VERSION ""

NS_ :

BS_:

BU_: WPC2 RLPSU DPSU APSU PSB SHVU_RR vHS_B2 FCS EMCU SLB ARS RCM CGW_CCU vDummy_HS_B ATS RLHV SGU PFSU ALBCU DSAU SWRC SHVU_FR RCS RRPSU BLTN_CAM SCM DLBCU OHCL RWPC RRHV WPC HOD ASAU

BO_ 1279 HU_USM_E_10: 8 CGW_CCU
 SG_ USM_SmartRegen_Map_Set : 11|2@1+ (1,0) [0|0] "" Vector__XXX
 SG_ USM_SmartRegen_Sens_Set : 13|3@1+ (1,0) [0|0] "" Vector__XXX
 SG_ AVN_SeatPosMemory_Btn : 16|3@1+ (1,0) [0|0] "" Vector__XXX
 SG_ AVN_SeatPosPlyBck_Btn : 19|3@1+ (1,0) [0|0] ""  DPSU
 SG_ USM_RhstaLvlEnaSetReq : 22|2@1+ (1,0) [0|0] "" Vector__XXX
 SG_ USM_CMSDayBrgtnsLvlLHSetReq : 24|4@1+ (1,0) [0|0] "" Vector__XXX
 SG_ USM_CMSNgtBrgtnsLvlLHSetReq : 28|4@1+ (1,0) [0|0] "" Vector__XXX
 SG_ USM_CMSDayBrgtnsLvlRHSetReq : 32|4@1+ (1,0) [0|0] "" Vector__XXX
 SG_ USM_CMSNgtBrgtnsLvlRHSetReq : 36|4@1+ (1,0) [0|0] "" Vector__XXX
 SG_ USM_CMSBrgtnsReset : 40|2@1+ (1,0) [0|0] "" Vector__XXX
 SG_ USM_TurnDistLnDispSetReq : 42|2@1+ (1,0) [0|0] "" Vector__XXX
 SG_ PCA_FrSd_NValueSet : 44|2@1+ (1,0) [0|0] "" Vector__XXX
 SG_ CF_AVN_1stRrStRmndNValueSet : 46|2@1+ (1,0) [0|0] "" Vector__XXX
 SG_ C_AllDrOpnNValueSet : 52|3@1+ (1,0) [0|0] "" Vector__XXX
 SG_ USM_RpmECOSet : 55|2@1+ (1,0) [0|0] "" Vector__XXX
 SG_ VESS_ChgGuideMdLvl : 57|3@1+ (1,0) [0|0] "" Vector__XXX
 SG_ Usm_RpmSPORTSet : 60|2@1+ (1,0) [0|0] "" Vector__XXX

BO_ 2328016129 VCU_05_100ms_1: 8 CGW_CCU
 SG_ VCU_Crc5Val : 0|16@1+ (1,0) [0|0] "" Vector__XXX
 SG_ VCU_AlvCnt5Val : 16|8@1+ (1,0) [0|0] "" Vector__XXX
 SG_ VCU_EvDrvRdyCluDispSta : 24|2@1+ (1,0) [0|3] ""  SWRC
 SG_ VCU_PwrDnModeSta : 26|2@1+ (1,0) [0|3] "" Vector__XXX
 SG_ VCU_CluWarnMsgSta : 28|4@1+ (1,0) [0|15] "" Vector__XXX
 SG_ VCU_DteOffDispSta : 32|2@1+ (1,0) [0|0] "flag" Vector__XXX
 SG_ VCU_LowSocAlertSta : 34|3@1+ (1,0) [0|7] "" Vector__XXX
 SG_ VCU_VcrmReq : 38|2@1+ (1,0) [0|3] "" Vector__XXX
 SG_ VCU_PdlWarnMsgSta : 40|2@1+ (1,0) [0|3] "" Vector__XXX
 SG_ VCU_AwdDiagDispSta : 42|2@1+ (1,0) [0|0] "" Vector__XXX
 SG_ VCU_AwdLockDispSta : 44|2@1+ (1,0) [0|0] "" Vector__XXX
 SG_ VCU_VirtualApsActSta : 46|2@1+ (1,0) [0|3] "" Vector__XXX
 SG_ VCU_VirtualApsVal : 48|8@1+ (0.3906,0) [0|99.61] "%" Vector__XXX
 SG_ VCU_ServiceLampReq : 56|2@1+ (1,0) [0|3] "" Vector__XXX
 SG_ VCU_ServiceModeSta : 58|2@1+ (1,0) [0|3] "" Vector__XXX
 SG_ VCU_NPosWshModSta : 60|2@1+ (1,0) [0|0] "flag" Vector__XXX
 SG_ VCU_PowerTrainType : 62|2@1+ (1,0) [0|3] "" Vector__XXX

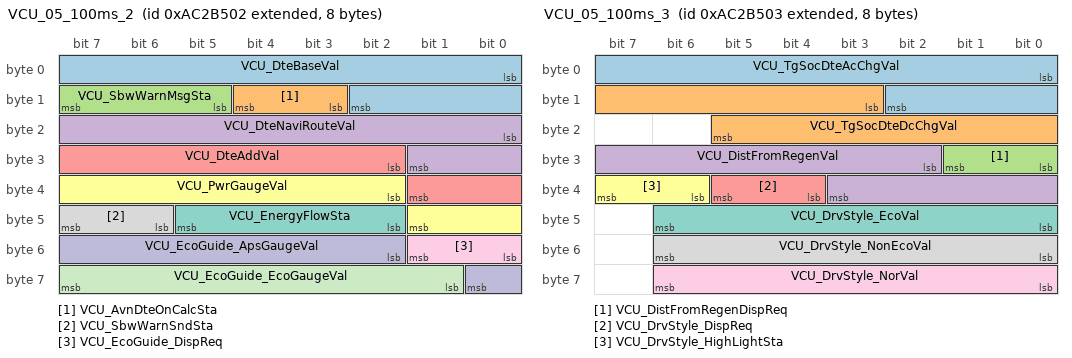
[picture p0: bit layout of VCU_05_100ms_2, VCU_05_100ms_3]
BO_ 2328016130 VCU_05_100ms_2: 8 CGW_CCU
 SG_ VCU_DteBaseVal : 0|11@1+ (1,0) [0|2047] "km" Vector__XXX
 SG_ VCU_AvnDteOnCalcSta : 11|2@1+ (1,0) [0|3] "" Vector__XXX
 SG_ VCU_SbwWarnMsgSta : 13|3@1+ (1,0) [0|0] "flag" Vector__XXX
 SG_ VCU_DteNaviRouteVal : 16|10@1+ (2,0) [0|1026] "km" Vector__XXX
 SG_ VCU_DteAddVal : 26|8@1+ (1,0) [0|255] "km" Vector__XXX
 SG_ VCU_PwrGaugeVal : 34|8@1- (1,0) [-100|100] "%" Vector__XXX
 SG_ VCU_EnergyFlowSta : 42|4@1+ (1,0) [0|15] "" Vector__XXX
 SG_ VCU_SbwWarnSndSta : 46|2@1+ (1,0) [0|0] "flag" Vector__XXX
 SG_ VCU_EcoGuide_DispReq : 48|2@1+ (1,0) [0|3] "" Vector__XXX
 SG_ VCU_EcoGuide_ApsGaugeVal : 50|7@1+ (1,0) [0|100] "%" Vector__XXX
 SG_ VCU_EcoGuide_EcoGaugeVal : 57|7@1+ (1,0) [0|100] "%" Vector__XXX

BO_ 2328016131 VCU_05_100ms_3: 8 CGW_CCU
 SG_ VCU_TgSocDteAcChgVal : 0|11@1+ (1,0) [0|2047] "km" Vector__XXX
 SG_ VCU_TgSocDteDcChgVal : 11|11@1+ (1,0) [0|2047] "km" Vector__XXX
 SG_ VCU_DistFromRegenDispReq : 24|2@1+ (1,0) [0|3] "" Vector__XXX
 SG_ VCU_DistFromRegenVal : 26|10@1+ (10,0) [0|10230] "m" Vector__XXX
 SG_ VCU_DrvStyle_DispReq : 36|2@1+ (1,0) [0|3] "" Vector__XXX
 SG_ VCU_DrvStyle_HighLightSta : 38|2@1+ (1,0) [0|3] "" Vector__XXX
 SG_ VCU_DrvStyle_EcoVal : 40|7@1+ (1,0) [0|100] "%" Vector__XXX
 SG_ VCU_DrvStyle_NonEcoVal : 48|7@1+ (1,0) [0|100] "%" Vector__XXX
 SG_ VCU_DrvStyle_NorVal : 56|7@1+ (1,0) [0|100] "%" Vector__XXX

BO_ 200 HU_USM_E_12: 8 CGW_CCU
 SG_ CF_AVN_ADrLNValueSet_2 : 0|3@1+ (1,0) [0|0] "" Vector__XXX
 SG_ CF_AVN_FCA_JC_OnOffEquipNvalueSe : 12|2@1+ (1,0) [0|0] "" Vector__XXX
 SG_ CF_AVN_FCA_FrSdOnOffEquipNvalueS : 14|2@1+ (1,0) [0|0] "" Vector__XXX
 SG_ CF_AVN_LKA_OnOffEquip2NvalueSet : 16|2@1+ (1,0) [0|0] "" Vector__XXX
 SG_ CF_AVN_BCA_OnOffEquip2NvalueSet : 18|2@1+ (1,0) [0|0] "" Vector__XXX
 SG_ CF_AVN_BVM_OnOffEquipNvalueSet : 20|2@1+ (1,0) [0|0] "" Vector__XXX
 SG_ CF_AVN_SEA_OnOffEquip3NvalueSet : 22|2@1+ (1,0) [0|0] "" Vector__XXX
 SG_ CF_AVN_BodySpprtSet_AST : 24|2@1+ (1,0) [0|0] ""  ALBCU
 SG_ CF_AVN_SEW_OnOffEquip3NvalueSet : 26|2@1+ (1,0) [0|0] "" Vector__XXX
 SG_ CF_AVN_HudImsAutoSave : 28|2@1+ (1,0) [0|0] "" Vector__XXX
 SG_ USM_PwrDrBuzzerNValueSet : 3|2@1+ (1,0) [0|0] "" Vector__XXX
 SG_ CF_AVN_DWLNValueSet : 30|3@1+ (1,0) [0|0] "" Vector__XXX
 SG_ CF_AVN_AirSptTimeNValueSet_AST : 33|3@1+ (1,0) [0|0] ""  ALBCU
 SG_ CF_AVN_AirSptStrNValue_AST : 36|2@1+ (1,0) [0|0] ""  ALBCU
 SG_ CF_AVN_SeatDrvModNvalueSet_AST : 38|2@1+ (1,0) [0|0] ""  ALBCU
 SG_ CF_AVN_TPMS_TireReplaceNValueSet : 40|3@1+ (1,0) [0|0] "" Vector__XXX
 SG_ CF_AVN_TowModeSet : 43|3@1+ (1,0) [0|0] "" Vector__XXX
 SG_ USM_PwrDrCloseByBraekNValueSet : 46|2@1+ (1,0) [0|0] "" Vector__XXX
 SG_ CF_AVN_ISLANAOffstNvalueSet : 50|3@1+ (1,0) [0|0] "" Vector__XXX
 SG_ CF_Gway_WPC2_NValueSet : 53|2@1+ (1,0) [0|0] ""  WPC2
 SG_ USM_DrvGhostDoorReq : 56|2@1+ (1,0) [0|0] "" Vector__XXX
 SG_ USM_AstGhostDoorReq : 58|2@1+ (1,0) [0|0] "" Vector__XXX
 SG_ USM_RLGhostDoorReq : 60|2@1+ (1,0) [0|0] "" Vector__XXX
 SG_ USM_RRGhostDoorReq : 62|2@1+ (1,0) [0|0] "" Vector__XXX
 SG_ CF_AVN_FCA_FrOnOffEquipNvalueSet : 7|2@1+ (1,0) [0|0] "" Vector__XXX
 SG_ CF_AVN_FCA_WarnTimeNvalueSet : 9|3@1+ (1,0) [0|0] "" Vector__XXX

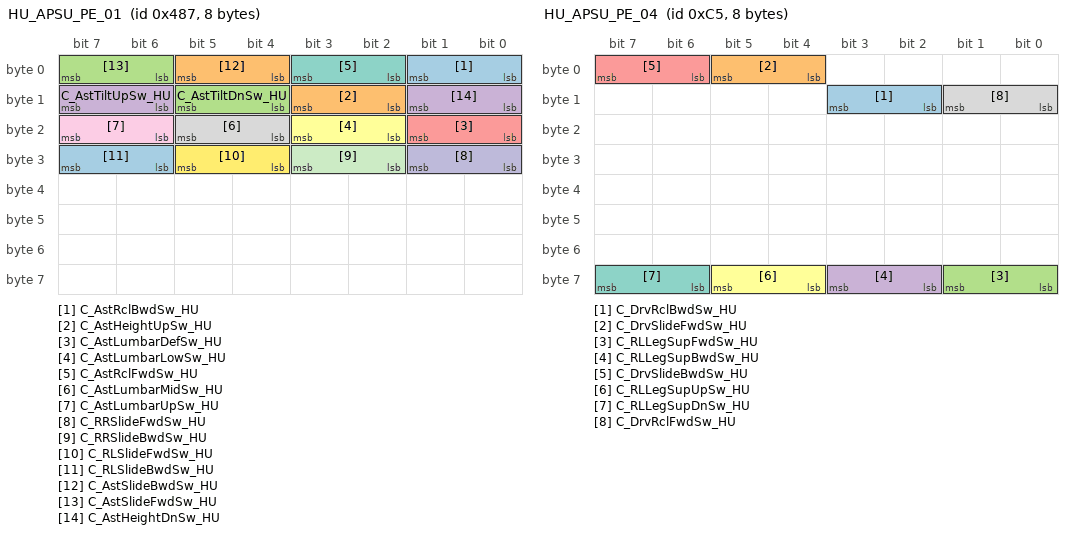
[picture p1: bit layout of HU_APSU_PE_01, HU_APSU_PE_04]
BO_ 1159 HU_APSU_PE_01: 8 CGW_CCU
 SG_ C_AstRclBwdSw_HU : 0|2@1+ (1,0) [0|0] ""  APSU
 SG_ C_AstHeightUpSw_HU : 10|2@1+ (1,0) [0|0] ""  APSU
 SG_ C_AstTiltDnSw_HU : 12|2@1+ (1,0) [0|0] ""  APSU
 SG_ C_AstTiltUpSw_HU : 14|2@1+ (1,0) [0|0] ""  APSU
 SG_ C_AstLumbarDefSw_HU : 16|2@1+ (1,0) [0|0] ""  ASAU,ALBCU
 SG_ C_AstLumbarLowSw_HU : 18|2@1+ (1,0) [0|0] ""  ASAU,ALBCU
 SG_ C_AstRclFwdSw_HU : 2|2@1+ (1,0) [0|0] ""  APSU
 SG_ C_AstLumbarMidSw_HU : 20|2@1+ (1,0) [0|0] ""  ASAU,ALBCU
 SG_ C_AstLumbarUpSw_HU : 22|2@1+ (1,0) [0|0] ""  ASAU,ALBCU
 SG_ C_RRSlideFwdSw_HU : 24|2@1+ (1,0) [0|0] ""  APSU,RRPSU
 SG_ C_RRSlideBwdSw_HU : 26|2@1+ (1,0) [0|0] ""  APSU,RRPSU
 SG_ C_RLSlideFwdSw_HU : 28|2@1+ (1,0) [0|0] ""  APSU,RRPSU,RLPSU
 SG_ C_RLSlideBwdSw_HU : 30|2@1+ (1,0) [0|0] ""  APSU,RRPSU,RLPSU
 SG_ C_AstSlideBwdSw_HU : 4|2@1+ (1,0) [0|0] ""  APSU
 SG_ C_AstSlideFwdSw_HU : 6|2@1+ (1,0) [0|0] ""  APSU
 SG_ C_AstHeightDnSw_HU : 8|2@1+ (1,0) [0|0] ""  APSU

BO_ 197 HU_APSU_PE_04: 8 CGW_CCU
 SG_ C_DrvRclBwdSw_HU : 10|2@1+ (1,0) [0|0] ""  DPSU
 SG_ C_DrvSlideFwdSw_HU : 4|2@1+ (1,0) [0|0] ""  DPSU
 SG_ C_RLLegSupFwdSw_HU : 56|2@1+ (1,0) [0|0] ""  APSU,RLPSU
 SG_ C_RLLegSupBwdSw_HU : 58|2@1+ (1,0) [0|0] ""  APSU,RLPSU
 SG_ C_DrvSlideBwdSw_HU : 6|2@1+ (1,0) [0|0] ""  DPSU
 SG_ C_RLLegSupUpSw_HU : 60|2@1+ (1,0) [0|0] ""  APSU,RLPSU
 SG_ C_RLLegSupDnSw_HU : 62|2@1+ (1,0) [0|0] ""  APSU,RLPSU
 SG_ C_DrvRclFwdSw_HU : 8|2@1+ (1,0) [0|0] ""  DPSU

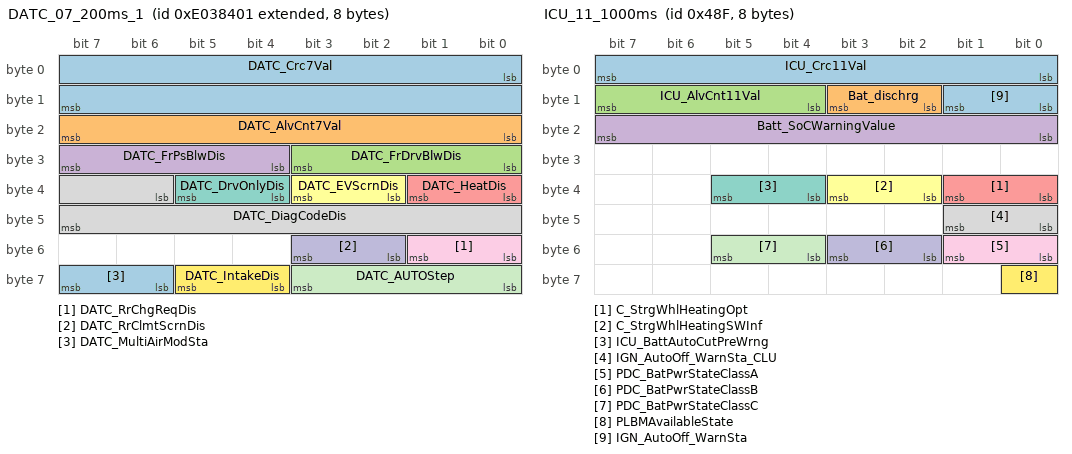
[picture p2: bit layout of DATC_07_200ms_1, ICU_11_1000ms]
BO_ 2382595073 DATC_07_200ms_1: 8 CGW_CCU
 SG_ DATC_Crc7Val : 0|16@1+ (1,0) [0|0] "" Vector__XXX
 SG_ DATC_AlvCnt7Val : 16|8@1+ (1,0) [0|0] "" Vector__XXX
 SG_ DATC_FrDrvBlwDis : 24|4@1+ (1,0) [0|0] ""  ATS
 SG_ DATC_FrPsBlwDis : 28|4@1+ (1,0) [0|0] ""  ATS
 SG_ DATC_HeatDis : 32|2@1+ (1,0) [0|0] "flag"  ATS
 SG_ DATC_EVScrnDis : 34|2@1+ (1,0) [0|0] "" Vector__XXX
 SG_ DATC_DrvOnlyDis : 36|2@1+ (1,0) [0|0] ""  ATS
 SG_ DATC_DiagCodeDis : 38|10@1+ (1,-1) [0|0] "" Vector__XXX
 SG_ DATC_RrChgReqDis : 48|2@1+ (1,0) [0|0] "" Vector__XXX
 SG_ DATC_RrClmtScrnDis : 50|2@1+ (1,0) [0|0] ""  ATS
 SG_ DATC_AUTOStep : 56|4@1+ (1,0) [0|0] ""  ATS
 SG_ DATC_IntakeDis : 60|2@1+ (1,0) [0|0] ""  ATS
 SG_ DATC_MultiAirModSta : 62|2@1+ (1,0) [0|0] "" Vector__XXX

BO_ 1167 ICU_11_1000ms: 8 CGW_CCU
 SG_ ICU_Crc11Val : 0|8@1+ (1,0) [0|0] "" Vector__XXX
 SG_ Bat_dischrg : 10|2@1+ (1,0) [0|0] "" Vector__XXX
 SG_ ICU_AlvCnt11Val : 12|4@1+ (1,0) [0|0] "" Vector__XXX
 SG_ Batt_SoCWarningValue : 16|8@1+ (1,0) [0|0] "%" Vector__XXX
 SG_ C_StrgWhlHeatingOpt : 32|2@1+ (1,0) [0|0] "" Vector__XXX
 SG_ C_StrgWhlHeatingSWInf : 34|2@1+ (1,0) [0|0] "" Vector__XXX
 SG_ ICU_BattAutoCutPreWrng : 36|2@1+ (1,0) [0|0] ""  BLTN_CAM
 SG_ IGN_AutoOff_WarnSta_CLU : 40|2@1+ (1,0) [0|0] "" Vector__XXX
 SG_ PDC_BatPwrStateClassA : 48|2@1+ (1,0) [0|0] "" Vector__XXX
 SG_ PDC_BatPwrStateClassB : 50|2@1+ (1,0) [0|0] "" Vector__XXX
 SG_ PDC_BatPwrStateClassC : 52|2@1+ (1,0) [0|0] "" Vector__XXX
 SG_ PLBMAvailableState : 56|1@1+ (1,0) [0|0] "" Vector__XXX
 SG_ IGN_AutoOff_WarnSta : 8|2@1+ (1,0) [0|0] "" Vector__XXX

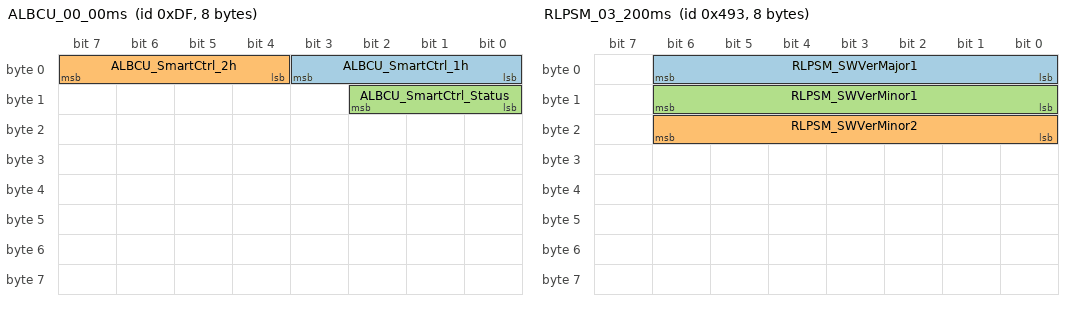
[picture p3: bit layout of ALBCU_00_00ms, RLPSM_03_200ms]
BO_ 223 ALBCU_00_00ms: 8 ALBCU
 SG_ ALBCU_SmartCtrl_1h : 0|4@1+ (1,0) [0|0] ""  CGW_CCU
 SG_ ALBCU_SmartCtrl_2h : 4|4@1+ (1,0) [0|0] ""  CGW_CCU
 SG_ ALBCU_SmartCtrl_Status : 8|3@1+ (1,0) [0|0] ""  CGW_CCU

BO_ 1171 RLPSM_03_200ms: 8 RLPSU
 SG_ RLPSM_SWVerMajor1 : 0|7@1+ (1,0) [0|0] "" Vector__XXX
 SG_ RLPSM_SWVerMinor2 : 16|7@1+ (1,0) [0|0] "" Vector__XXX
 SG_ RLPSM_SWVerMinor1 : 8|7@1+ (1,0) [0|0] "" Vector__XXX

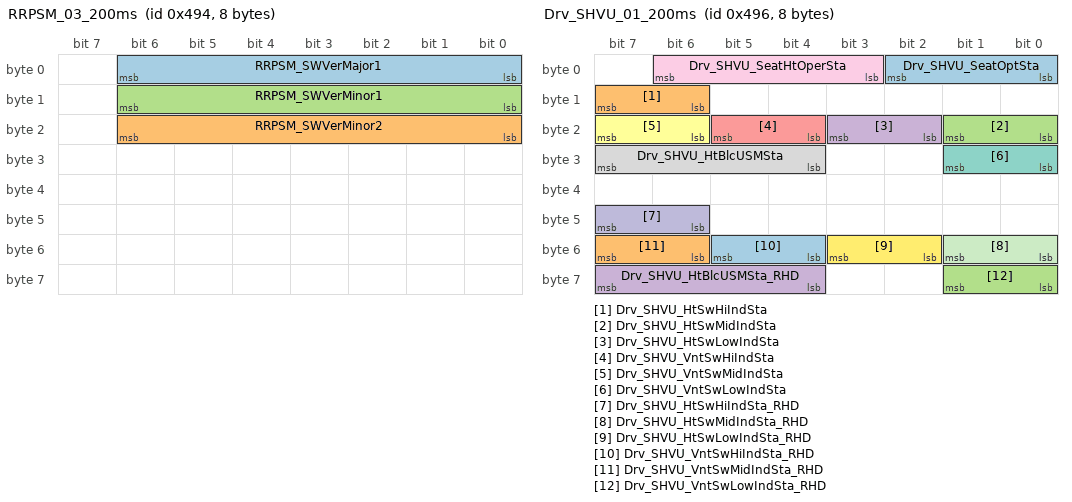
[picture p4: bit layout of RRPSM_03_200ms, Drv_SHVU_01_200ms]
BO_ 1172 RRPSM_03_200ms: 8 RRPSU
 SG_ RRPSM_SWVerMajor1 : 0|7@1+ (1,0) [0|0] "" Vector__XXX
 SG_ RRPSM_SWVerMinor2 : 16|7@1+ (1,0) [0|0] "" Vector__XXX
 SG_ RRPSM_SWVerMinor1 : 8|7@1+ (1,0) [0|0] "" Vector__XXX

BO_ 1174 Drv_SHVU_01_200ms: 8 DPSU
 SG_ Drv_SHVU_SeatOptSta : 0|3@1+ (1,0) [0|0] ""  FCS,CGW_CCU
 SG_ Drv_SHVU_HtSwHiIndSta : 14|2@1+ (1,0) [0|0] ""  FCS,CGW_CCU
 SG_ Drv_SHVU_HtSwMidIndSta : 16|2@1+ (1,0) [0|0] ""  FCS,CGW_CCU
 SG_ Drv_SHVU_HtSwLowIndSta : 18|2@1+ (1,0) [0|0] ""  FCS,CGW_CCU
 SG_ Drv_SHVU_VntSwHiIndSta : 20|2@1+ (1,0) [0|0] ""  FCS,CGW_CCU
 SG_ Drv_SHVU_VntSwMidIndSta : 22|2@1+ (1,0) [0|0] ""  FCS,CGW_CCU
 SG_ Drv_SHVU_VntSwLowIndSta : 24|2@1+ (1,0) [0|0] ""  FCS,CGW_CCU
 SG_ Drv_SHVU_HtBlcUSMSta : 28|4@1+ (1,0) [0|0] ""  CGW_CCU
 SG_ Drv_SHVU_SeatHtOperSta : 3|4@1+ (1,0) [0|0] ""  FCS,CGW_CCU
 SG_ Drv_SHVU_HtSwHiIndSta_RHD : 46|2@1+ (1,0) [0|0] ""  FCS,CGW_CCU
 SG_ Drv_SHVU_HtSwMidIndSta_RHD : 48|2@1+ (1,0) [0|0] ""  FCS,CGW_CCU
 SG_ Drv_SHVU_HtSwLowIndSta_RHD : 50|2@1+ (1,0) [0|0] ""  FCS,CGW_CCU
 SG_ Drv_SHVU_VntSwHiIndSta_RHD : 52|2@1+ (1,0) [0|0] ""  FCS,CGW_CCU
 SG_ Drv_SHVU_VntSwMidIndSta_RHD : 54|2@1+ (1,0) [0|0] ""  FCS,CGW_CCU
 SG_ Drv_SHVU_VntSwLowIndSta_RHD : 56|2@1+ (1,0) [0|0] ""  FCS,CGW_CCU
 SG_ Drv_SHVU_HtBlcUSMSta_RHD : 60|4@1+ (1,0) [0|0] "" Vector__XXX

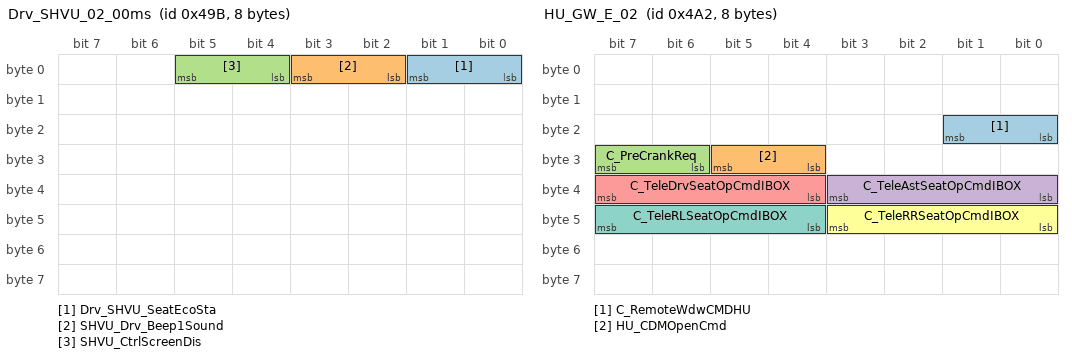
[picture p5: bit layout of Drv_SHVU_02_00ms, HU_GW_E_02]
BO_ 1179 Drv_SHVU_02_00ms: 8 SHVU_FR
 SG_ Drv_SHVU_SeatEcoSta : 0|2@1+ (1,0) [0|0] ""  CGW_CCU
 SG_ SHVU_Drv_Beep1Sound : 2|2@1+ (1,0) [0|0] ""  CGW_CCU
 SG_ SHVU_CtrlScreenDis : 4|2@1+ (1,0) [0|0] ""  CGW_CCU

BO_ 1180 Ast_SHVU_02_00ms: 8 SHVU_FR
 SG_ SHVU_Ast_Beep1Sound : 2|2@1+ (1,0) [0|0] ""  CGW_CCU
 SG_ Ast_SHVU_SeatEcoSta : 26|2@1+ (1,0) [0|0] ""  CGW_CCU

BO_ 208 RR_SHVU_03_200ms: 8 SHVU_RR
 SG_ RR_SHVU_DTCdisplay : 0|8@1+ (1,0) [0|0] ""  ATS
 SG_ RR_SHVU_DiagMode : 8|2@1+ (1,0) [0|0] ""  ATS

BO_ 1181 RL_SHVU_02_00ms: 8 RLHV
 SG_ RL_SHVU_SeatEcoSta : 0|2@1+ (1,0) [0|0] ""  ATS,CGW_CCU

BO_ 1182 RR_SHVU_02_00ms: 8 SHVU_RR
 SG_ RR_SHVU_SeatEcoSta : 0|2@1+ (1,0) [0|0] ""  ATS,CGW_CCU

BO_ 1186 HU_GW_E_02: 8 CGW_CCU
 SG_ C_RemoteWdwCMDHU : 16|2@1+ (1,0) [0|0] "" Vector__XXX
 SG_ HU_CDMOpenCmd : 28|2@1+ (1,0) [0|0] "" Vector__XXX
 SG_ C_PreCrankReq : 30|2@1+ (1,0) [0|0] ""  BLTN_CAM
 SG_ C_TeleAstSeatOpCmdIBOX : 32|4@1+ (1,0) [0|0] ""  APSU,SHVU_FR
 SG_ C_TeleDrvSeatOpCmdIBOX : 36|4@1+ (1,0) [0|0] ""  SHVU_FR,DPSU
 SG_ C_TeleRRSeatOpCmdIBOX : 40|4@1+ (1,0) [0|0] ""  RRHV,SHVU_FR,SHVU_RR,RRPSU,ATS
 SG_ C_TeleRLSeatOpCmdIBOX : 44|4@1+ (1,0) [0|0] ""  RLHV,SHVU_FR,SHVU_RR,RLPSU,ATS

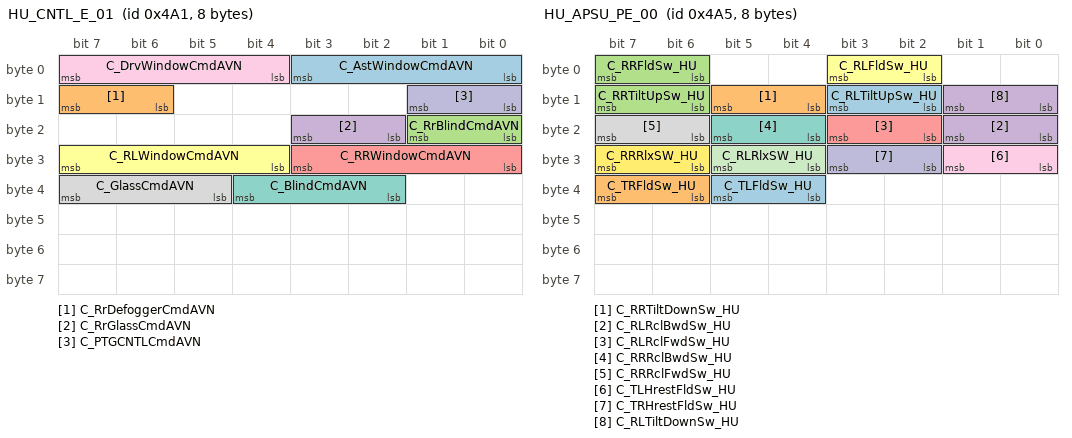
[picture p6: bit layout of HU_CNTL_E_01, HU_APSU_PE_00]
BO_ 1185 HU_CNTL_E_01: 8 CGW_CCU
 SG_ C_AstWindowCmdAVN : 0|4@1+ (1,0) [0|0] "" Vector__XXX
 SG_ C_RrDefoggerCmdAVN : 14|2@1+ (1,0) [0|0] "" Vector__XXX
 SG_ C_RrBlindCmdAVN : 16|2@1+ (1,0) [0|0] ""  RCM
 SG_ C_RrGlassCmdAVN : 18|2@1+ (1,0) [0|0] ""  RCM
 SG_ C_RRWindowCmdAVN : 24|4@1+ (1,0) [0|0] "" Vector__XXX
 SG_ C_RLWindowCmdAVN : 28|4@1+ (1,0) [0|0] "" Vector__XXX
 SG_ C_BlindCmdAVN : 34|3@1+ (1,0) [0|0] ""  RCM
 SG_ C_GlassCmdAVN : 37|3@1+ (1,0) [0|0] ""  RCM
 SG_ C_DrvWindowCmdAVN : 4|4@1+ (1,0) [0|0] "" Vector__XXX
 SG_ C_PTGCNTLCmdAVN : 8|2@1+ (1,0) [0|0] "" Vector__XXX

BO_ 1189 HU_APSU_PE_00: 8 CGW_CCU
 SG_ C_RLTiltUpSw_HU : 10|2@1+ (1,0) [0|0] ""  APSU,RRPSU,RLPSU
 SG_ C_RRTiltDownSw_HU : 12|2@1+ (1,0) [0|0] ""  APSU,RRPSU
 SG_ C_RRTiltUpSw_HU : 14|2@1+ (1,0) [0|0] ""  APSU,RRPSU
 SG_ C_RLRclBwdSw_HU : 16|2@1+ (1,0) [0|0] ""  APSU,RRPSU,RLPSU
 SG_ C_RLRclFwdSw_HU : 18|2@1+ (1,0) [0|0] ""  APSU,RRPSU,RLPSU
 SG_ C_RLFldSw_HU : 2|2@1+ (1,0) [0|0] ""  RLPSU
 SG_ C_RRRclBwdSw_HU : 20|2@1+ (1,0) [0|0] ""  APSU,RRPSU
 SG_ C_RRRclFwdSw_HU : 22|2@1+ (1,0) [0|0] ""  APSU,RRPSU
 SG_ C_TLHrestFldSw_HU : 24|2@1+ (1,0) [0|0] ""  PFSU
 SG_ C_TRHrestFldSw_HU : 26|2@1+ (1,0) [0|0] ""  PFSU
 SG_ C_RLRlxSW_HU : 28|2@1+ (1,0) [0|0] ""  RRPSU,RLPSU
 SG_ C_RRRlxSW_HU : 30|2@1+ (1,0) [0|0] ""  RRPSU
 SG_ C_TLFldSw_HU : 36|2@1+ (1,0) [0|0] ""  PFSU
 SG_ C_TRFldSw_HU : 38|2@1+ (1,0) [0|0] ""  PFSU
 SG_ C_RRFldSw_HU : 6|2@1+ (1,0) [0|0] ""  RRPSU
 SG_ C_RLTiltDownSw_HU : 8|2@1+ (1,0) [0|0] ""  APSU,RRPSU,RLPSU

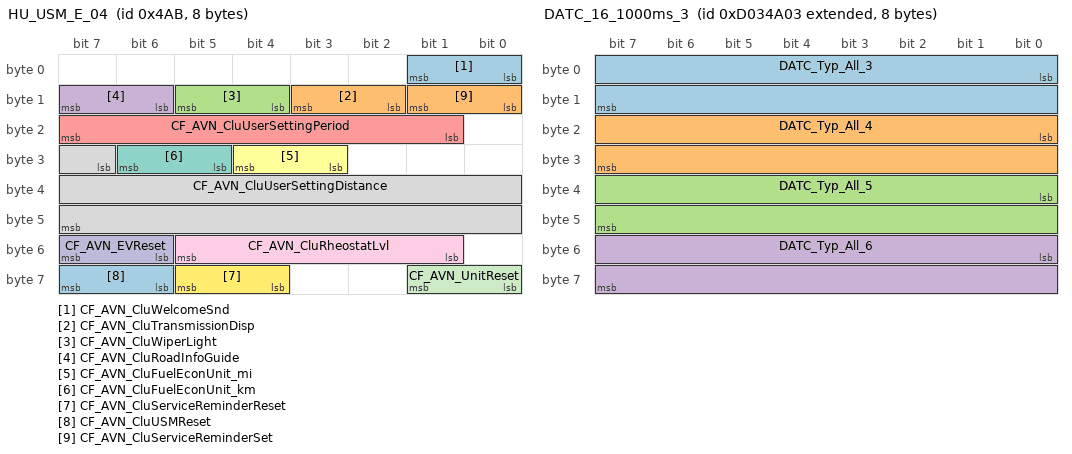
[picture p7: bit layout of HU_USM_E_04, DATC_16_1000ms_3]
BO_ 1195 HU_USM_E_04: 8 CGW_CCU
 SG_ CF_AVN_CluWelcomeSnd : 0|2@1+ (1,0) [0|0] "" Vector__XXX
 SG_ CF_AVN_CluTransmissionDisp : 10|2@1+ (1,0) [0|0] "" Vector__XXX
 SG_ CF_AVN_CluWiperLight : 12|2@1+ (1,0) [0|0] "" Vector__XXX
 SG_ CF_AVN_CluRoadInfoGuide : 14|2@1+ (1,0) [0|0] "" Vector__XXX
 SG_ CF_AVN_CluUserSettingPeriod : 17|7@1+ (1,0) [0|0] "" Vector__XXX
 SG_ CF_AVN_CluFuelEconUnit_mi : 27|2@1+ (1,0) [0|0] "" Vector__XXX
 SG_ CF_AVN_CluFuelEconUnit_km : 29|2@1+ (1,0) [0|0] "" Vector__XXX
 SG_ CF_AVN_CluUserSettingDistance : 31|17@1+ (1,0) [0|0] "" Vector__XXX
 SG_ CF_AVN_CluRheostatLvl : 49|5@1+ (1,0) [0|0] "" Vector__XXX
 SG_ CF_AVN_EVReset : 54|2@1+ (1,0) [0|0] "" Vector__XXX
 SG_ CF_AVN_UnitReset : 56|2@1+ (1,0) [0|0] "" Vector__XXX
 SG_ CF_AVN_CluServiceReminderReset : 60|2@1+ (1,0) [0|0] "" Vector__XXX
 SG_ CF_AVN_CluUSMReset : 62|2@1+ (1,0) [0|0] ""  WPC,RWPC,SLB,ARS,APSU,RLHV,RRHV,SHVU_FR,SHVU_RR,DPSU,DLBCU,PFSU,RRPSU,RLPSU,ATS,DSAU,ASAU,RCM,BLTN_CAM,SGU,ALBCU,WPC2
 SG_ CF_AVN_CluServiceReminderSet : 8|2@1+ (1,0) [0|0] "" Vector__XXX

BO_ 1193 HU_USM_E_02: 8 CGW_CCU
 SG_ C_PTGMNValueSet : 0|2@1+ (1,0) [0|0] "" Vector__XXX
 SG_ CF_AVN_PSMNValueSet : 10|3@1+ (1,0) [0|0] ""  DPSU
 SG_ C_HfreeTrunkTgNValueSet : 13|3@1+ (1,0) [0|0] "" Vector__XXX
 SG_ CF_AVN_TrfChgSet : 17|2@1+ (1,0) [0|0] "" Vector__XXX
 SG_ CF_AVN_SCMNValueSet : 19|2@1+ (1,0) [0|0] "" Vector__XXX
 SG_ CF_AVN_ADrUNValueSet : 2|3@1+ (1,0) [0|0] "" Vector__XXX
 SG_ CF_AVN_OTTurnNValueSet : 21|3@1+ (1,0) [0|0] "" Vector__XXX
 SG_ CF_Gway_WPCNValueSet : 24|2@1+ (1,0) [0|0] ""  WPC,WPC2
 SG_ C_AVN_RearWiperNValueSet : 26|2@1+ (1,0) [0|0] "" Vector__XXX
 SG_ C_UnlockWelocomeNValueSet : 28|2@1+ (1,0) [0|0] "" Vector__XXX
 SG_ C_SmartWelocomeNValueSet : 30|2@1+ (1,0) [0|0] "" Vector__XXX
 SG_ CF_AVN_PTGSpeedNValueSet : 32|2@1+ (1,0) [0|0] "" Vector__XXX
 SG_ CR_Datc_DRSeatWheel_USM_Set : 34|2@1+ (1,0) [0|0] "" Vector__XXX
 SG_ CF_AVN_TTUnlockNValueSet : 38|2@1+ (1,0) [0|0] "" Vector__XXX
 SG_ CF_Gway_RWPCNValueSet : 40|2@1+ (1,0) [0|0] ""  RWPC
 SG_ CF_Avn_HAPTICWARNINGNValueSet : 49|3@1+ (1,0) [0|0] "" Vector__XXX
 SG_ CR_Datc_DRSeatHeat_USM_Set : 52|2@1+ (1,0) [0|0] "" Vector__XXX
 SG_ C_WALNValueSet : 54|2@1+ (1,0) [0|0] "" Vector__XXX
 SG_ C_ApprUnlockNValue : 56|2@1+ (1,0) [0|0] "" Vector__XXX
 SG_ CF_AVN_EscortHLNValueSet : 8|2@1+ (1,0) [0|0] "" Vector__XXX

BO_ 2365803012 DATC_16_1000ms_4: 8 CGW_CCU
 SG_ DATC_Opt_Sys : 0|32@1+ (1,0) [0|0] "" Vector__XXX
 SG_ DATC_Opt_Func : 32|32@1+ (1,0) [0|0] "" Vector__XXX

BO_ 2365803011 DATC_16_1000ms_3: 8 CGW_CCU
 SG_ DATC_Typ_All_3 : 0|16@1+ (1,0) [0|0] "" Vector__XXX
 SG_ DATC_Typ_All_4 : 16|16@1+ (1,0) [0|0] "" Vector__XXX
 SG_ DATC_Typ_All_5 : 32|16@1+ (1,0) [0|0] "" Vector__XXX
 SG_ DATC_Typ_All_6 : 48|16@1+ (1,0) [0|0] "" Vector__XXX

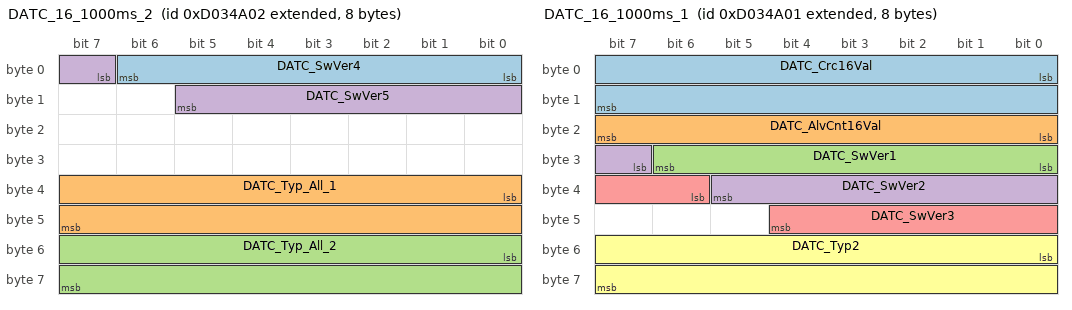
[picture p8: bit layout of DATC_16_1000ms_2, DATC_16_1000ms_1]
BO_ 2365803010 DATC_16_1000ms_2: 8 CGW_CCU
 SG_ DATC_SwVer4 : 0|7@1+ (1,0) [0|0] "" Vector__XXX
 SG_ DATC_Typ_All_1 : 32|16@1+ (1,0) [0|0] "" Vector__XXX
 SG_ DATC_Typ_All_2 : 48|16@1+ (1,0) [0|0] "" Vector__XXX
 SG_ DATC_SwVer5 : 7|7@1+ (1,0) [0|0] "" Vector__XXX

BO_ 2365803009 DATC_16_1000ms_1: 8 CGW_CCU
 SG_ DATC_Crc16Val : 0|16@1+ (1,0) [0|0] "" Vector__XXX
 SG_ DATC_AlvCnt16Val : 16|8@1+ (1,0) [0|0] "" Vector__XXX
 SG_ DATC_SwVer1 : 24|7@1+ (1,0) [0|0] "" Vector__XXX
 SG_ DATC_SwVer2 : 31|7@1+ (1,0) [0|0] "" Vector__XXX
 SG_ DATC_SwVer3 : 38|7@1+ (1,0) [0|0] "" Vector__XXX
 SG_ DATC_Typ2 : 48|16@1+ (1,0) [0|0] ""  ATS

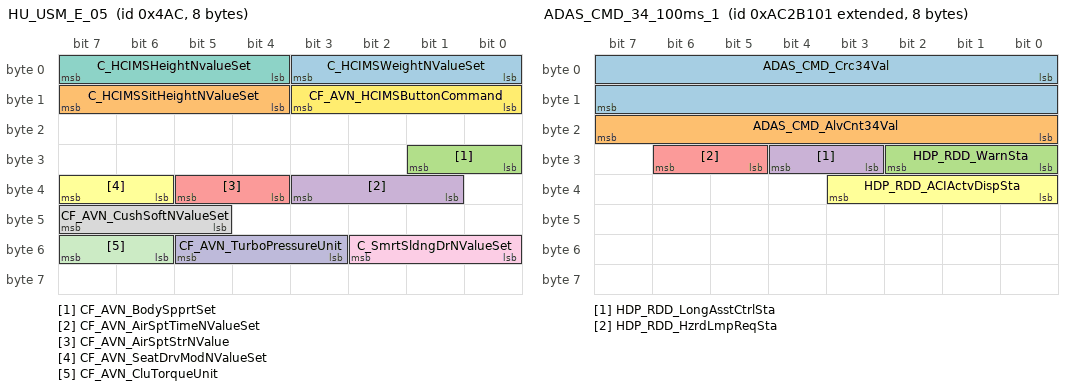
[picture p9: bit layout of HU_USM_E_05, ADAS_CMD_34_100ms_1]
BO_ 1196 HU_USM_E_05: 8 CGW_CCU
 SG_ C_HCIMSWeightNValueSet : 0|4@1+ (1,0) [0|0] ""  DPSU
 SG_ C_HCIMSSitHeightNValueSet : 12|4@1+ (1,0) [0|0] ""  DPSU
 SG_ CF_AVN_BodySpprtSet : 24|2@1+ (1,0) [0|0] ""  DLBCU,DSAU
 SG_ CF_AVN_AirSptTimeNValueSet : 33|3@1+ (1,0) [0|0] ""  DLBCU
 SG_ CF_AVN_AirSptStrNValue : 36|2@1+ (1,0) [0|0] ""  DLBCU
 SG_ CF_AVN_SeatDrvModNValueSet : 38|2@1+ (1,0) [0|0] ""  DLBCU,DSAU
 SG_ C_HCIMSHeightNvalueSet : 4|4@1+ (1,0) [0|0] ""  DPSU
 SG_ CF_AVN_CushSoftNValueSet : 45|3@1+ (1,0) [0|0] ""  DLBCU
 SG_ C_SmrtSldngDrNValueSet : 48|3@1+ (1,0) [0|0] "" Vector__XXX
 SG_ CF_AVN_TurboPressureUnit : 51|3@1+ (1,0) [0|0] "" Vector__XXX
 SG_ CF_AVN_CluTorqueUnit : 54|2@1+ (1,0) [0|0] "" Vector__XXX
 SG_ CF_AVN_HCIMSButtonCommand : 8|4@1+ (1,0) [0|0] ""  DPSU

BO_ 2328015108 ADAS_CMD_34_100ms_4: 8 CGW_CCU

BO_ 255 BCM_20_200ms: 8 CGW_CCU
 SG_ BCM_Crc20Val : 0|8@1+ (1,0) [0|0] "" Vector__XXX
 SG_ BCM_AlvCnt20Val : 12|4@1+ (1,0) [0|0] "" Vector__XXX
 SG_ BckGls_RrGlsHtdOnCmd : 16|2@1+ (1,0) [0|0] "" Vector__XXX
 SG_ Wndshld_FrtGlsHtdOnCmd : 18|2@1+ (1,0) [0|0] "" Vector__XXX
 SG_ Mirror_MirFldOpt : 20|2@1+ (1,0) [0|0] "" Vector__XXX
 SG_ Window_AsstPwrWdwSunroofEnblSta : 22|2@1+ (1,0) [0|0] ""  RCM
 SG_ Window_RrPwrWdwEnblSta : 24|2@1+ (1,0) [0|0] "" Vector__XXX
 SG_ Window_RrPwrWdwLkInd : 26|2@1+ (1,0) [0|0] "" Vector__XXX
 SG_ Window_DrvPwrWdwCmd : 28|2@1+ (1,0) [0|0] "" Vector__XXX
 SG_ Window_AsstPwrWdwCmd : 30|2@1+ (1,0) [0|0] "" Vector__XXX
 SG_ Window_RrLftPwrWdwCmd : 32|2@1+ (1,0) [0|0] "" Vector__XXX
 SG_ Window_RrRtPwrWdwCmd : 34|2@1+ (1,0) [0|0] "" Vector__XXX
 SG_ Mirror_FldUnfldCmd : 36|2@1+ (1,0) [0|0] "" Vector__XXX
 SG_ Mirror_FldCtrlSta : 38|2@1+ (1,0) [0|0] "" Vector__XXX
 SG_ Mirror_UnFldCtrlSta : 40|2@1+ (1,0) [0|0] "" Vector__XXX
 SG_ Mirror_PosMnlCmd : 42|3@1+ (1,0) [0|0] "" Vector__XXX
 SG_ Mirror_SelSwIndCmd : 45|3@1+ (1,0) [0|0] "" Vector__XXX
 SG_ BCM_SafetyWdwOptTyp2 : 49|3@1+ (1,0) [0|0] "" Vector__XXX
 SG_ Mirror_LHOSMirPlyBckSta : 52|4@1+ (1,0) [0|0] ""  DPSU
 SG_ Mirror_RHOSMirPlyBckSta : 56|4@1+ (1,0) [0|0] ""  DPSU
 SG_ Mirror_SelSwSta : 60|3@1+ (1,0) [0|0] "" Vector__XXX
 SG_ BckGls_RrGlsHtdOpt : 8|2@1+ (1,0) [0|0] "" Vector__XXX

BO_ 2328015105 ADAS_CMD_34_100ms_1: 8 CGW_CCU
 SG_ ADAS_CMD_Crc34Val : 0|16@1+ (1,0) [0|0] "" Vector__XXX
 SG_ ADAS_CMD_AlvCnt34Val : 16|8@1+ (1,0) [0|0] "" Vector__XXX
 SG_ HDP_RDD_WarnSta : 24|3@1+ (1,0) [0|0] ""  PSB,HOD
 SG_ HDP_RDD_LongAsstCtrlSta : 27|2@1+ (1,0) [0|0] "" Vector__XXX
 SG_ HDP_RDD_HzrdLmpReqSta : 29|2@1+ (1,0) [0|0] "" Vector__XXX
 SG_ HDP_RDD_ACIActvDispSta : 32|4@1+ (1,0) [0|0] "" Vector__XXX

BO_ 2328015106 ADAS_CMD_34_100ms_2: 8 CGW_CCU
 SG_ HDP_RDD_EMStbltActvReqSta : 8|3@1+ (1,0) [0|0] ""  PSB

BO_ 2328015107 ADAS_CMD_34_100ms_3: 8 CGW_CCU

BO_TX_BU_ 1174 : DPSU,SHVU_FR,APSU;
BO_TX_BU_ 1179 : SHVU_FR,APSU;
BO_TX_BU_ 208 : SHVU_RR,RRHV,SHVU_FR;
BO_TX_BU_ 1181 : RLHV,SHVU_FR,RLPSU,SHVU_RR;
BO_TX_BU_ 1182 : SHVU_RR,RRHV,SHVU_FR,RRPSU;
CM_ BO_ 1279 "[EC] On Event and On Change";
CM_ SG_ 1279 USM_SmartRegen_Map_Set "Smart Regeneration 2.0 Map information USM User set signal";
CM_ SG_ 1279 USM_SmartRegen_Sens_Set "Smart Regeneration User Personality of Reduction Set Signal";
CM_ SG_ 1279 AVN_SeatPosMemory_Btn "Seat position save signal";
CM_ SG_ 1279 AVN_SeatPosPlyBck_Btn "Seat position move signal";
CM_ SG_ 1279 USM_CMSBrgtnsReset "CMS Brightness Reset (LH/RH)";
CM_ SG_ 1279 CF_AVN_1stRrStRmndNValueSet "This signal is for setting the ROA function when IBU control ROA Function.";
CM_ SG_ 1279 VESS_ChgGuideMdLvl "Releated to VESS Alarm Sound Level";
CM_ BO_ 2328016129 "[P] Periodic";
CM_ SG_ 2328016129 VCU_Crc5Val "VCU_CyclicRedundancyCheck5Value";
CM_ SG_ 2328016129 VCU_AlvCnt5Val "VCU_AliveCounter5Value";
CM_ SG_ 2328016129 VCU_EvDrvRdyCluDispSta "VCU_EvDriveReadyClusterDisplayStatus ##2G##VCU - VCU1 - CF_Vcu_EvRdyClu";
CM_ SG_ 2328016129 VCU_PwrDnModeSta "VCU_PowerDownModeStatus ##2G##VCU - VCU5 - CF_Vcu_PwrDnMode";
CM_ SG_ 2328016129 VCU_CluWarnMsgSta "VCU_ClusterWarningMessageStatus ##2G##VCU - VCU7 - CF_Vcu_WarnMsg";
CM_ SG_ 2328016129 VCU_DteOffDispSta "VCU_DteOffDisplayStatus ##2G##VCU - VCU5 - CF_Vcu_DteOff";
CM_ SG_ 2328016129 VCU_LowSocAlertSta "VCU_LowSocAlertStatus ##2G##VCU - VCU3 - CF_Vcu_LowSocAlert";
CM_ SG_ 2328016129 VCU_VcrmReq "VCU_VcrmRequest ##2G##VCU - VCU3 - CF_Vcu_Vcrm_Req";
CM_ SG_ 2328016129 VCU_PdlWarnMsgSta "VCU_PaddleWarningMassageStatus";
CM_ SG_ 2328016129 VCU_AwdDiagDispSta "VCU_AwdDiagnosisDisplayStatus";
CM_ SG_ 2328016129 VCU_AwdLockDispSta "VCU_AwdLockDisplayStatus";
CM_ SG_ 2328016129 VCU_VirtualApsActSta "VCU_VirtualApsActivatedStatus ##2G##VCU - VCU1 - CF_Vcu_EstApsSel";
CM_ SG_ 2328016129 VCU_VirtualApsVal "VCU_VirtualApsValue ##2G##VCU - VCU1 - CR_Vcu_EstAccPed_PC";
CM_ SG_ 2328016129 VCU_ServiceLampReq "VCU_SeviceLampRequest ##2G##VCU - VCU5 - CF_Vcu_SerLamp";
CM_ SG_ 2328016129 VCU_ServiceModeSta "VCU_ServiceModeStatus ##2G##VCU - VCU2 - CF_Vcu_ServiceMod";
CM_ SG_ 2328016129 VCU_NPosWshModSta "VCU_NPositionWashModeStatus";
CM_ SG_ 2328016129 VCU_PowerTrainType "VCU_PowerTrainType";
CM_ BO_ 2328016130 "[P] Periodic";
CM_ SG_ 2328016130 VCU_DteBaseVal "VCU_DteBaseValue ##2G##VCU - VCU1 - CR_Vcu_DistEmpty_km(VCU6 - CR_Vcu_DistEmpty_km)";
CM_ SG_ 2328016130 VCU_AvnDteOnCalcSta "VCU_AvnDteOnCalculationStatus ##2G##VCU - VCU1 - CF_Vcu_AvnDteCalc(VCU6 - CF_Vcu_AvnDteCalc)";
CM_ SG_ 2328016130 VCU_SbwWarnMsgSta "VCU_SbwWarningMessageStatus ##2G##VCU - VCU20 - CF_Vcu_SbwWarnMsg";
CM_ SG_ 2328016130 VCU_DteNaviRouteVal "VCU_DteNaviRouteValue ##2G##VCU - VCU3 - CR_Vcu_DistEmptyAvn_km";
CM_ SG_ 2328016130 VCU_DteAddVal "VCU_DteAddedValue ##2G##VCU - VCU1 - CR_Vcu_DistEmptyAdd_km(VCU6 - CR_Vcu_DistEmptyAdd_km)";
CM_ SG_ 2328016130 VCU_PwrGaugeVal "VCU_PowerGaugeValue ##2G##VCU - VCU5 - CR_Vcu_TqMotClu_Pc";
CM_ SG_ 2328016130 VCU_EnergyFlowSta "VCU_EnergyFlowStatus ##2G##VCU - VCU5 - CF_Vcu_EvMod";
CM_ SG_ 2328016130 VCU_SbwWarnSndSta "VCU_SbwWarningSoundStatus ##2G##VCU - VCU20 - CF_Vcu_SbwWarnSnd";
CM_ SG_ 2328016130 VCU_EcoGuide_DispReq "VCU_EcoGuide_DisplayRequest ##2G##VCU - VCU7 - CF_Vcu_SmartEcoDisp";
CM_ SG_ 2328016130 VCU_EcoGuide_ApsGaugeVal "VCU_EcoGuide_ApsGaugeValue ##2G##VCU - VCU7 - CR_Vcu_SmartEcoLvl";
CM_ SG_ 2328016130 VCU_EcoGuide_EcoGaugeVal "VCU_EcoGuide_EcoGaugeValue ##2G##VCU - VCU7 - CR_Vcu_SmartEcoRng";
CM_ BO_ 2328016131 "[P] Periodic";
CM_ SG_ 2328016131 VCU_TgSocDteAcChgVal "VCU_TargetSocDte(Sc/Ac)ChargerValue ##2G##VCU - VCU19 - CR_Vcu_TgSocDte_AcChg";
CM_ SG_ 2328016131 VCU_TgSocDteDcChgVal "VCU_TargetSocDte(Qc/Dc)ChargerValue ##2G##VCU - VCU19 - CR_Vcu_TgSocDte_DcChg";
CM_ SG_ 2328016131 VCU_DistFromRegenDispReq "VCU_DistanceFromRegenerationDisplayRequest ##2G##VCU - VCU7 - CR_Vcu_RegenRangeAddSet";
CM_ SG_ 2328016131 VCU_DistFromRegenVal "VCU_DistanceFromRegenerationValue ##2G##VCU - VCU7 - CR_Vcu_RegenRangeAdd";
CM_ SG_ 2328016131 VCU_DrvStyle_DispReq "VCU_DriveStyle_DisplayRequest ##2G##VCU - VCU7 - CF_Vcu_FueEffStat";
CM_ SG_ 2328016131 VCU_DrvStyle_HighLightSta "VCU_DriveStyle_HighLightStatus ##2G##VCU - VCU7 - CF_Vcu_FueEffStatBox";
CM_ SG_ 2328016131 VCU_DrvStyle_EcoVal "VCU_DriveStyle_EcoValue ##2G##VCU - VCU7 - CR_Vcu_HighFueEff_Pc";
CM_ SG_ 2328016131 VCU_DrvStyle_NonEcoVal "VCU_DriveStyle_NonEcoValue ##2G##VCU - VCU7 - CR_Vcu_LowFueEff_Pc";
CM_ SG_ 2328016131 VCU_DrvStyle_NorVal "VCU_DriveStyle_NorValue ##2G##VCU - VCU7 - CR_Vcu_NorFueEff_Pc";
CM_ BO_ 200 "[EC] On Event and On Change";
CM_ SG_ 200 CF_AVN_BodySpprtSet_AST "This signal is for the Ergo-Motion seat (AST) body support (Smart Posture Assist) USM";
CM_ SG_ 200 CF_AVN_AirSptTimeNValueSet_AST "This signal is for the Ergo-Motion seat (AST) massage function time setting";
CM_ SG_ 200 CF_AVN_AirSptStrNValue_AST "This signal is for the ERGO seat (AST) massage intensity USM";
CM_ SG_ 200 CF_AVN_SeatDrvModNvalueSet_AST "This signal is for the Ergo-Motion seat (AST) smart support (Smart Support) USM";
CM_ BO_ 1159 "[PE] Periodic and On Event";
CM_ SG_ 1159 C_AstRclBwdSw_HU "Assistant seat Moving control :Recline Backward";
CM_ SG_ 1159 C_AstHeightUpSw_HU "Assistant seat Moving control : Height Up";
CM_ SG_ 1159 C_AstTiltDnSw_HU "Assistant seat Moving control : Tilt Down";
CM_ SG_ 1159 C_AstTiltUpSw_HU "Assistant seat Moving Switch : Tilt Up";
CM_ SG_ 1159 C_AstLumbarDefSw_HU "Assistant seat moving switch: Deflate";
CM_ SG_ 1159 C_AstLumbarLowSw_HU "Assistant seat moving switch:Lumbar Low";
CM_ SG_ 1159 C_AstRclFwdSw_HU "Assistant seat Moving Switch : Recline Forward";
CM_ SG_ 1159 C_AstLumbarMidSw_HU "Assistant seat Moving control : Lumbar Mid";
CM_ SG_ 1159 C_AstLumbarUpSw_HU "Assistant seat Moving control : Lumbar Up";
CM_ SG_ 1159 C_RRSlideFwdSw_HU "2nd Right side seat Moving control :Power Slide Forward";
CM_ SG_ 1159 C_RRSlideBwdSw_HU "2nd Right side seat Moving control :Power Slide Backward";
CM_ SG_ 1159 C_RLSlideFwdSw_HU "2nd Left side seat Moving control :Power Slide Forward";
CM_ SG_ 1159 C_RLSlideBwdSw_HU "2nd Left side seat Moving control :Power Slide Backward";
CM_ SG_ 1159 C_AstSlideBwdSw_HU "Assistant seat moving switch : Slide Backward";
CM_ SG_ 1159 C_AstSlideFwdSw_HU "Assistant seat Moving switch : Slide Forward";
CM_ SG_ 1159 C_AstHeightDnSw_HU "Assistant seat Moving control : Height Down";
CM_ BO_ 197 "[PE] Periodic and On Event";
CM_ SG_ 197 C_DrvRclBwdSw_HU "Driver Seat Recline Backward Control";
CM_ SG_ 197 C_DrvSlideFwdSw_HU "Driver Seat Slide Forward Control";
CM_ SG_ 197 C_RLLegSupFwdSw_HU "2nd Left side seat Moving control : Leg Support Forward";
CM_ SG_ 197 C_RLLegSupBwdSw_HU "2nd Left side seat Moving control : Leg Support Backward";
CM_ SG_ 197 C_DrvSlideBwdSw_HU "Driver Seat Slide Backward Control";
CM_ SG_ 197 C_RLLegSupUpSw_HU "2nd Left side seat Moving control : Leg Support Up";
CM_ SG_ 197 C_RLLegSupDnSw_HU "2nd Left side seat Moving control : Leg Support Down";
CM_ SG_ 197 C_DrvRclFwdSw_HU "Driver Seat Recline Forward Control";
CM_ BO_ 2382595073 "[PE] Periodic and On Event";
CM_ SG_ 2382595073 DATC_Crc7Val "DATC_CyclicRedundancyCheck7Value";
CM_ SG_ 2382595073 DATC_AlvCnt7Val "DATC_AliveCounter7Value";
CM_ SG_ 2382595073 DATC_FrDrvBlwDis "DATC_FrontDriverBlowerDisplay";
CM_ SG_ 2382595073 DATC_FrPsBlwDis "DATC_FrontPassengerBlowerDisplay";
CM_ SG_ 2382595073 DATC_HeatDis "DATC_HeatDisplay";
CM_ SG_ 2382595073 DATC_EVScrnDis "DATC_EVScreenDisplay";
CM_ SG_ 2382595073 DATC_DrvOnlyDis "DATC_DriverOnlyDisplay";
CM_ SG_ 2382595073 DATC_DiagCodeDis "DATC_DiagnosisCodeDisplay";
CM_ SG_ 2382595073 DATC_RrChgReqDis "DATC_RearChangeRequestDisplay";
CM_ SG_ 2382595073 DATC_RrClmtScrnDis "DATC_RearClimateScreenDisplay";
CM_ SG_ 2382595073 DATC_AUTOStep "This signal indicates AUTO step status in case Multi Auto Blower type.";
CM_ SG_ 2382595073 DATC_IntakeDis "This signal indicates intake indicator & display";
CM_ SG_ 2382595073 DATC_MultiAirModSta "This signal indicates MultiAirModeStatus";
CM_ BO_ 1167 "[PE] Periodic and On Event";
CM_ SG_ 1167 ICU_Crc11Val "ICU_CyclicRedundancyCheck11Value";
CM_ SG_ 1167 Bat_dischrg "Battery discharge notification flag #2G# Bat_dischrg";
CM_ SG_ 1167 ICU_AlvCnt11Val "ICU_AliveCounter11Value";
CM_ SG_ 1167 Batt_SoCWarningValue "Value of SoC warning level. ##2G## -  - Batt_SoCWarningValue";
CM_ SG_ 1167 ICU_BattAutoCutPreWrng "This is a warning signal before blocking the dark current of the ICU by the battery SOC.";
CM_ SG_ 1167 IGN_AutoOff_WarnSta_CLU "this signal is defined as the warning signal related with battery discharge";
CM_ SG_ 1167 PDC_BatPwrStateClassA "Battery Power State ClassA";
CM_ SG_ 1167 PDC_BatPwrStateClassB "Battery Power State ClassB";
CM_ SG_ 1167 PDC_BatPwrStateClassC "Battery Power State ClassC";
CM_ SG_ 1167 IGN_AutoOff_WarnSta "this signal is defined as the warning signal related with battery discharge";
CM_ BO_ 223 "[EC] On Event and On Change";
CM_ SG_ 223 ALBCU_SmartCtrl_1h "Smart Posture Adjust 1hr";
CM_ SG_ 223 ALBCU_SmartCtrl_2h "Smart Posture Adjust AVN Display (2hr)";
CM_ SG_ 223 ALBCU_SmartCtrl_Status "Smart Posture Adjust 2nd Interlocked Move AVN popup request";
CM_ BO_ 1171 "[PE] Periodic and On Event";
CM_ SG_ 1171 RLPSM_SWVerMajor1 "First Word(ASCII) in RLPSM S/W Ver";
CM_ SG_ 1171 RLPSM_SWVerMinor2 "Third Word(ASCII) in RLPSM S/W Ver";
CM_ SG_ 1171 RLPSM_SWVerMinor1 "Second Word(ASCII) in RLPSM S/W Ver";
CM_ BO_ 1172 "[PE] Periodic and On Event";
CM_ SG_ 1172 RRPSM_SWVerMajor1 "First Word(ASCII) in RRPSM S/W Ver";
CM_ SG_ 1172 RRPSM_SWVerMinor2 "Third Word(ASCII) in RRPSM S/W Ver";
CM_ SG_ 1172 RRPSM_SWVerMinor1 "Second Word(ASCII) in RRPSM S/W Ver";
CM_ BO_ 1174 "[PE] Periodic and On Event";
CM_ SG_ 1174 Drv_SHVU_SeatOptSta "Drv Seat Heater/Vent option info";
CM_ SG_ 1174 Drv_SHVU_HtSwHiIndSta "Drv Seat Heater Switch High Indicator Status";
CM_ SG_ 1174 Drv_SHVU_HtSwMidIndSta "Drv Seat Heater Switch Mid Indicator Status";
CM_ SG_ 1174 Drv_SHVU_HtSwLowIndSta "Drv Seat Heater Switch Low Indicator Status";
CM_ SG_ 1174 Drv_SHVU_VntSwHiIndSta "Drv Seat Vent Switch High Indicator Status";
CM_ SG_ 1174 Drv_SHVU_VntSwMidIndSta "Drv Seat Vent Switch Mid Indicator Status";
CM_ SG_ 1174 Drv_SHVU_VntSwLowIndSta "Drv Seat Vent Switch Low Indicator Status";
CM_ SG_ 1174 Drv_SHVU_HtBlcUSMSta "Hetaer Balance Driver USM R vaule";
CM_ SG_ 1174 Drv_SHVU_SeatHtOperSta "Drv Seat Heater/Vent current operation state";
CM_ SG_ 1174 Drv_SHVU_HtSwHiIndSta_RHD "Drv Seat Heater Switch High Indicator Status(RHD)";
CM_ SG_ 1174 Drv_SHVU_HtSwMidIndSta_RHD "Drv Seat Heater Switch Mid Indicator Status(RHD)";
CM_ SG_ 1174 Drv_SHVU_HtSwLowIndSta_RHD "Drv Seat Heater Switch Low Indicator Status(RHD)";
CM_ SG_ 1174 Drv_SHVU_VntSwHiIndSta_RHD "Drv Seat Vent Switch High Indicator Status(RHD)";
CM_ SG_ 1174 Drv_SHVU_VntSwMidIndSta_RHD "Drv Seat Vent Switch Mid Indicator Status(RHD)";
CM_ SG_ 1174 Drv_SHVU_VntSwLowIndSta_RHD "Drv Seat Vent Switch Low Indicator Status(RHD)";
CM_ SG_ 1174 Drv_SHVU_HtBlcUSMSta_RHD "Hetaer Balance Driver USM R vaule(RHD)";
CM_ BO_ 1179 "[EC] On Event and On Change";
CM_ SG_ 1179 Drv_SHVU_SeatEcoSta "Driver Seat Eco+ Mode Status";
CM_ SG_ 1179 SHVU_Drv_Beep1Sound "SHVU_FR Driver's Seat Heater or Ventilation Switch input Beep Request";
CM_ SG_ 1179 SHVU_CtrlScreenDis "Request AVN screen change for controlling Seat Heater or Ventilation";
CM_ BO_ 1180 "[EC] On Event and On Change";
CM_ SG_ 1180 SHVU_Ast_Beep1Sound "SHVU_FR Assistant's Seat Heater or Ventilation Switch input Beep Request";
CM_ SG_ 1180 Ast_SHVU_SeatEcoSta "Assistant (Passenger) Seat Eco+ Mode Status";
CM_ BO_ 208 "[PE] Periodic and On Event";
CM_ SG_ 208 RR_SHVU_DTCdisplay "0x00: DTC is not exist(Fail is not exist)/0x01:IGN2 Fuse Open Detection/0x02:Switch Input Detection at Same Time/0x03:NTC/Heating wire Open Detection/0x04:NTC+/NTC- Terminal Short Detection/0x05:NTC+/Heater+ Terminal Short Detection/0x06:NTC+/Heater-, Heater+/Heater-, Heater+/NTC- Terminal Short Detection/0x07:NTC+/Heater- Wiring Short Detection/0x08:NTC+/Heater-, Heater+/Heater-, Heater+/NTC- Wiring Short Detection/0x09:Target Temperature Dissatisfied/0x0A:Blower+/Blower- Short, Blower+/Blower Speed, Blower-/Blower Speed Wiring Short Detection/0x0B:Blower+/Blower RPM, Blower-/Blower RPM, Blower Speed/Blower RPM Short Detection/0x0C:Blower+, Blower-, Blower Speed Signal open Detection/0x0D:Blower RPM signal Open Detection/0x0E~0xFD:Unused/0xFE:No Display/0xFF:Invalid";
CM_ SG_ 208 RR_SHVU_DiagMode "0x0:Default/0x1:DTC Mode/0x2:Normal Mode/0x3:Invalid";
CM_ BO_ 1181 "[EC] On Event and On Change";
CM_ SG_ 1181 RL_SHVU_SeatEcoSta "Rear LH Seat Eco+ Mode Status";
CM_ BO_ 1182 "[EC] On Event and On Change";
CM_ SG_ 1182 RR_SHVU_SeatEcoSta "Rear RH Seat Eco+ Mode Status";
CM_ BO_ 1186 "[EC] On Event and On Change";
CM_ SG_ 1186 C_RemoteWdwCMDHU "Signal for control window (TMS), HI only";
CM_ SG_ 1186 HU_CDMOpenCmd "Command for CDM open/close";
CM_ SG_ 1186 C_PreCrankReq "Command for B-CAN wake up signal
(Need to send this signal before other remote commands)";
CM_ SG_ 1186 C_TeleAstSeatOpCmdIBOX "Command for Remote Seat Heat/Vent control (Passenger)";
CM_ SG_ 1186 C_TeleDrvSeatOpCmdIBOX "Command for Remote Seat Heat/Vent control (Driver)";
CM_ SG_ 1186 C_TeleRRSeatOpCmdIBOX "Command for Remote Seat Heat/Vent control (Rear Right)";
CM_ SG_ 1186 C_TeleRLSeatOpCmdIBOX "Command for Remote Seat Heat/Vent control (Rear Left)";
CM_ BO_ 1185 "[EC] On Event and On Change";
CM_ SG_ 1185 C_AstWindowCmdAVN "This signal indicates AST Window Open/Close Command";
CM_ SG_ 1185 C_RrDefoggerCmdAVN "This signal indicates Rear Defogger Button Command";
CM_ SG_ 1185 C_RRWindowCmdAVN "This signal indicates RR Window Open/Close Command";
CM_ SG_ 1185 C_RLWindowCmdAVN "This signal indicates RL Window Open/Close Command";
CM_ SG_ 1185 C_BlindCmdAVN "This signal indicates Sunroof Blind Open/Close Command";
CM_ SG_ 1185 C_GlassCmdAVN "This signal indicates Sunroof Glass Open/Close Command";
CM_ SG_ 1185 C_DrvWindowCmdAVN "This signal indicates DRV Window Open/Close Command";
CM_ SG_ 1185 C_PTGCNTLCmdAVN "This signal indicates PowerTailgate Open/Close  Command";
CM_ BO_ 1189 "[PE] Periodic and On Event";
CM_ SG_ 1189 C_RLTiltUpSw_HU "2nd Left side seat Moving control : Tilt Up";
CM_ SG_ 1189 C_RRTiltDownSw_HU "2nd Right side seat Moving control : Tilt Down";
CM_ SG_ 1189 C_RRTiltUpSw_HU "2nd Right side seat Moving control : Tilt Up";
CM_ SG_ 1189 C_RLRclBwdSw_HU "2nd Left side seat Moving control :Recline Backward";
CM_ SG_ 1189 C_RLRclFwdSw_HU "2nd Left side seat Moving control : Recline Forward";
CM_ SG_ 1189 C_RLFldSw_HU "2nd Left side seat folding control : Folding";
CM_ SG_ 1189 C_RRRclBwdSw_HU "2nd Right side seat Moving control :Recline Backward";
CM_ SG_ 1189 C_RRRclFwdSw_HU "2nd Right side seat Moving control :Recline Forward";
CM_ SG_ 1189 C_TLHrestFldSw_HU "3rdLeft side seat Headrest folding control : Folding";
CM_ SG_ 1189 C_TRHrestFldSw_HU "3rd Right side seat Headrest folding control : Folding";
CM_ SG_ 1189 C_RLRlxSW_HU "2nd Left side seat Moving control : Relax mode";
CM_ SG_ 1189 C_RRRlxSW_HU "2nd Right side seat Moving control : Relax mode";
CM_ SG_ 1189 C_TLFldSw_HU "3rd Left side seat folding control : Folding";
CM_ SG_ 1189 C_TRFldSw_HU "3rd Right side seat folding control : Folding";
CM_ SG_ 1189 C_RRFldSw_HU "2nd Right side seat folding control : Folding";
CM_ SG_ 1189 C_RLTiltDownSw_HU "2nd Left side seat Moving control : Tilt Down";
CM_ BO_ 1195 "[EC] On Event and On Change";
CM_ SG_ 1195 CF_AVN_CluWelcomeSnd "Request to set CLU welcome soun";
CM_ SG_ 1195 CF_AVN_CluTransmissionDisp "Request to set CLU transmission display";
CM_ SG_ 1195 CF_AVN_CluWiperLight "Request to set CLU wiper & light mode";
CM_ SG_ 1195 CF_AVN_CluRoadInfoGuide "Request to set CLU road info guidance";
CM_ SG_ 1195 CF_AVN_CluUserSettingPeriod "Request to set CLU sservice period set by user";
CM_ SG_ 1195 CF_AVN_CluFuelEconUnit_mi "Cluster setting status for cluster Fuel Economy Unit (mile)";
CM_ SG_ 1195 CF_AVN_CluFuelEconUnit_km "Cluster setting status for cluster Fuel Economy unit (km)";
CM_ SG_ 1195 CF_AVN_CluUserSettingDistance "Request to set CLU service distance set by user";
CM_ SG_ 1195 CF_AVN_CluRheostatLvl "Request to set CLU rheostat level";
CM_ SG_ 1195 CF_AVN_EVReset "Request to reset EV Service (0x1 : EV USM Reset)";
CM_ SG_ 1195 CF_AVN_UnitReset "Request to reset Unit setting";
CM_ SG_ 1195 CF_AVN_CluServiceReminderReset "Request to reset CLU service reminder";
CM_ SG_ 1195 CF_AVN_CluUSMReset "Request to reset all USM service";
CM_ SG_ 1195 CF_AVN_CluServiceReminderSet "Request to set CLU service notification";
CM_ BO_ 1193 "[EC] On Event and On Change";
CM_ SG_ 1193 C_PTGMNValueSet "Request to set PTGM Mode";
CM_ SG_ 1193 CF_AVN_PSMNValueSet "This signal is used for a request to set the value of UMS Menus. This signal requests to set Seat Easy Access Mode. When this signal change, the message is sent 3 times.";
CM_ SG_ 1193 C_HfreeTrunkTgNValueSet "Request to set Smart Trunk/Tailgate Mode";
CM_ SG_ 1193 CF_AVN_TrfChgSet "This signal is used for a request to set the value of UMS Menus. This signal requests to set Traffic Change Mode. When this signal change, the message is sent 3 times.";
CM_ SG_ 1193 CF_AVN_SCMNValueSet "Request to set Steering Easy Access mode";
CM_ SG_ 1193 CF_AVN_ADrUNValueSet "Request to set Auto Door Unlock Mode";
CM_ SG_ 1193 CF_AVN_OTTurnNValueSet "This signal is used for a request current setting value of USM Menus. When this signal change, the message is sent 3 times.";
CM_ SG_ 1193 CF_Gway_WPCNValueSet "Request to set Wireless Phone Charging mode";
CM_ SG_ 1193 C_AVN_RearWiperNValueSet "Request to set Rear Wiper operation in reverse";
CM_ SG_ 1193 C_UnlockWelocomeNValueSet "Request to set Door Unlock Welcome Setting Option";
CM_ SG_ 1193 C_SmartWelocomeNValueSet "Request to set Smart Key Welcome Setting Option";
CM_ SG_ 1193 CF_AVN_PTGSpeedNValueSet "Setting Value For Power Tailgate Speed";
CM_ SG_ 1193 CR_Datc_DRSeatWheel_USM_Set "SteeringWheel USM Set";
CM_ SG_ 1193 CF_AVN_TTUnlockNValueSet "Setting Value for Two Turn Unlock";
CM_ SG_ 1193 CF_Gway_RWPCNValueSet "Rear Wireless Phone Charger ON/OFF Request";
CM_ SG_ 1193 CF_Avn_HAPTICWARNINGNValueSet "USM request for Steering Wheel Haptic Warning";
CM_ SG_ 1193 CR_Datc_DRSeatHeat_USM_Set "Driver Seat Heat/Ventl USM Set";
CM_ SG_ 1193 C_WALNValueSet "USM Function for Walk Away Lock(WAL)";
CM_ SG_ 1193 C_ApprUnlockNValue "USM request for Approach Unlock";
CM_ SG_ 1193 CF_AVN_EscortHLNValueSet "Request to set Head Lamp Escort Option";
CM_ BO_ 2365803012 "[P] Periodic";
CM_ SG_ 2365803012 DATC_Opt_Sys "This signal indicate System Option information for Climate Control. (Replace of DATC_Typ/Typ2, DATC_Opt1~5Typ signal)";
CM_ SG_ 2365803012 DATC_Opt_Func "This signal indicate Function Option for Climate Control. (Replace of DATC_Typ/Typ2, DATC_Opt1~5Typ signal)";
CM_ BO_ 2365803011 "[P] Periodic";
CM_ SG_ 2365803011 DATC_Typ_All_3 "This signal indicate Climate Control System Type information  (Replace of DATC_Typ/Typ2, DATC_Opt1~5Typ signal)";
CM_ SG_ 2365803011 DATC_Typ_All_4 "This signal indicate Climate Control System Type information. (Replace of DATC_Typ/Typ2, DATC_Opt1~5Typ signal)";
CM_ SG_ 2365803011 DATC_Typ_All_5 "This signal indicate Climate Control System Type information. (Replace of DATC_Typ/Typ2, DATC_Opt1~5Typ signal)";
CM_ SG_ 2365803011 DATC_Typ_All_6 "This signal indicate Climate Control System Type information. (Replace of DATC_Typ/Typ2, DATC_Opt1~5Typ signal)";
CM_ BO_ 2365803010 "[P] Periodic";
CM_ SG_ 2365803010 DATC_SwVer4 "this signal indicates DATC Detail Software Version";
CM_ SG_ 2365803010 DATC_Typ_All_1 "This signal indicate Climate Control System Type information. (Replace of DATC_Typ/Typ2, DATC_Opt1~5Typ signal)";
CM_ SG_ 2365803010 DATC_Typ_All_2 "This signal indicate Climate Control System Type information  (Replace of DATC_Typ/Typ2, DATC_Opt1~5Typ signal)";
CM_ SG_ 2365803010 DATC_SwVer5 "this signal indicates DATC Detail Software Version";
CM_ BO_ 2365803009 "[P] Periodic";
CM_ SG_ 2365803009 DATC_Crc16Val "DATC_CyclicRedundancyCheck16Value";
CM_ SG_ 2365803009 DATC_AlvCnt16Val "DATC_AliveCounter16Value";
CM_ SG_ 2365803009 DATC_SwVer1 "this signal indicates DATC Software Version to display on H_U";
CM_ SG_ 2365803009 DATC_SwVer2 "This signal indicates DATC software vertion to display on H_U";
CM_ SG_ 2365803009 DATC_Typ2 "DATC_Type2";
CM_ BO_ 1196 "[EC] On Event and On Change";
CM_ SG_ 1196 C_HCIMSWeightNValueSet "This signal is used for Healthcare IMS to input user's weight";
CM_ SG_ 1196 C_HCIMSSitHeightNValueSet "This signal is used for Healthcare IMS to input user's sitting height";
CM_ SG_ 1196 CF_AVN_BodySpprtSet "This signal is for the seat body support USM";
CM_ SG_ 1196 CF_AVN_AirSptTimeNValueSet "This signal is for the seat massage function time setting";
CM_ SG_ 1196 CF_AVN_AirSptStrNValue "This signal is for the seat massage intensity USM";
CM_ SG_ 1196 CF_AVN_SeatDrvModNValueSet "This signal is for the auto seat-drivemode user setting menu";
CM_ SG_ 1196 C_HCIMSHeightNvalueSet "This signal is used for Healthcare IMS to input user's height";
CM_ SG_ 1196 CF_AVN_CushSoftNValueSet "This signal is for the cushsoftness setting";
CM_ SG_ 1196 CF_AVN_HCIMSButtonCommand "User's input value in healthcare IMS mode";
CM_ BO_ 2328015108 "[P] Periodic";
CM_ BO_ 255 "[PE] Periodic and On Event";
CM_ SG_ 255 BCM_Crc20Val "BCM_CyclicRedundancyCheck20Value";
CM_ SG_ 255 BCM_AlvCnt20Val "BCM_AliveCounter20Value";
CM_ SG_ 255 Mirror_MirFldOpt "Outside Mirror Electric Fold Option Signal";
CM_ SG_ 255 Mirror_FldUnfldCmd "Mirror Folding Unfolding Command";
CM_ SG_ 255 Mirror_FldCtrlSta "Mirror Fold and Folding Control State";
CM_ SG_ 255 Mirror_UnFldCtrlSta "Mirror Unfold and Unfolding Control State";
CM_ SG_ 255 Mirror_PosMnlCmd "Mirror Positioning Request";
CM_ SG_ 255 Mirror_SelSwIndCmd "Mirror Select Switch Indicator Command";
CM_ SG_ 255 Mirror_LHOSMirPlyBckSta "This siganl indicates Left O/S Mirror moving state for IMS From BDC";
CM_ SG_ 255 Mirror_RHOSMirPlyBckSta "This siganl indicates Right O/S Mirror moving state for IMS From BDC";
CM_ SG_ 255 Mirror_SelSwSta "Outside Mirror Select Button Status";
CM_ SG_ 255 BckGls_RrGlsHtdOpt "Back Glass_Rear Glass Heated Option Signal";
CM_ BO_ 2328015105 "[P] Periodic";
CM_ SG_ 2328015105 ADAS_CMD_Crc34Val "ADAS_CMD_CyclicRedundancyCheck34Value";
CM_ SG_ 2328015105 ADAS_CMD_AlvCnt34Val "ADAS_CMD_AliveCounter34Value";
CM_ SG_ 2328015105 HDP_RDD_WarnSta "HDP_RDD Warning State";
CM_ SG_ 2328015105 HDP_RDD_LongAsstCtrlSta "HDP_RDD Longitudinal Assist Control State";
CM_ SG_ 2328015105 HDP_RDD_HzrdLmpReqSta "HDP_RDD Hazard Lamp Request State";
CM_ SG_ 2328015105 HDP_RDD_ACIActvDispSta "HDP_RDD AngleControlInterface Active Display State";
CM_ BO_ 2328015106 "[P] Periodic";
CM_ SG_ 2328015106 HDP_RDD_EMStbltActvReqSta "HDP_RDD EM Seatbelt Activate Request State";
CM_ BO_ 2328015107 "[P] Periodic";
BA_DEF_ BO_  "DiagState" ENUM  "No","Yes";
BA_DEF_ BO_  "DiagResponse" ENUM  "No","Yes";
BA_DEF_ BO_  "DiagRequest" ENUM  "No","Yes";
BA_DEF_ BO_  "TpMessage" ENUM  "No","Yes";
BA_DEF_ BO_  "UsrMsgIDSforwardDeviation" INT 0 100;
BA_DEF_ BO_  "UsrMsgIDSbackwardDeviation" INT 50 1000;
BA_DEF_ BO_  "GenMsgCycleTime" INT 0 2000;
BA_DEF_ BO_  "GenMsgStartDelayTime" INT 0 2000;
BA_DEF_ BO_  "GenMsgSendType" ENUM  "Cyclic","NoMsgSendType";
BA_DEF_ BO_  "GenMsgCycleTimeFast" INT 0 500;
BA_DEF_ BO_  "GenMsgDelayTime" INT 0 20;
BA_DEF_ BO_  "GenMsgILSupport" ENUM  "No","Yes";
BA_DEF_ BO_  "GenMsgNrOfRepetition" INT 0 3;
BA_DEF_ BO_  "NmMessage" ENUM  "No","Yes";
BA_DEF_ BO_  "NWM-Botschaft" ENUM  "No","Yes";
BA_DEF_ BO_  "TpTxIndex" INT 0 65535;
BA_DEF_ BO_  "VFrameFormat" ENUM  "StandardCAN","ExtendedCAN","reserved","reserved","reserved","reserved","reserved","reserved","reserved","reserved","reserved","reserved","reserved","reserved","StandardCAN_FD","ExtendedCAN_FD";
BA_DEF_ SG_  "UserSigValidity" ENUM  "B+","ACC","IG","IG1","IG2","IG3","IG1 or IG2","IG1 or IG3","Undef";
BA_DEF_ SG_  "TimeoutValue" STRING ;
BA_DEF_ SG_  "UsrSigPurpose" ENUM  "Undef","FN","DIAG","DIAG(Req)","DIAG(Res)","DIAG(Phy)","DEV","CCP(Req)","CCP(Res)","NM","TP";
BA_DEF_ SG_  "GenSigStartValue" INT 0 1215752192;
BA_DEF_ SG_  "NetworkRequest" ENUM  "Yes","No";
BA_DEF_ SG_  "NetworkRequestHoldingTime" INT 0 65535;
BA_DEF_ SG_  "Description" STRING ;
BA_DEF_ SG_  "Version" STRING ;
BA_DEF_ SG_  "GenSigEnvVarType" ENUM  "Int","Float","Undef";
BA_DEF_ SG_  "GenSigSendType" ENUM  "Cyclic","OnWrite","OnWriteWithRepetition","OnChange","OnChangeWithRepetition","IfActive","IfActiveWithRepetition","NoSigSendType","OnChangeAndIfActive","OnChangeAndIfActiveWithRepetition";
BA_DEF_ SG_  "GwSigLatencyTime" INT 0 65536;
BA_DEF_ SG_  "GwSigMissingSourceType" ENUM  "Undef","OldValue","DefaultValue","InitialValue";
BA_DEF_ SG_  "NWM-WakeupAllowed" ENUM  "<n.a.>";
BA_DEF_ SG_  "RoutingFactor" INT 1 1215752192;
BA_DEF_ SG_  "SystemSignalLongSymbol" STRING ;
BA_DEF_REL_ BU_SG_REL_  "GenSigTimeoutTime" INT 0 7000;
BA_DEF_DEF_  "DiagState" "No";
BA_DEF_DEF_  "DiagResponse" "No";
BA_DEF_DEF_  "DiagRequest" "No";
BA_DEF_DEF_  "TpMessage" "No";
BA_DEF_DEF_  "UsrMsgIDSforwardDeviation" 10;
BA_DEF_DEF_  "UsrMsgIDSbackwardDeviation" 100;
BA_DEF_DEF_  "GenMsgCycleTime" 200;
BA_DEF_DEF_  "GenMsgStartDelayTime" 0;
BA_DEF_DEF_  "GenMsgSendType" "NoMsgSendType";
BA_DEF_DEF_  "GenMsgCycleTimeFast" 40;
BA_DEF_DEF_  "GenMsgDelayTime" 20;
BA_DEF_DEF_  "GenMsgILSupport" "Yes";
BA_DEF_DEF_  "GenMsgNrOfRepetition" 3;
BA_DEF_DEF_  "NmMessage" "No";
BA_DEF_DEF_  "NWM-Botschaft" "No";
BA_DEF_DEF_  "TpTxIndex" 0;
BA_DEF_DEF_  "VFrameFormat" "StandardCAN";
BA_DEF_DEF_  "UserSigValidity" "IG";
BA_DEF_DEF_  "TimeoutValue" "";
BA_DEF_DEF_  "UsrSigPurpose" "FN";
BA_DEF_DEF_  "GenSigStartValue" 0;
BA_DEF_DEF_  "NetworkRequest" "No";
BA_DEF_DEF_  "NetworkRequestHoldingTime" 0;
BA_DEF_DEF_  "Description" "";
BA_DEF_DEF_  "Version" "";
BA_DEF_DEF_  "GenSigEnvVarType" "Undef";
BA_DEF_DEF_  "GenSigSendType" "NoSigSendType";
BA_DEF_DEF_  "GwSigLatencyTime" 40;
BA_DEF_DEF_  "GwSigMissingSourceType" "Undef";
BA_DEF_DEF_  "NWM-WakeupAllowed" "<n.a.>";
BA_DEF_DEF_  "RoutingFactor" 1;
BA_DEF_DEF_REL_ "GenSigTimeoutTime" 500;
BA_DEF_DEF_  "SystemSignalLongSymbol" "";
BA_ "GenMsgCycleTime" BO_ 1279 0;
BA_ "VFrameFormat" BO_ 2328016129 1;
BA_ "GenMsgNrOfRepetition" BO_ 2328016129 0;
BA_ "GenMsgCycleTimeFast" BO_ 2328016129 0;
BA_ "GenMsgSendType" BO_ 2328016129 0;
BA_ "VFrameFormat" BO_ 2328016130 1;
BA_ "GenMsgNrOfRepetition" BO_ 2328016130 0;
BA_ "GenMsgCycleTimeFast" BO_ 2328016130 0;
BA_ "GenMsgSendType" BO_ 2328016130 0;
BA_ "VFrameFormat" BO_ 2328016131 1;
BA_ "GenMsgNrOfRepetition" BO_ 2328016131 0;
BA_ "GenMsgCycleTimeFast" BO_ 2328016131 0;
BA_ "GenMsgSendType" BO_ 2328016131 0;
BA_ "GenMsgCycleTime" BO_ 200 0;
BA_ "GenMsgStartDelayTime" BO_ 1159 90;
BA_ "GenMsgSendType" BO_ 1159 0;
BA_ "GenMsgSendType" BO_ 197 0;
BA_ "VFrameFormat" BO_ 2382595073 1;
BA_ "GenMsgSendType" BO_ 2382595073 0;
BA_ "GenMsgCycleTime" BO_ 1167 1000;
BA_ "GenMsgSendType" BO_ 1167 0;
BA_ "GenMsgCycleTime" BO_ 223 0;
BA_ "GenMsgSendType" BO_ 1171 0;
BA_ "GenMsgSendType" BO_ 1172 0;
BA_ "GenMsgSendType" BO_ 1174 0;
BA_ "GenMsgCycleTime" BO_ 1179 0;
BA_ "GenMsgCycleTime" BO_ 1180 0;
BA_ "GenMsgSendType" BO_ 208 0;
BA_ "GenMsgCycleTime" BO_ 1181 0;
BA_ "GenMsgCycleTime" BO_ 1182 0;
BA_ "GenMsgCycleTime" BO_ 1186 0;
BA_ "GenMsgCycleTime" BO_ 1185 0;
BA_ "GenMsgStartDelayTime" BO_ 1189 80;
BA_ "GenMsgSendType" BO_ 1189 0;
BA_ "GenMsgCycleTime" BO_ 1195 0;
BA_ "GenMsgCycleTime" BO_ 1193 0;
BA_ "VFrameFormat" BO_ 2365803012 1;
BA_ "GenMsgNrOfRepetition" BO_ 2365803012 0;
BA_ "GenMsgCycleTimeFast" BO_ 2365803012 0;
BA_ "GenMsgCycleTime" BO_ 2365803012 1000;
BA_ "GenMsgSendType" BO_ 2365803012 0;
BA_ "VFrameFormat" BO_ 2365803011 1;
BA_ "GenMsgNrOfRepetition" BO_ 2365803011 0;
BA_ "GenMsgCycleTimeFast" BO_ 2365803011 0;
BA_ "GenMsgCycleTime" BO_ 2365803011 1000;
BA_ "GenMsgSendType" BO_ 2365803011 0;
BA_ "VFrameFormat" BO_ 2365803010 1;
BA_ "GenMsgNrOfRepetition" BO_ 2365803010 0;
BA_ "GenMsgCycleTimeFast" BO_ 2365803010 0;
BA_ "GenMsgCycleTime" BO_ 2365803010 1000;
BA_ "GenMsgSendType" BO_ 2365803010 0;
BA_ "VFrameFormat" BO_ 2365803009 1;
BA_ "GenMsgNrOfRepetition" BO_ 2365803009 0;
BA_ "GenMsgCycleTimeFast" BO_ 2365803009 0;
BA_ "GenMsgCycleTime" BO_ 2365803009 1000;
BA_ "GenMsgSendType" BO_ 2365803009 0;
BA_ "GenMsgCycleTime" BO_ 1196 0;
BA_ "VFrameFormat" BO_ 2328015108 1;
BA_ "GenMsgNrOfRepetition" BO_ 2328015108 0;
BA_ "GenMsgCycleTimeFast" BO_ 2328015108 0;
BA_ "GenMsgSendType" BO_ 2328015108 0;
BA_ "GenMsgSendType" BO_ 255 0;
BA_ "VFrameFormat" BO_ 2328015105 1;
BA_ "GenMsgNrOfRepetition" BO_ 2328015105 0;
BA_ "GenMsgCycleTimeFast" BO_ 2328015105 0;
BA_ "GenMsgSendType" BO_ 2328015105 0;
BA_ "VFrameFormat" BO_ 2328015106 1;
BA_ "GenMsgNrOfRepetition" BO_ 2328015106 0;
BA_ "GenMsgCycleTimeFast" BO_ 2328015106 0;
BA_ "GenMsgSendType" BO_ 2328015106 0;
BA_ "VFrameFormat" BO_ 2328015107 1;
BA_ "GenMsgNrOfRepetition" BO_ 2328015107 0;
BA_ "GenMsgCycleTimeFast" BO_ 2328015107 0;
BA_ "GenMsgSendType" BO_ 2328015107 0;
BA_ "Version" SG_ 1279 USM_SmartRegen_Map_Set "19.11.05";
BA_ "UserSigValidity" SG_ 1279 USM_SmartRegen_Map_Set 3;
BA_ "GenSigSendType" SG_ 1279 USM_SmartRegen_Map_Set 4;
BA_ "Description" SG_ 1279 USM_SmartRegen_Map_Set "Smart Regeneration 2.0 Map information USM User set signal";
BA_ "Version" SG_ 1279 USM_SmartRegen_Sens_Set "19.11.05";
BA_ "UserSigValidity" SG_ 1279 USM_SmartRegen_Sens_Set 3;
BA_ "GenSigSendType" SG_ 1279 USM_SmartRegen_Sens_Set 4;
BA_ "Description" SG_ 1279 USM_SmartRegen_Sens_Set "Smart Regeneration User Personality of Reduction Set Signal";
BA_ "Version" SG_ 1279 AVN_SeatPosMemory_Btn "19.11.11";
BA_ "UserSigValidity" SG_ 1279 AVN_SeatPosMemory_Btn 3;
BA_ "GenSigSendType" SG_ 1279 AVN_SeatPosMemory_Btn 4;
BA_ "Description" SG_ 1279 AVN_SeatPosMemory_Btn "Seat position save signal";
BA_ "Version" SG_ 1279 AVN_SeatPosPlyBck_Btn "19.11.11";
BA_ "UserSigValidity" SG_ 1279 AVN_SeatPosPlyBck_Btn 3;
BA_ "GenSigSendType" SG_ 1279 AVN_SeatPosPlyBck_Btn 4;
BA_ "Description" SG_ 1279 AVN_SeatPosPlyBck_Btn "Seat position move signal";
BA_ "Version" SG_ 1279 USM_RhstaLvlEnaSetReq "19.12.00";
BA_ "UserSigValidity" SG_ 1279 USM_RhstaLvlEnaSetReq 0;
BA_ "GenSigSendType" SG_ 1279 USM_RhstaLvlEnaSetReq 4;
BA_ "Description" SG_ 1279 USM_RhstaLvlEnaSetReq "USM Request for CMS Brightness with Rheostat";
BA_ "Version" SG_ 1279 USM_CMSDayBrgtnsLvlLHSetReq "19.12.00";
BA_ "UserSigValidity" SG_ 1279 USM_CMSDayBrgtnsLvlLHSetReq 0;
BA_ "GenSigStartValue" SG_ 1279 USM_CMSDayBrgtnsLvlLHSetReq 15;
BA_ "GenSigSendType" SG_ 1279 USM_CMSDayBrgtnsLvlLHSetReq 4;
BA_ "Description" SG_ 1279 USM_CMSDayBrgtnsLvlLHSetReq "USM Request for Day Brightness Level of CMS LH";
BA_ "Version" SG_ 1279 USM_CMSNgtBrgtnsLvlLHSetReq "19.12.00";
BA_ "UserSigValidity" SG_ 1279 USM_CMSNgtBrgtnsLvlLHSetReq 0;
BA_ "GenSigStartValue" SG_ 1279 USM_CMSNgtBrgtnsLvlLHSetReq 15;
BA_ "GenSigSendType" SG_ 1279 USM_CMSNgtBrgtnsLvlLHSetReq 4;
BA_ "Description" SG_ 1279 USM_CMSNgtBrgtnsLvlLHSetReq "USM Request for Night Brightness Level of CMS LH";
BA_ "Version" SG_ 1279 USM_CMSDayBrgtnsLvlRHSetReq "19.12.00";
BA_ "UserSigValidity" SG_ 1279 USM_CMSDayBrgtnsLvlRHSetReq 0;
BA_ "GenSigStartValue" SG_ 1279 USM_CMSDayBrgtnsLvlRHSetReq 15;
BA_ "GenSigSendType" SG_ 1279 USM_CMSDayBrgtnsLvlRHSetReq 4;
BA_ "Description" SG_ 1279 USM_CMSDayBrgtnsLvlRHSetReq "USM Request for Day Brightness Level of CMS RH";
BA_ "Version" SG_ 1279 USM_CMSNgtBrgtnsLvlRHSetReq "19.12.00";
BA_ "UserSigValidity" SG_ 1279 USM_CMSNgtBrgtnsLvlRHSetReq 0;
BA_ "GenSigStartValue" SG_ 1279 USM_CMSNgtBrgtnsLvlRHSetReq 15;
BA_ "GenSigSendType" SG_ 1279 USM_CMSNgtBrgtnsLvlRHSetReq 4;
BA_ "Description" SG_ 1279 USM_CMSNgtBrgtnsLvlRHSetReq "USM Request for Night Brightness Level of CMS RH";
BA_ "Version" SG_ 1279 USM_CMSBrgtnsReset "20.06.01";
BA_ "UserSigValidity" SG_ 1279 USM_CMSBrgtnsReset 3;
BA_ "GenSigSendType" SG_ 1279 USM_CMSBrgtnsReset 4;
BA_ "Description" SG_ 1279 USM_CMSBrgtnsReset "CMS Brightness Reset (LH/RH)";
BA_ "Version" SG_ 1279 USM_TurnDistLnDispSetReq "19.12.00";
BA_ "UserSigValidity" SG_ 1279 USM_TurnDistLnDispSetReq 0;
BA_ "GenSigSendType" SG_ 1279 USM_TurnDistLnDispSetReq 4;
BA_ "Description" SG_ 1279 USM_TurnDistLnDispSetReq "USM Request for CMS Distance Lane Display";
BA_ "Version" SG_ 1279 PCA_FrSd_NValueSet "19.12.00";
BA_ "UserSigValidity" SG_ 1279 PCA_FrSd_NValueSet 3;
BA_ "GenSigSendType" SG_ 1279 PCA_FrSd_NValueSet 4;
BA_ "Description" SG_ 1279 PCA_FrSd_NValueSet "USM Request for PCA Front/Side";
BA_ "Version" SG_ 1279 CF_AVN_1stRrStRmndNValueSet "20.03.05";
BA_ "UserSigValidity" SG_ 1279 CF_AVN_1stRrStRmndNValueSet 3;
BA_ "GenSigSendType" SG_ 1279 CF_AVN_1stRrStRmndNValueSet 4;
BA_ "Description" SG_ 1279 CF_AVN_1stRrStRmndNValueSet "This signal is for seting the ROA function when IBU control ROA Function.";
BA_ "Version" SG_ 1279 C_AllDrOpnNValueSet "19.12.07";
BA_ "UserSigValidity" SG_ 1279 C_AllDrOpnNValueSet 3;
BA_ "GenSigSendType" SG_ 1279 C_AllDrOpnNValueSet 4;
BA_ "Description" SG_ 1279 C_AllDrOpnNValueSet "ALL Door (PSD PTG) Open Function by FOB Unlock Long Key USM Setting Signal

0x0 : Not Display in USM

0x1 : All Door Open Function Off

0x2 : Only PSD Open By FOB Unlock Long KEY

0x3 : PSD and PTG Open by FOB Unlock Long KEY

0x4 ~ 0x6 : Reserved

0x7 :";
BA_ "Version" SG_ 1279 USM_RpmECOSet "20.06.01";
BA_ "UserSigValidity" SG_ 1279 USM_RpmECOSet 3;
BA_ "GenSigSendType" SG_ 1279 USM_RpmECOSet 4;
BA_ "Description" SG_ 1279 USM_RpmECOSet "Relation To cluster Gauge Display";
BA_ "Version" SG_ 1279 VESS_ChgGuideMdLvl "20.05.01";
BA_ "UserSigValidity" SG_ 1279 VESS_ChgGuideMdLvl 3;
BA_ "GenSigSendType" SG_ 1279 VESS_ChgGuideMdLvl 4;
BA_ "Description" SG_ 1279 VESS_ChgGuideMdLvl "Charging Guide Volume Level function USM signal";
BA_ "Version" SG_ 1279 Usm_RpmSPORTSet "20.02.04";
BA_ "UserSigValidity" SG_ 1279 Usm_RpmSPORTSet 3;
BA_ "GenSigSendType" SG_ 1279 Usm_RpmSPORTSet 4;
BA_ "Description" SG_ 1279 Usm_RpmSPORTSet "Relation to cluster RPM Gauge Display";
BA_ "Version" SG_ 2328016129 VCU_Crc5Val "21.09.03";
BA_ "RoutingFactor" SG_ 2328016129 VCU_Crc5Val 2;
BA_ "UserSigValidity" SG_ 2328016129 VCU_Crc5Val 7;
BA_ "GenSigStartValue" SG_ 2328016129 VCU_Crc5Val 65535;
BA_ "Description" SG_ 2328016129 VCU_Crc5Val "The data area for CRC calculation is based on the data length (DLC) of the message DB.

The CRC shall be calculated over the entire data block (excluding the CRC bytes) including the user data, alive counter and Data ID



- CRC Polynomial (0x1021) , Ini";
BA_ "Version" SG_ 2328016129 VCU_AlvCnt5Val "21.09.03";
BA_ "RoutingFactor" SG_ 2328016129 VCU_AlvCnt5Val 2;
BA_ "UserSigValidity" SG_ 2328016129 VCU_AlvCnt5Val 7;
BA_ "Description" SG_ 2328016129 VCU_AlvCnt5Val "For the first transmission request for a data element the counter shall be initialized with 0 and shall be incremented by 1 for every subsequent send request. 

When the counter reaches the maximum value(0xFF), then it shall restart with 0 for the next s";
BA_ "Version" SG_ 2328016129 VCU_EvDrvRdyCluDispSta "19.09.05";
BA_ "RoutingFactor" SG_ 2328016129 VCU_EvDrvRdyCluDispSta 2;
BA_ "UserSigValidity" SG_ 2328016129 VCU_EvDrvRdyCluDispSta 7;
BA_ "Description" SG_ 2328016129 VCU_EvDrvRdyCluDispSta "EV Drive Ready for Cluster Display Only";
BA_ "Version" SG_ 2328016129 VCU_PwrDnModeSta "19.03.03";
BA_ "RoutingFactor" SG_ 2328016129 VCU_PwrDnModeSta 2;
BA_ "UserSigValidity" SG_ 2328016129 VCU_PwrDnModeSta 7;
BA_ "Description" SG_ 2328016129 VCU_PwrDnModeSta "Power Down Mode";
BA_ "Version" SG_ 2328016129 VCU_CluWarnMsgSta "19.03.03";
BA_ "RoutingFactor" SG_ 2328016129 VCU_CluWarnMsgSta 2;
BA_ "UserSigValidity" SG_ 2328016129 VCU_CluWarnMsgSta 7;
BA_ "Description" SG_ 2328016129 VCU_CluWarnMsgSta "Cluster Warning Message";
BA_ "Version" SG_ 2328016129 VCU_DteOffDispSta "19.06.02";
BA_ "RoutingFactor" SG_ 2328016129 VCU_DteOffDispSta 2;
BA_ "UserSigValidity" SG_ 2328016129 VCU_DteOffDispSta 7;
BA_ "Description" SG_ 2328016129 VCU_DteOffDispSta "DTE Off('---' Display)";
BA_ "Version" SG_ 2328016129 VCU_LowSocAlertSta "19.03.03";
BA_ "RoutingFactor" SG_ 2328016129 VCU_LowSocAlertSta 2;
BA_ "UserSigValidity" SG_ 2328016129 VCU_LowSocAlertSta 7;
BA_ "Description" SG_ 2328016129 VCU_LowSocAlertSta "Low SOC Alert of High-Voltage Battery";
BA_ "Version" SG_ 2328016129 VCU_VcrmReq "19.03.03";
BA_ "RoutingFactor" SG_ 2328016129 VCU_VcrmReq 2;
BA_ "UserSigValidity" SG_ 2328016129 VCU_VcrmReq 7;
BA_ "Description" SG_ 2328016129 VCU_VcrmReq "VCRM Trigger Signal(Request VCRM Data Logging)";
BA_ "Version" SG_ 2328016129 VCU_PdlWarnMsgSta "19.03.03";
BA_ "RoutingFactor" SG_ 2328016129 VCU_PdlWarnMsgSta 2;
BA_ "UserSigValidity" SG_ 2328016129 VCU_PdlWarnMsgSta 7;
BA_ "Version" SG_ 2328016129 VCU_AwdDiagDispSta "20.01.00";
BA_ "RoutingFactor" SG_ 2328016129 VCU_AwdDiagDispSta 2;
BA_ "UserSigValidity" SG_ 2328016129 VCU_AwdDiagDispSta 7;
BA_ "Description" SG_ 2328016129 VCU_AwdDiagDispSta "e4WD Diagnosis Display Status";
BA_ "Version" SG_ 2328016129 VCU_AwdLockDispSta "20.01.00";
BA_ "RoutingFactor" SG_ 2328016129 VCU_AwdLockDispSta 2;
BA_ "UserSigValidity" SG_ 2328016129 VCU_AwdLockDispSta 7;
BA_ "Description" SG_ 2328016129 VCU_AwdLockDispSta "e4WD Lock Mode Display Status";
BA_ "Version" SG_ 2328016129 VCU_VirtualApsActSta "19.03.03";
BA_ "RoutingFactor" SG_ 2328016129 VCU_VirtualApsActSta 2;
BA_ "UserSigValidity" SG_ 2328016129 VCU_VirtualApsActSta 7;
BA_ "Description" SG_ 2328016129 VCU_VirtualApsActSta "Virtual APS Activated";
BA_ "Version" SG_ 2328016129 VCU_VirtualApsVal "19.03.03";
BA_ "RoutingFactor" SG_ 2328016129 VCU_VirtualApsVal 2;
BA_ "UserSigValidity" SG_ 2328016129 VCU_VirtualApsVal 7;
BA_ "Description" SG_ 2328016129 VCU_VirtualApsVal "Estimated Accelerator Pedal Value when Auto Cruise Mode";
BA_ "Version" SG_ 2328016129 VCU_ServiceLampReq "19.03.03";
BA_ "RoutingFactor" SG_ 2328016129 VCU_ServiceLampReq 2;
BA_ "UserSigValidity" SG_ 2328016129 VCU_ServiceLampReq 7;
BA_ "Description" SG_ 2328016129 VCU_ServiceLampReq "Sevice Lamp Request";
BA_ "Version" SG_ 2328016129 VCU_ServiceModeSta "20.10.00";
BA_ "RoutingFactor" SG_ 2328016129 VCU_ServiceModeSta 2;
BA_ "UserSigValidity" SG_ 2328016129 VCU_ServiceModeSta 7;
BA_ "Description" SG_ 2328016129 VCU_ServiceModeSta "Service Mode";
BA_ "Version" SG_ 2328016129 VCU_NPosWshModSta "19.07.06";
BA_ "RoutingFactor" SG_ 2328016129 VCU_NPosWshModSta 2;
BA_ "UserSigValidity" SG_ 2328016129 VCU_NPosWshModSta 7;
BA_ "Description" SG_ 2328016129 VCU_NPosWshModSta "N Wash Mode Status";
BA_ "Version" SG_ 2328016129 VCU_PowerTrainType "19.03.03";
BA_ "RoutingFactor" SG_ 2328016129 VCU_PowerTrainType 2;
BA_ "UserSigValidity" SG_ 2328016129 VCU_PowerTrainType 7;
BA_ "Description" SG_ 2328016129 VCU_PowerTrainType "VCU_PowerTrainType";
BA_ "Version" SG_ 2328016130 VCU_DteBaseVal "19.03.03";
BA_ "RoutingFactor" SG_ 2328016130 VCU_DteBaseVal 2;
BA_ "UserSigValidity" SG_ 2328016130 VCU_DteBaseVal 7;
BA_ "Description" SG_ 2328016130 VCU_DteBaseVal "Maximum Drivable Distance_Adaption";
BA_ "Version" SG_ 2328016130 VCU_AvnDteOnCalcSta "19.03.03";
BA_ "RoutingFactor" SG_ 2328016130 VCU_AvnDteOnCalcSta 2;
BA_ "UserSigValidity" SG_ 2328016130 VCU_AvnDteOnCalcSta 7;
BA_ "Description" SG_ 2328016130 VCU_AvnDteOnCalcSta "DTE calculation status";
BA_ "Version" SG_ 2328016130 VCU_SbwWarnMsgSta "19.06.02";
BA_ "RoutingFactor" SG_ 2328016130 VCU_SbwWarnMsgSta 2;
BA_ "UserSigValidity" SG_ 2328016130 VCU_SbwWarnMsgSta 7;
BA_ "Description" SG_ 2328016130 VCU_SbwWarnMsgSta "SBW Warning Message";
BA_ "Version" SG_ 2328016130 VCU_DteNaviRouteVal "19.03.03";
BA_ "RoutingFactor" SG_ 2328016130 VCU_DteNaviRouteVal 2;
BA_ "UserSigValidity" SG_ 2328016130 VCU_DteNaviRouteVal 7;
BA_ "Description" SG_ 2328016130 VCU_DteNaviRouteVal "Drivable distance for calculation AVN DTE";
BA_ "Version" SG_ 2328016130 VCU_DteAddVal "19.03.03";
BA_ "RoutingFactor" SG_ 2328016130 VCU_DteAddVal 2;
BA_ "UserSigValidity" SG_ 2328016130 VCU_DteAddVal 7;
BA_ "Description" SG_ 2328016130 VCU_DteAddVal "Added Drivable Distance by DATC Off";
BA_ "Version" SG_ 2328016130 VCU_PwrGaugeVal "19.03.03";
BA_ "RoutingFactor" SG_ 2328016130 VCU_PwrGaugeVal 2;
BA_ "UserSigValidity" SG_ 2328016130 VCU_PwrGaugeVal 7;
BA_ "Description" SG_ 2328016130 VCU_PwrGaugeVal "Motor Torque Ratio To Cluster

:VCU send this signal to cluster to show motor power status";
BA_ "Version" SG_ 2328016130 VCU_EnergyFlowSta "20.09.00";
BA_ "RoutingFactor" SG_ 2328016130 VCU_EnergyFlowSta 2;
BA_ "UserSigValidity" SG_ 2328016130 VCU_EnergyFlowSta 7;
BA_ "Description" SG_ 2328016130 VCU_EnergyFlowSta "Energy Flow Display Status";
BA_ "Version" SG_ 2328016130 VCU_SbwWarnSndSta "19.06.02";
BA_ "RoutingFactor" SG_ 2328016130 VCU_SbwWarnSndSta 2;
BA_ "UserSigValidity" SG_ 2328016130 VCU_SbwWarnSndSta 7;
BA_ "Description" SG_ 2328016130 VCU_SbwWarnSndSta "SBW Warning Sound";
BA_ "Version" SG_ 2328016130 VCU_EcoGuide_DispReq "19.03.03";
BA_ "RoutingFactor" SG_ 2328016130 VCU_EcoGuide_DispReq 2;
BA_ "UserSigValidity" SG_ 2328016130 VCU_EcoGuide_DispReq 7;
BA_ "Description" SG_ 2328016130 VCU_EcoGuide_DispReq "Display On/Off";
BA_ "Version" SG_ 2328016130 VCU_EcoGuide_ApsGaugeVal "19.03.03";
BA_ "RoutingFactor" SG_ 2328016130 VCU_EcoGuide_ApsGaugeVal 2;
BA_ "UserSigValidity" SG_ 2328016130 VCU_EcoGuide_ApsGaugeVal 7;
BA_ "Description" SG_ 2328016130 VCU_EcoGuide_ApsGaugeVal "APS Gauge Display for Smart ECO Guide";
BA_ "Version" SG_ 2328016130 VCU_EcoGuide_EcoGaugeVal "19.03.03";
BA_ "RoutingFactor" SG_ 2328016130 VCU_EcoGuide_EcoGaugeVal 2;
BA_ "UserSigValidity" SG_ 2328016130 VCU_EcoGuide_EcoGaugeVal 7;
BA_ "Description" SG_ 2328016130 VCU_EcoGuide_EcoGaugeVal "ECO Range Display for Smart ECO Guide";
BA_ "Version" SG_ 2328016131 VCU_TgSocDteAcChgVal "19.03.03";
BA_ "RoutingFactor" SG_ 2328016131 VCU_TgSocDteAcChgVal 2;
BA_ "UserSigValidity" SG_ 2328016131 VCU_TgSocDteAcChgVal 7;
BA_ "Description" SG_ 2328016131 VCU_TgSocDteAcChgVal "Estimated DTE for slow charger(SC/AC) target SOC";
BA_ "Version" SG_ 2328016131 VCU_TgSocDteDcChgVal "19.03.03";
BA_ "RoutingFactor" SG_ 2328016131 VCU_TgSocDteDcChgVal 2;
BA_ "UserSigValidity" SG_ 2328016131 VCU_TgSocDteDcChgVal 7;
BA_ "Description" SG_ 2328016131 VCU_TgSocDteDcChgVal "Estimated DTE for fast charger(QC/DC) target SOC";
BA_ "Version" SG_ 2328016131 VCU_DistFromRegenDispReq "19.03.03";
BA_ "RoutingFactor" SG_ 2328016131 VCU_DistFromRegenDispReq 2;
BA_ "UserSigValidity" SG_ 2328016131 VCU_DistFromRegenDispReq 7;
BA_ "Description" SG_ 2328016131 VCU_DistFromRegenDispReq "Distance from Regeneration Display status";
BA_ "Version" SG_ 2328016131 VCU_DistFromRegenVal "19.03.03";
BA_ "RoutingFactor" SG_ 2328016131 VCU_DistFromRegenVal 2;
BA_ "UserSigValidity" SG_ 2328016131 VCU_DistFromRegenVal 7;
BA_ "Description" SG_ 2328016131 VCU_DistFromRegenVal "DTE Increment at Regeneration";
BA_ "Version" SG_ 2328016131 VCU_DrvStyle_DispReq "19.03.03";
BA_ "RoutingFactor" SG_ 2328016131 VCU_DrvStyle_DispReq 2;
BA_ "UserSigValidity" SG_ 2328016131 VCU_DrvStyle_DispReq 7;
BA_ "Description" SG_ 2328016131 VCU_DrvStyle_DispReq "Fuel Efficiency Percent Display Status";
BA_ "Version" SG_ 2328016131 VCU_DrvStyle_HighLightSta "19.03.03";
BA_ "RoutingFactor" SG_ 2328016131 VCU_DrvStyle_HighLightSta 2;
BA_ "UserSigValidity" SG_ 2328016131 VCU_DrvStyle_HighLightSta 7;
BA_ "Description" SG_ 2328016131 VCU_DrvStyle_HighLightSta "Fuel Efficiency High Light Status";
BA_ "Version" SG_ 2328016131 VCU_DrvStyle_EcoVal "19.03.03";
BA_ "RoutingFactor" SG_ 2328016131 VCU_DrvStyle_EcoVal 2;
BA_ "UserSigValidity" SG_ 2328016131 VCU_DrvStyle_EcoVal 7;
BA_ "Description" SG_ 2328016131 VCU_DrvStyle_EcoVal "High Fuel Efficiency Percent Value";
BA_ "Version" SG_ 2328016131 VCU_DrvStyle_NonEcoVal "19.03.03";
BA_ "RoutingFactor" SG_ 2328016131 VCU_DrvStyle_NonEcoVal 2;
BA_ "UserSigValidity" SG_ 2328016131 VCU_DrvStyle_NonEcoVal 7;
BA_ "Description" SG_ 2328016131 VCU_DrvStyle_NonEcoVal "Low Fuel Efficiency Percent Value";
BA_ "Version" SG_ 2328016131 VCU_DrvStyle_NorVal "19.03.03";
BA_ "RoutingFactor" SG_ 2328016131 VCU_DrvStyle_NorVal 2;
BA_ "UserSigValidity" SG_ 2328016131 VCU_DrvStyle_NorVal 7;
BA_ "Description" SG_ 2328016131 VCU_DrvStyle_NorVal "Normal Fuel Efficiency Percent Value";
BA_ "Version" SG_ 200 CF_AVN_ADrLNValueSet_2 "21.01.06";
BA_ "RoutingFactor" SG_ 200 CF_AVN_ADrLNValueSet_2 0;
BA_ "UserSigValidity" SG_ 200 CF_AVN_ADrLNValueSet_2 3;
BA_ "GenSigSendType" SG_ 200 CF_AVN_ADrLNValueSet_2 4;
BA_ "Description" SG_ 200 CF_AVN_ADrLNValueSet_2 "USM Reqeust for Auto Door Lock";
BA_ "Version" SG_ 200 CF_AVN_FCA_JC_OnOffEquipNvalueSe "20.12.00";
BA_ "RoutingFactor" SG_ 200 CF_AVN_FCA_JC_OnOffEquipNvalueSe 0;
BA_ "UserSigValidity" SG_ 200 CF_AVN_FCA_JC_OnOffEquipNvalueSe 3;
BA_ "GenSigSendType" SG_ 200 CF_AVN_FCA_JC_OnOffEquipNvalueSe 4;
BA_ "Description" SG_ 200 CF_AVN_FCA_JC_OnOffEquipNvalueSe "USM Set signal for Forward Corss-traffic";
BA_ "SystemSignalLongSymbol" SG_ 200 CF_AVN_FCA_JC_OnOffEquipNvalueSe "CF_AVN_FCA_JC_OnOffEquipNvalueSet";
BA_ "Version" SG_ 200 CF_AVN_FCA_FrSdOnOffEquipNvalueS "20.12.00";
BA_ "RoutingFactor" SG_ 200 CF_AVN_FCA_FrSdOnOffEquipNvalueS 0;
BA_ "UserSigValidity" SG_ 200 CF_AVN_FCA_FrSdOnOffEquipNvalueS 3;
BA_ "GenSigSendType" SG_ 200 CF_AVN_FCA_FrSdOnOffEquipNvalueS 4;
BA_ "Description" SG_ 200 CF_AVN_FCA_FrSdOnOffEquipNvalueS "USM Set signal for Forward/Side Safety";
BA_ "SystemSignalLongSymbol" SG_ 200 CF_AVN_FCA_FrSdOnOffEquipNvalueS "CF_AVN_FCA_FrSdOnOffEquipNvalueSet";
BA_ "Version" SG_ 200 CF_AVN_LKA_OnOffEquip2NvalueSet "20.12.00";
BA_ "RoutingFactor" SG_ 200 CF_AVN_LKA_OnOffEquip2NvalueSet 0;
BA_ "UserSigValidity" SG_ 200 CF_AVN_LKA_OnOffEquip2NvalueSet 3;
BA_ "GenSigSendType" SG_ 200 CF_AVN_LKA_OnOffEquip2NvalueSet 4;
BA_ "Description" SG_ 200 CF_AVN_LKA_OnOffEquip2NvalueSet "USM Set Signal for Lane safety";
BA_ "Version" SG_ 200 CF_AVN_BCA_OnOffEquip2NvalueSet "20.12.00";
BA_ "RoutingFactor" SG_ 200 CF_AVN_BCA_OnOffEquip2NvalueSet 0;
BA_ "UserSigValidity" SG_ 200 CF_AVN_BCA_OnOffEquip2NvalueSet 3;
BA_ "GenSigSendType" SG_ 200 CF_AVN_BCA_OnOffEquip2NvalueSet 4;
BA_ "Description" SG_ 200 CF_AVN_BCA_OnOffEquip2NvalueSet "USM Set signal for Side/Rear Safety";
BA_ "Version" SG_ 200 CF_AVN_BVM_OnOffEquipNvalueSet "20.12.00";
BA_ "RoutingFactor" SG_ 200 CF_AVN_BVM_OnOffEquipNvalueSet 0;
BA_ "UserSigValidity" SG_ 200 CF_AVN_BVM_OnOffEquipNvalueSet 3;
BA_ "GenSigSendType" SG_ 200 CF_AVN_BVM_OnOffEquipNvalueSet 4;
BA_ "Description" SG_ 200 CF_AVN_BVM_OnOffEquipNvalueSet "USM Set signal for Blind Spot View";
BA_ "Version" SG_ 200 CF_AVN_SEA_OnOffEquip3NvalueSet "20.12.00";
BA_ "RoutingFactor" SG_ 200 CF_AVN_SEA_OnOffEquip3NvalueSet 0;
BA_ "UserSigValidity" SG_ 200 CF_AVN_SEA_OnOffEquip3NvalueSet 3;
BA_ "GenSigSendType" SG_ 200 CF_AVN_SEA_OnOffEquip3NvalueSet 4;
BA_ "Description" SG_ 200 CF_AVN_SEA_OnOffEquip3NvalueSet "Usm Set signal for safety exit assist";
BA_ "Version" SG_ 200 CF_AVN_BodySpprtSet_AST "20.10.02";
BA_ "RoutingFactor" SG_ 200 CF_AVN_BodySpprtSet_AST 0;
BA_ "UserSigValidity" SG_ 200 CF_AVN_BodySpprtSet_AST 3;
BA_ "GenSigStartValue" SG_ 200 CF_AVN_BodySpprtSet_AST 3;
BA_ "GenSigSendType" SG_ 200 CF_AVN_BodySpprtSet_AST 4;
BA_ "Description" SG_ 200 CF_AVN_BodySpprtSet_AST "Ergo-Motion Seat Smart Posture Assist";
BA_ "Version" SG_ 200 CF_AVN_SEW_OnOffEquip3NvalueSet "20.12.00";
BA_ "RoutingFactor" SG_ 200 CF_AVN_SEW_OnOffEquip3NvalueSet 0;
BA_ "UserSigValidity" SG_ 200 CF_AVN_SEW_OnOffEquip3NvalueSet 3;
BA_ "GenSigSendType" SG_ 200 CF_AVN_SEW_OnOffEquip3NvalueSet 4;
BA_ "Description" SG_ 200 CF_AVN_SEW_OnOffEquip3NvalueSet "Usm Set signal for Safety exit warning";
BA_ "Version" SG_ 200 CF_AVN_HudImsAutoSave "20.12.05";
BA_ "RoutingFactor" SG_ 200 CF_AVN_HudImsAutoSave 0;
BA_ "UserSigValidity" SG_ 200 CF_AVN_HudImsAutoSave 3;
BA_ "GenSigSendType" SG_ 200 CF_AVN_HudImsAutoSave 4;
BA_ "Description" SG_ 200 CF_AVN_HudImsAutoSave "USM request for auto save HUD setting with IMS";
BA_ "Version" SG_ 200 USM_PwrDrBuzzerNValueSet "21.01.06";
BA_ "RoutingFactor" SG_ 200 USM_PwrDrBuzzerNValueSet 0;
BA_ "UserSigValidity" SG_ 200 USM_PwrDrBuzzerNValueSet 3;
BA_ "GenSigSendType" SG_ 200 USM_PwrDrBuzzerNValueSet 4;
BA_ "Description" SG_ 200 USM_PwrDrBuzzerNValueSet "USM Request for Power Door Buzzer";
BA_ "Version" SG_ 200 CF_AVN_DWLNValueSet "21.01.01";
BA_ "RoutingFactor" SG_ 200 CF_AVN_DWLNValueSet 0;
BA_ "UserSigValidity" SG_ 200 CF_AVN_DWLNValueSet 3;
BA_ "GenSigSendType" SG_ 200 CF_AVN_DWLNValueSet 4;
BA_ "Description" SG_ 200 CF_AVN_DWLNValueSet "Request for USM Dynamic Welcome Light";
BA_ "Version" SG_ 200 CF_AVN_AirSptTimeNValueSet_AST "20.10.02";
BA_ "RoutingFactor" SG_ 200 CF_AVN_AirSptTimeNValueSet_AST 0;
BA_ "UserSigValidity" SG_ 200 CF_AVN_AirSptTimeNValueSet_AST 3;
BA_ "GenSigStartValue" SG_ 200 CF_AVN_AirSptTimeNValueSet_AST 7;
BA_ "GenSigSendType" SG_ 200 CF_AVN_AirSptTimeNValueSet_AST 4;
BA_ "Description" SG_ 200 CF_AVN_AirSptTimeNValueSet_AST "Ergo-Motion Seat Comfortable Stretch Operational Time";
BA_ "Version" SG_ 200 CF_AVN_AirSptStrNValue_AST "20.10.02";
BA_ "RoutingFactor" SG_ 200 CF_AVN_AirSptStrNValue_AST 0;
BA_ "UserSigValidity" SG_ 200 CF_AVN_AirSptStrNValue_AST 3;
BA_ "GenSigStartValue" SG_ 200 CF_AVN_AirSptStrNValue_AST 3;
BA_ "GenSigSendType" SG_ 200 CF_AVN_AirSptStrNValue_AST 4;
BA_ "Description" SG_ 200 CF_AVN_AirSptStrNValue_AST "Ergo-Motion Seat Comfortable Stretch Strong/Normal";
BA_ "Version" SG_ 200 CF_AVN_SeatDrvModNvalueSet_AST "20.12.00";
BA_ "RoutingFactor" SG_ 200 CF_AVN_SeatDrvModNvalueSet_AST 0;
BA_ "UserSigValidity" SG_ 200 CF_AVN_SeatDrvModNvalueSet_AST 3;
BA_ "GenSigStartValue" SG_ 200 CF_AVN_SeatDrvModNvalueSet_AST 3;
BA_ "GenSigSendType" SG_ 200 CF_AVN_SeatDrvModNvalueSet_AST 4;
BA_ "Description" SG_ 200 CF_AVN_SeatDrvModNvalueSet_AST "Ergo-Motion Seat Smart Support";
BA_ "Version" SG_ 200 CF_AVN_TPMS_TireReplaceNValueSet "20.12.04";
BA_ "RoutingFactor" SG_ 200 CF_AVN_TPMS_TireReplaceNValueSet 0;
BA_ "UserSigValidity" SG_ 200 CF_AVN_TPMS_TireReplaceNValueSet 3;
BA_ "GenSigSendType" SG_ 200 CF_AVN_TPMS_TireReplaceNValueSet 4;
BA_ "Description" SG_ 200 CF_AVN_TPMS_TireReplaceNValueSet "USM Set Signal for Standard Tire to Wnter Tire";
BA_ "Version" SG_ 200 CF_AVN_TowModeSet "20.12.04";
BA_ "RoutingFactor" SG_ 200 CF_AVN_TowModeSet 0;
BA_ "UserSigValidity" SG_ 200 CF_AVN_TowModeSet 3;
BA_ "GenSigSendType" SG_ 200 CF_AVN_TowModeSet 4;
BA_ "Description" SG_ 200 CF_AVN_TowModeSet "USM Set signal For TowMode";
BA_ "Version" SG_ 200 USM_PwrDrCloseByBraekNValueSet "21.01.06";
BA_ "RoutingFactor" SG_ 200 USM_PwrDrCloseByBraekNValueSet 0;
BA_ "UserSigValidity" SG_ 200 USM_PwrDrCloseByBraekNValueSet 3;
BA_ "GenSigSendType" SG_ 200 USM_PwrDrCloseByBraekNValueSet 4;
BA_ "Description" SG_ 200 USM_PwrDrCloseByBraekNValueSet "USM Reqeust for Power Door Close by Brake";
BA_ "Version" SG_ 200 CF_AVN_ISLANAOffstNvalueSet "21.03.10";
BA_ "RoutingFactor" SG_ 200 CF_AVN_ISLANAOffstNvalueSet 0;
BA_ "UserSigValidity" SG_ 200 CF_AVN_ISLANAOffstNvalueSet 3;
BA_ "GenSigSendType" SG_ 200 CF_AVN_ISLANAOffstNvalueSet 4;
BA_ "Description" SG_ 200 CF_AVN_ISLANAOffstNvalueSet "Control ISLA offset on USM Fucntion (North America)";
BA_ "Version" SG_ 200 CF_Gway_WPC2_NValueSet "22.02.05";
BA_ "RoutingFactor" SG_ 200 CF_Gway_WPC2_NValueSet 0;
BA_ "UserSigValidity" SG_ 200 CF_Gway_WPC2_NValueSet 3;
BA_ "GenSigSendType" SG_ 200 CF_Gway_WPC2_NValueSet 4;
BA_ "Description" SG_ 200 CF_Gway_WPC2_NValueSet "USM Set signal for 2nd WPC setting";
BA_ "Version" SG_ 200 USM_DrvGhostDoorReq "21.03.11";
BA_ "RoutingFactor" SG_ 200 USM_DrvGhostDoorReq 0;
BA_ "UserSigValidity" SG_ 200 USM_DrvGhostDoorReq 3;
BA_ "GenSigSendType" SG_ 200 USM_DrvGhostDoorReq 4;
BA_ "Description" SG_ 200 USM_DrvGhostDoorReq "USM Request for Driver Door Ghost Door Closing On/Off";
BA_ "Version" SG_ 200 USM_AstGhostDoorReq "21.03.11";
BA_ "RoutingFactor" SG_ 200 USM_AstGhostDoorReq 0;
BA_ "UserSigValidity" SG_ 200 USM_AstGhostDoorReq 3;
BA_ "GenSigSendType" SG_ 200 USM_AstGhostDoorReq 4;
BA_ "Description" SG_ 200 USM_AstGhostDoorReq "USM Request for Assistant Ghost Door Closing On/Off";
BA_ "Version" SG_ 200 USM_RLGhostDoorReq "21.03.11";
BA_ "RoutingFactor" SG_ 200 USM_RLGhostDoorReq 0;
BA_ "UserSigValidity" SG_ 200 USM_RLGhostDoorReq 3;
BA_ "GenSigSendType" SG_ 200 USM_RLGhostDoorReq 4;
BA_ "Description" SG_ 200 USM_RLGhostDoorReq "USM Request for Rear Left Ghost Door Closing On/Off";
BA_ "Version" SG_ 200 USM_RRGhostDoorReq "21.03.11";
BA_ "RoutingFactor" SG_ 200 USM_RRGhostDoorReq 0;
BA_ "UserSigValidity" SG_ 200 USM_RRGhostDoorReq 3;
BA_ "GenSigSendType" SG_ 200 USM_RRGhostDoorReq 4;
BA_ "Description" SG_ 200 USM_RRGhostDoorReq "USM Request for Rear Right Ghost Door Closing On/Off";
BA_ "Version" SG_ 200 CF_AVN_FCA_FrOnOffEquipNvalueSet "20.12.00";
BA_ "RoutingFactor" SG_ 200 CF_AVN_FCA_FrOnOffEquipNvalueSet 0;
BA_ "UserSigValidity" SG_ 200 CF_AVN_FCA_FrOnOffEquipNvalueSet 3;
BA_ "GenSigSendType" SG_ 200 CF_AVN_FCA_FrOnOffEquipNvalueSet 4;
BA_ "Description" SG_ 200 CF_AVN_FCA_FrOnOffEquipNvalueSet "USM Set Signal for Forward Safety";
BA_ "Version" SG_ 200 CF_AVN_FCA_WarnTimeNvalueSet "20.12.00";
BA_ "RoutingFactor" SG_ 200 CF_AVN_FCA_WarnTimeNvalueSet 0;
BA_ "UserSigValidity" SG_ 200 CF_AVN_FCA_WarnTimeNvalueSet 3;
BA_ "GenSigSendType" SG_ 200 CF_AVN_FCA_WarnTimeNvalueSet 4;
BA_ "Description" SG_ 200 CF_AVN_FCA_WarnTimeNvalueSet "USM Set signal for Forward Warntime";
BA_ "Version" SG_ 1159 C_AstRclBwdSw_HU "19.11.05";
BA_ "UserSigValidity" SG_ 1159 C_AstRclBwdSw_HU 0;
BA_ "GenSigSendType" SG_ 1159 C_AstRclBwdSw_HU 4;
BA_ "Version" SG_ 1159 C_AstHeightUpSw_HU "19.11.05";
BA_ "UserSigValidity" SG_ 1159 C_AstHeightUpSw_HU 0;
BA_ "GenSigSendType" SG_ 1159 C_AstHeightUpSw_HU 4;
BA_ "Version" SG_ 1159 C_AstTiltDnSw_HU "19.11.05";
BA_ "UserSigValidity" SG_ 1159 C_AstTiltDnSw_HU 0;
BA_ "GenSigSendType" SG_ 1159 C_AstTiltDnSw_HU 4;
BA_ "Version" SG_ 1159 C_AstTiltUpSw_HU "19.11.05";
BA_ "UserSigValidity" SG_ 1159 C_AstTiltUpSw_HU 0;
BA_ "GenSigSendType" SG_ 1159 C_AstTiltUpSw_HU 4;
BA_ "Version" SG_ 1159 C_AstLumbarDefSw_HU "19.11.05";
BA_ "UserSigValidity" SG_ 1159 C_AstLumbarDefSw_HU 0;
BA_ "GenSigSendType" SG_ 1159 C_AstLumbarDefSw_HU 4;
BA_ "Version" SG_ 1159 C_AstLumbarLowSw_HU "19.11.05";
BA_ "UserSigValidity" SG_ 1159 C_AstLumbarLowSw_HU 0;
BA_ "GenSigSendType" SG_ 1159 C_AstLumbarLowSw_HU 4;
BA_ "Version" SG_ 1159 C_AstRclFwdSw_HU "19.11.05";
BA_ "UserSigValidity" SG_ 1159 C_AstRclFwdSw_HU 0;
BA_ "GenSigSendType" SG_ 1159 C_AstRclFwdSw_HU 4;
BA_ "Version" SG_ 1159 C_AstLumbarMidSw_HU "19.11.05";
BA_ "UserSigValidity" SG_ 1159 C_AstLumbarMidSw_HU 0;
BA_ "GenSigSendType" SG_ 1159 C_AstLumbarMidSw_HU 4;
BA_ "Version" SG_ 1159 C_AstLumbarUpSw_HU "19.11.05";
BA_ "UserSigValidity" SG_ 1159 C_AstLumbarUpSw_HU 0;
BA_ "GenSigSendType" SG_ 1159 C_AstLumbarUpSw_HU 4;
BA_ "Version" SG_ 1159 C_RRSlideFwdSw_HU "19.11.05";
BA_ "UserSigValidity" SG_ 1159 C_RRSlideFwdSw_HU 0;
BA_ "GenSigSendType" SG_ 1159 C_RRSlideFwdSw_HU 4;
BA_ "Version" SG_ 1159 C_RRSlideBwdSw_HU "19.11.05";
BA_ "UserSigValidity" SG_ 1159 C_RRSlideBwdSw_HU 0;
BA_ "GenSigSendType" SG_ 1159 C_RRSlideBwdSw_HU 4;
BA_ "Version" SG_ 1159 C_RLSlideFwdSw_HU "19.11.05";
BA_ "UserSigValidity" SG_ 1159 C_RLSlideFwdSw_HU 0;
BA_ "GenSigSendType" SG_ 1159 C_RLSlideFwdSw_HU 4;
BA_ "Version" SG_ 1159 C_RLSlideBwdSw_HU "19.11.05";
BA_ "UserSigValidity" SG_ 1159 C_RLSlideBwdSw_HU 0;
BA_ "GenSigSendType" SG_ 1159 C_RLSlideBwdSw_HU 4;
BA_ "Version" SG_ 1159 C_AstSlideBwdSw_HU "19.11.05";
BA_ "UserSigValidity" SG_ 1159 C_AstSlideBwdSw_HU 0;
BA_ "GenSigSendType" SG_ 1159 C_AstSlideBwdSw_HU 4;
BA_ "Version" SG_ 1159 C_AstSlideFwdSw_HU "19.11.05";
BA_ "UserSigValidity" SG_ 1159 C_AstSlideFwdSw_HU 0;
BA_ "GenSigSendType" SG_ 1159 C_AstSlideFwdSw_HU 4;
BA_ "Version" SG_ 1159 C_AstHeightDnSw_HU "19.11.05";
BA_ "UserSigValidity" SG_ 1159 C_AstHeightDnSw_HU 0;
BA_ "GenSigSendType" SG_ 1159 C_AstHeightDnSw_HU 4;
BA_ "Version" SG_ 197 C_DrvRclBwdSw_HU "20.01.02";
BA_ "RoutingFactor" SG_ 197 C_DrvRclBwdSw_HU 0;
BA_ "UserSigValidity" SG_ 197 C_DrvRclBwdSw_HU 0;
BA_ "GenSigSendType" SG_ 197 C_DrvRclBwdSw_HU 4;
BA_ "Version" SG_ 197 C_DrvSlideFwdSw_HU "20.01.02";
BA_ "RoutingFactor" SG_ 197 C_DrvSlideFwdSw_HU 0;
BA_ "UserSigValidity" SG_ 197 C_DrvSlideFwdSw_HU 0;
BA_ "GenSigSendType" SG_ 197 C_DrvSlideFwdSw_HU 4;
BA_ "Version" SG_ 197 C_RLLegSupFwdSw_HU "20.05.03";
BA_ "RoutingFactor" SG_ 197 C_RLLegSupFwdSw_HU 0;
BA_ "UserSigValidity" SG_ 197 C_RLLegSupFwdSw_HU 0;
BA_ "GenSigSendType" SG_ 197 C_RLLegSupFwdSw_HU 4;
BA_ "Version" SG_ 197 C_RLLegSupBwdSw_HU "20.05.03";
BA_ "RoutingFactor" SG_ 197 C_RLLegSupBwdSw_HU 0;
BA_ "UserSigValidity" SG_ 197 C_RLLegSupBwdSw_HU 0;
BA_ "GenSigSendType" SG_ 197 C_RLLegSupBwdSw_HU 4;
BA_ "Version" SG_ 197 C_DrvSlideBwdSw_HU "20.01.02";
BA_ "RoutingFactor" SG_ 197 C_DrvSlideBwdSw_HU 0;
BA_ "UserSigValidity" SG_ 197 C_DrvSlideBwdSw_HU 0;
BA_ "GenSigSendType" SG_ 197 C_DrvSlideBwdSw_HU 4;
BA_ "Version" SG_ 197 C_RLLegSupUpSw_HU "20.05.03";
BA_ "RoutingFactor" SG_ 197 C_RLLegSupUpSw_HU 0;
BA_ "UserSigValidity" SG_ 197 C_RLLegSupUpSw_HU 0;
BA_ "GenSigSendType" SG_ 197 C_RLLegSupUpSw_HU 4;
BA_ "Version" SG_ 197 C_RLLegSupDnSw_HU "20.05.03";
BA_ "RoutingFactor" SG_ 197 C_RLLegSupDnSw_HU 0;
BA_ "UserSigValidity" SG_ 197 C_RLLegSupDnSw_HU 0;
BA_ "GenSigSendType" SG_ 197 C_RLLegSupDnSw_HU 4;
BA_ "Version" SG_ 197 C_DrvRclFwdSw_HU "20.01.02";
BA_ "RoutingFactor" SG_ 197 C_DrvRclFwdSw_HU 0;
BA_ "UserSigValidity" SG_ 197 C_DrvRclFwdSw_HU 0;
BA_ "GenSigSendType" SG_ 197 C_DrvRclFwdSw_HU 4;
BA_ "Version" SG_ 2382595073 DATC_Crc7Val "21.09.03";
BA_ "UserSigValidity" SG_ 2382595073 DATC_Crc7Val 3;
BA_ "GenSigStartValue" SG_ 2382595073 DATC_Crc7Val 65535;
BA_ "GenSigSendType" SG_ 2382595073 DATC_Crc7Val 4;
BA_ "Description" SG_ 2382595073 DATC_Crc7Val "The data area for CRC calculation is based on the data length (DLC) of the message DB.

The CRC shall be calculated over the entire data block (excluding the CRC bytes) including the user data, alive counter and Data ID



- CRC Polynomial (0x1021) , Ini";
BA_ "Version" SG_ 2382595073 DATC_AlvCnt7Val "21.09.03";
BA_ "UserSigValidity" SG_ 2382595073 DATC_AlvCnt7Val 3;
BA_ "GenSigSendType" SG_ 2382595073 DATC_AlvCnt7Val 4;
BA_ "Description" SG_ 2382595073 DATC_AlvCnt7Val "For the first transmission request for a data element the counter shall be initialized with 0 and shall be incremented by 1 for every subsequent send request. 

When the counter reaches the maximum value(0xFF), then it shall restart with 0 for the next s";
BA_ "Version" SG_ 2382595073 DATC_FrDrvBlwDis "18.11.06";
BA_ "UserSigValidity" SG_ 2382595073 DATC_FrDrvBlwDis 7;
BA_ "GenSigSendType" SG_ 2382595073 DATC_FrDrvBlwDis 4;
BA_ "Description" SG_ 2382595073 DATC_FrDrvBlwDis "This signal indicates step of Front blower Graphic.

This signal occurs when Front Blower switch(button) is selected either manually or automatically.";
BA_ "Version" SG_ 2382595073 DATC_FrPsBlwDis "19.05.03";
BA_ "UserSigValidity" SG_ 2382595073 DATC_FrPsBlwDis 7;
BA_ "GenSigSendType" SG_ 2382595073 DATC_FrPsBlwDis 4;
BA_ "Version" SG_ 2382595073 DATC_HeatDis "17.11.00";
BA_ "UserSigValidity" SG_ 2382595073 DATC_HeatDis 6;
BA_ "GenSigStartValue" SG_ 2382595073 DATC_HeatDis 3;
BA_ "GenSigSendType" SG_ 2382595073 DATC_HeatDis 4;
BA_ "Description" SG_ 2382595073 DATC_HeatDis "This signal indicates Heat symbol Display";
BA_ "Version" SG_ 2382595073 DATC_EVScrnDis "17.11.00";
BA_ "UserSigValidity" SG_ 2382595073 DATC_EVScrnDis 4;
BA_ "GenSigStartValue" SG_ 2382595073 DATC_EVScrnDis 3;
BA_ "GenSigSendType" SG_ 2382595073 DATC_EVScrnDis 4;
BA_ "Description" SG_ 2382595073 DATC_EVScrnDis "EV Only Screen Display";
BA_ "Version" SG_ 2382595073 DATC_DrvOnlyDis "17.11.00";
BA_ "UserSigValidity" SG_ 2382595073 DATC_DrvOnlyDis 6;
BA_ "GenSigSendType" SG_ 2382595073 DATC_DrvOnlyDis 4;
BA_ "Version" SG_ 2382595073 DATC_DiagCodeDis "22.03.04";
BA_ "UserSigValidity" SG_ 2382595073 DATC_DiagCodeDis 6;
BA_ "GenSigSendType" SG_ 2382595073 DATC_DiagCodeDis 4;
BA_ "Version" SG_ 2382595073 DATC_RrChgReqDis "17.11.00";
BA_ "UserSigValidity" SG_ 2382595073 DATC_RrChgReqDis 6;
BA_ "GenSigSendType" SG_ 2382595073 DATC_RrChgReqDis 4;
BA_ "Description" SG_ 2382595073 DATC_RrChgReqDis "This signal indicates to show Climate Pop-up screen.

This signal occurs when any kinds of climate switch(button)s are selected manually.";
BA_ "Version" SG_ 2382595073 DATC_RrClmtScrnDis "17.11.00";
BA_ "UserSigValidity" SG_ 2382595073 DATC_RrClmtScrnDis 6;
BA_ "GenSigSendType" SG_ 2382595073 DATC_RrClmtScrnDis 4;
BA_ "Description" SG_ 2382595073 DATC_RrClmtScrnDis "This signal indicates that screen change to Climate Full screen.



This signal occurs when Climate switch(button) is selected manually.";
BA_ "Version" SG_ 2382595073 DATC_AUTOStep "18.12.08";
BA_ "UserSigValidity" SG_ 2382595073 DATC_AUTOStep 7;
BA_ "GenSigSendType" SG_ 2382595073 DATC_AUTOStep 4;
BA_ "Description" SG_ 2382595073 DATC_AUTOStep "This signal indicates AUTO step status in case Multi Auto Blower type.";
BA_ "Version" SG_ 2382595073 DATC_IntakeDis "18.12.08";
BA_ "UserSigValidity" SG_ 2382595073 DATC_IntakeDis 7;
BA_ "GenSigSendType" SG_ 2382595073 DATC_IntakeDis 4;
BA_ "Description" SG_ 2382595073 DATC_IntakeDis "This signal indicates intake indicator & display";
BA_ "Version" SG_ 2382595073 DATC_MultiAirModSta "18.12.08";
BA_ "UserSigValidity" SG_ 2382595073 DATC_MultiAirModSta 7;
BA_ "GenSigSendType" SG_ 2382595073 DATC_MultiAirModSta 4;
BA_ "Description" SG_ 2382595073 DATC_MultiAirModSta "This signal indicates MultiAirModeStatus";
BA_ "Version" SG_ 1167 ICU_Crc11Val "18.11.08";
BA_ "UserSigValidity" SG_ 1167 ICU_Crc11Val 0;
BA_ "GenSigStartValue" SG_ 1167 ICU_Crc11Val 255;
BA_ "GenSigSendType" SG_ 1167 ICU_Crc11Val 4;
BA_ "Description" SG_ 1167 ICU_Crc11Val "The data area for CRC calculation is based on the data length (DLC) of the message DB.

The CRC shall be calculated over the entire data block (excluding the CRC bytes) including the user data, alive counter and Data ID 

 

- CRC Polynomial (0x1D) , Ini";
BA_ "Version" SG_ 1167 Bat_dischrg "21.07.05";
BA_ "UserSigValidity" SG_ 1167 Bat_dischrg 3;
BA_ "GenSigSendType" SG_ 1167 Bat_dischrg 4;
BA_ "Description" SG_ 1167 Bat_dischrg "Battery discharge notification flag";
BA_ "Version" SG_ 1167 ICU_AlvCnt11Val "18.11.08";
BA_ "UserSigValidity" SG_ 1167 ICU_AlvCnt11Val 0;
BA_ "GenSigSendType" SG_ 1167 ICU_AlvCnt11Val 4;
BA_ "Description" SG_ 1167 ICU_AlvCnt11Val "For the first transmission request for a data element the counter shall be initialized with 0 and shall be incremented by 1

for every subsequent send request. When the counter reaches the maximum value(0xE), then it shall restart with 0 for the next sen";
BA_ "Version" SG_ 1167 Batt_SoCWarningValue "17.12.00";
BA_ "UserSigValidity" SG_ 1167 Batt_SoCWarningValue 0;
BA_ "GenSigStartValue" SG_ 1167 Batt_SoCWarningValue 255;
BA_ "GenSigSendType" SG_ 1167 Batt_SoCWarningValue 4;
BA_ "Description" SG_ 1167 Batt_SoCWarningValue "This signal is Battery SOC from battery sensor.";
BA_ "Version" SG_ 1167 C_StrgWhlHeatingOpt "18.12.02";
BA_ "UserSigValidity" SG_ 1167 C_StrgWhlHeatingOpt 3;
BA_ "GenSigSendType" SG_ 1167 C_StrgWhlHeatingOpt 4;
BA_ "Description" SG_ 1167 C_StrgWhlHeatingOpt "Steering wheel heating option signal";
BA_ "Version" SG_ 1167 C_StrgWhlHeatingSWInf "19.11.11";
BA_ "UserSigValidity" SG_ 1167 C_StrgWhlHeatingSWInf 3;
BA_ "GenSigSendType" SG_ 1167 C_StrgWhlHeatingSWInf 4;
BA_ "Description" SG_ 1167 C_StrgWhlHeatingSWInf "Steering wheel heating Step information signal";
BA_ "Version" SG_ 1167 ICU_BattAutoCutPreWrng "20.04.06";
BA_ "UserSigValidity" SG_ 1167 ICU_BattAutoCutPreWrng 0;
BA_ "GenSigStartValue" SG_ 1167 ICU_BattAutoCutPreWrng 3;
BA_ "GenSigSendType" SG_ 1167 ICU_BattAutoCutPreWrng 4;
BA_ "Description" SG_ 1167 ICU_BattAutoCutPreWrng "This is a warning signal before blocking the dark current of the ICU by the battery SOC.";
BA_ "Version" SG_ 1167 IGN_AutoOff_WarnSta_CLU "20.07.10";
BA_ "UserSigValidity" SG_ 1167 IGN_AutoOff_WarnSta_CLU 3;
BA_ "GenSigSendType" SG_ 1167 IGN_AutoOff_WarnSta_CLU 4;
BA_ "Description" SG_ 1167 IGN_AutoOff_WarnSta_CLU "This signal is for battery discharge warning (engine not running && IGN/ACC on)

To prevent battery discharge, ICU requests the Cluster to display warning and requests IBU to turn IGN/ACC off.";
BA_ "Version" SG_ 1167 PDC_BatPwrStateClassA "21.06.08";
BA_ "UserSigValidity" SG_ 1167 PDC_BatPwrStateClassA 0;
BA_ "GenSigSendType" SG_ 1167 PDC_BatPwrStateClassA 4;
BA_ "Description" SG_ 1167 PDC_BatPwrStateClassA "Battery Power State ClassA 

Battery Power State ClassC

0x0 : This signal is not used.

The target function is operated based on the main battery SoC value.(Legacy mode)

0x3 : PDC Logic is not ready because of battery Sensor Error or other reason.  Tar";
BA_ "Version" SG_ 1167 PDC_BatPwrStateClassB "21.06.08";
BA_ "UserSigValidity" SG_ 1167 PDC_BatPwrStateClassB 0;
BA_ "GenSigSendType" SG_ 1167 PDC_BatPwrStateClassB 4;
BA_ "Description" SG_ 1167 PDC_BatPwrStateClassB "Battery Power State ClassB

Battery Power State ClassC

0x0 : This signal is not used.

The target function is operated based on the main battery SoC value.(Legacy mode)

0x3 : PDC Logic is not ready because of battery Sensor Error or other reason.  Targ";
BA_ "Version" SG_ 1167 PDC_BatPwrStateClassC "21.06.08";
BA_ "UserSigValidity" SG_ 1167 PDC_BatPwrStateClassC 0;
BA_ "GenSigSendType" SG_ 1167 PDC_BatPwrStateClassC 4;
BA_ "Description" SG_ 1167 PDC_BatPwrStateClassC "Battery Power State ClassC

0x0 : This signal is not used.

The target function is operated based on the main battery SoC value.(Legacy mode)

0x3 : PDC Logic is not ready because of battery Sensor Error or other reason.  Target function-operation is rec";
BA_ "Version" SG_ 1167 PLBMAvailableState "21.06.11";
BA_ "UserSigValidity" SG_ 1167 PLBMAvailableState 0;
BA_ "GenSigSendType" SG_ 1167 PLBMAvailableState 4;
BA_ "Description" SG_ 1167 PLBMAvailableState "Power supply Available status notification at PLBM. If this value is Set, BMS can request Discharge-request to PDC during parking mode";
BA_ "Version" SG_ 1167 IGN_AutoOff_WarnSta "20.03.03";
BA_ "UserSigValidity" SG_ 1167 IGN_AutoOff_WarnSta 3;
BA_ "GenSigSendType" SG_ 1167 IGN_AutoOff_WarnSta 4;
BA_ "Description" SG_ 1167 IGN_AutoOff_WarnSta "This signal is for battery discharge warning (engine not running && IGN/ACC on)

To prevent battery discharge, ICU requests the head unit to display warning and requests IBU to turn IGN/ACC off.";
BA_ "Version" SG_ 223 ALBCU_SmartCtrl_1h "20.10.02";
BA_ "RoutingFactor" SG_ 223 ALBCU_SmartCtrl_1h 0;
BA_ "UserSigValidity" SG_ 223 ALBCU_SmartCtrl_1h 1;
BA_ "GenSigSendType" SG_ 223 ALBCU_SmartCtrl_1h 4;
BA_ "Description" SG_ 223 ALBCU_SmartCtrl_1h "Smart Posture Adjust AVN Display (1hr)";
BA_ "Version" SG_ 223 ALBCU_SmartCtrl_2h "20.10.02";
BA_ "RoutingFactor" SG_ 223 ALBCU_SmartCtrl_2h 0;
BA_ "UserSigValidity" SG_ 223 ALBCU_SmartCtrl_2h 1;
BA_ "GenSigSendType" SG_ 223 ALBCU_SmartCtrl_2h 4;
BA_ "Description" SG_ 223 ALBCU_SmartCtrl_2h "Smart Posture Adjust AVN Display (2hr)";
BA_ "Version" SG_ 223 ALBCU_SmartCtrl_Status "20.10.02";
BA_ "RoutingFactor" SG_ 223 ALBCU_SmartCtrl_Status 0;
BA_ "UserSigValidity" SG_ 223 ALBCU_SmartCtrl_Status 1;
BA_ "GenSigSendType" SG_ 223 ALBCU_SmartCtrl_Status 4;
BA_ "Description" SG_ 223 ALBCU_SmartCtrl_Status "Smart Posture Adjust 2nd Interlocked Move AVN popup request";
BA_ "Version" SG_ 1171 RLPSM_SWVerMajor1 "21.07.00";
BA_ "RoutingFactor" SG_ 1171 RLPSM_SWVerMajor1 0;
BA_ "UserSigValidity" SG_ 1171 RLPSM_SWVerMajor1 0;
BA_ "GenSigSendType" SG_ 1171 RLPSM_SWVerMajor1 4;
BA_ "Description" SG_ 1171 RLPSM_SWVerMajor1 "Indicate the SCM software version as follows:

- The software version is displayed in three digits.

- The Major and Minor digits are separated by '.'

- Signal values are transmitted to ASCII codes.



¡Ø Example

RLPSM_SWVerMajor1 : 0x41 (HEX) -> ASCII";
BA_ "Version" SG_ 1171 RLPSM_SWVerMinor2 "20.04.06";
BA_ "RoutingFactor" SG_ 1171 RLPSM_SWVerMinor2 0;
BA_ "UserSigValidity" SG_ 1171 RLPSM_SWVerMinor2 0;
BA_ "GenSigSendType" SG_ 1171 RLPSM_SWVerMinor2 4;
BA_ "Description" SG_ 1171 RLPSM_SWVerMinor2 "Indicate the APSM software version as follows:

- The software version is displayed in three digits.

- The Major and Minor digits are separated by '.'

- Signal values are transmitted to ASCII codes.



¡Ø Example

RLPSM_SWVerMajor1 : 0x41 (HEX) -> ASCI";
BA_ "Version" SG_ 1171 RLPSM_SWVerMinor1 "20.04.06";
BA_ "RoutingFactor" SG_ 1171 RLPSM_SWVerMinor1 0;
BA_ "UserSigValidity" SG_ 1171 RLPSM_SWVerMinor1 0;
BA_ "GenSigSendType" SG_ 1171 RLPSM_SWVerMinor1 4;
BA_ "Description" SG_ 1171 RLPSM_SWVerMinor1 "Indicate the APSM software version as follows:

- The software version is displayed in three digits.

- The Major and Minor digits are separated by '.'

- Signal values are transmitted to ASCII codes.



¡Ø Example

RLPSM_SWVerMajor1 : 0x41 (HEX) -> ASCI";
BA_ "Version" SG_ 1172 RRPSM_SWVerMajor1 "21.07.00";
BA_ "RoutingFactor" SG_ 1172 RRPSM_SWVerMajor1 0;
BA_ "UserSigValidity" SG_ 1172 RRPSM_SWVerMajor1 0;
BA_ "GenSigSendType" SG_ 1172 RRPSM_SWVerMajor1 4;
BA_ "Description" SG_ 1172 RRPSM_SWVerMajor1 "Indicate the SCM software version as follows:

- The software version is displayed in three digits.

- The Major and Minor digits are separated by '.'

- Signal values are transmitted to ASCII codes.



¡Ø Example

RRPSM_SWVerMajor1 : 0x41 (HEX) -> ASCII";
BA_ "Version" SG_ 1172 RRPSM_SWVerMinor2 "20.04.06";
BA_ "RoutingFactor" SG_ 1172 RRPSM_SWVerMinor2 0;
BA_ "UserSigValidity" SG_ 1172 RRPSM_SWVerMinor2 0;
BA_ "GenSigSendType" SG_ 1172 RRPSM_SWVerMinor2 4;
BA_ "Description" SG_ 1172 RRPSM_SWVerMinor2 "Indicate the APSM software version as follows:

- The software version is displayed in three digits.

- The Major and Minor digits are separated by '.'

- Signal values are transmitted to ASCII codes.



¡Ø Example

RRPSM_SWVerMajor1 : 0x41 (HEX) -> ASCI";
BA_ "Version" SG_ 1172 RRPSM_SWVerMinor1 "20.04.06";
BA_ "RoutingFactor" SG_ 1172 RRPSM_SWVerMinor1 0;
BA_ "UserSigValidity" SG_ 1172 RRPSM_SWVerMinor1 0;
BA_ "GenSigSendType" SG_ 1172 RRPSM_SWVerMinor1 4;
BA_ "Description" SG_ 1172 RRPSM_SWVerMinor1 "Indicate the APSM software version as follows:

- The software version is displayed in three digits.

- The Major and Minor digits are separated by '.'

- Signal values are transmitted to ASCII codes.



¡Ø Example

RRPSM_SWVerMajor1 : 0x41 (HEX) -> ASCI";
BA_ "Version" SG_ 1174 Drv_SHVU_SeatOptSta "19.01.04";
BA_ "NetworkRequestHoldingTime" SG_ 1174 Drv_SHVU_SeatOptSta 5000;
BA_ "NetworkRequest" SG_ 1174 Drv_SHVU_SeatOptSta 0;
BA_ "UserSigValidity" SG_ 1174 Drv_SHVU_SeatOptSta 3;
BA_ "GenSigSendType" SG_ 1174 Drv_SHVU_SeatOptSta 4;
BA_ "Description" SG_ 1174 Drv_SHVU_SeatOptSta "¿îÀü¼® ½ÃÆ®¿¡ Àû¿ëµÈ È÷ÅÍ/ÅëÇ³ ¿É¼Ç »ç¾ç";
BA_ "Version" SG_ 1174 Drv_SHVU_HtSwHiIndSta "21.07.06";
BA_ "NetworkRequestHoldingTime" SG_ 1174 Drv_SHVU_HtSwHiIndSta 5000;
BA_ "NetworkRequest" SG_ 1174 Drv_SHVU_HtSwHiIndSta 0;
BA_ "UserSigValidity" SG_ 1174 Drv_SHVU_HtSwHiIndSta 3;
BA_ "GenSigSendType" SG_ 1174 Drv_SHVU_HtSwHiIndSta 4;
BA_ "Description" SG_ 1174 Drv_SHVU_HtSwHiIndSta "¿îÀü¼® ½ÃÆ® ¿­¼± ½ºÀ§Ä¡ High Indicator Á¤º¸";
BA_ "Version" SG_ 1174 Drv_SHVU_HtSwMidIndSta "21.07.06";
BA_ "NetworkRequestHoldingTime" SG_ 1174 Drv_SHVU_HtSwMidIndSta 5000;
BA_ "NetworkRequest" SG_ 1174 Drv_SHVU_HtSwMidIndSta 0;
BA_ "UserSigValidity" SG_ 1174 Drv_SHVU_HtSwMidIndSta 3;
BA_ "GenSigSendType" SG_ 1174 Drv_SHVU_HtSwMidIndSta 4;
BA_ "Description" SG_ 1174 Drv_SHVU_HtSwMidIndSta "¿îÀü¼® ½ÃÆ® ¿­¼± ½ºÀ§Ä¡ Mid Indicator Á¤º¸";
BA_ "Version" SG_ 1174 Drv_SHVU_HtSwLowIndSta "21.07.06";
BA_ "NetworkRequestHoldingTime" SG_ 1174 Drv_SHVU_HtSwLowIndSta 5000;
BA_ "NetworkRequest" SG_ 1174 Drv_SHVU_HtSwLowIndSta 0;
BA_ "UserSigValidity" SG_ 1174 Drv_SHVU_HtSwLowIndSta 3;
BA_ "GenSigSendType" SG_ 1174 Drv_SHVU_HtSwLowIndSta 4;
BA_ "Description" SG_ 1174 Drv_SHVU_HtSwLowIndSta "¿îÀü¼® ½ÃÆ® ¿­¼± ½ºÀ§Ä¡ Low Indicator Á¤º¸";
BA_ "Version" SG_ 1174 Drv_SHVU_VntSwHiIndSta "21.07.06";
BA_ "NetworkRequestHoldingTime" SG_ 1174 Drv_SHVU_VntSwHiIndSta 5000;
BA_ "NetworkRequest" SG_ 1174 Drv_SHVU_VntSwHiIndSta 0;
BA_ "UserSigValidity" SG_ 1174 Drv_SHVU_VntSwHiIndSta 3;
BA_ "GenSigSendType" SG_ 1174 Drv_SHVU_VntSwHiIndSta 4;
BA_ "Description" SG_ 1174 Drv_SHVU_VntSwHiIndSta "¿îÀü¼® ½ÃÆ® ÅëÇ³ ½ºÀ§Ä¡ High Indicator Á¤º¸";
BA_ "Version" SG_ 1174 Drv_SHVU_VntSwMidIndSta "21.07.06";
BA_ "NetworkRequestHoldingTime" SG_ 1174 Drv_SHVU_VntSwMidIndSta 5000;
BA_ "NetworkRequest" SG_ 1174 Drv_SHVU_VntSwMidIndSta 0;
BA_ "UserSigValidity" SG_ 1174 Drv_SHVU_VntSwMidIndSta 3;
BA_ "GenSigSendType" SG_ 1174 Drv_SHVU_VntSwMidIndSta 4;
BA_ "Description" SG_ 1174 Drv_SHVU_VntSwMidIndSta "¿îÀü¼® ½ÃÆ® ÅëÇ³ ½ºÀ§Ä¡ Mid Indicator Á¤º¸";
BA_ "Version" SG_ 1174 Drv_SHVU_VntSwLowIndSta "21.07.06";
BA_ "NetworkRequestHoldingTime" SG_ 1174 Drv_SHVU_VntSwLowIndSta 5000;
BA_ "NetworkRequest" SG_ 1174 Drv_SHVU_VntSwLowIndSta 0;
BA_ "UserSigValidity" SG_ 1174 Drv_SHVU_VntSwLowIndSta 3;
BA_ "GenSigSendType" SG_ 1174 Drv_SHVU_VntSwLowIndSta 4;
BA_ "Description" SG_ 1174 Drv_SHVU_VntSwLowIndSta "¿îÀü¼® ½ÃÆ® ÅëÇ³ ½ºÀ§Ä¡ Low Indicator Á¤º¸";
BA_ "Version" SG_ 1174 Drv_SHVU_HtBlcUSMSta "19.01.04";
BA_ "UserSigValidity" SG_ 1174 Drv_SHVU_HtBlcUSMSta 0;
BA_ "GenSigSendType" SG_ 1174 Drv_SHVU_HtBlcUSMSta 4;
BA_ "Description" SG_ 1174 Drv_SHVU_HtBlcUSMSta "Hetaer Balance Driver USM R vaule";
BA_ "Version" SG_ 1174 Drv_SHVU_SeatHtOperSta "21.09.07";
BA_ "NetworkRequestHoldingTime" SG_ 1174 Drv_SHVU_SeatHtOperSta 5000;
BA_ "NetworkRequest" SG_ 1174 Drv_SHVU_SeatHtOperSta 0;
BA_ "UserSigValidity" SG_ 1174 Drv_SHVU_SeatHtOperSta 3;
BA_ "GenSigSendType" SG_ 1174 Drv_SHVU_SeatHtOperSta 4;
BA_ "Description" SG_ 1174 Drv_SHVU_SeatHtOperSta "¿îÀü¼® ½ÃÆ® ÇöÀç ÀÛµ¿ ÁßÀÎ È÷ÅÍ/ÅëÇ³ ´Ü¼ö »óÅÂ";
BA_ "Version" SG_ 1174 Drv_SHVU_HtSwHiIndSta_RHD "21.07.06";
BA_ "NetworkRequestHoldingTime" SG_ 1174 Drv_SHVU_HtSwHiIndSta_RHD 5000;
BA_ "NetworkRequest" SG_ 1174 Drv_SHVU_HtSwHiIndSta_RHD 0;
BA_ "UserSigValidity" SG_ 1174 Drv_SHVU_HtSwHiIndSta_RHD 3;
BA_ "GenSigSendType" SG_ 1174 Drv_SHVU_HtSwHiIndSta_RHD 4;
BA_ "Description" SG_ 1174 Drv_SHVU_HtSwHiIndSta_RHD "¿îÀü¼® ½ÃÆ® ¿­¼± ½ºÀ§Ä¡ High Indicator Á¤º¸(RHD)";
BA_ "Version" SG_ 1174 Drv_SHVU_HtSwMidIndSta_RHD "21.07.06";
BA_ "NetworkRequestHoldingTime" SG_ 1174 Drv_SHVU_HtSwMidIndSta_RHD 5000;
BA_ "NetworkRequest" SG_ 1174 Drv_SHVU_HtSwMidIndSta_RHD 0;
BA_ "UserSigValidity" SG_ 1174 Drv_SHVU_HtSwMidIndSta_RHD 3;
BA_ "GenSigSendType" SG_ 1174 Drv_SHVU_HtSwMidIndSta_RHD 4;
BA_ "Description" SG_ 1174 Drv_SHVU_HtSwMidIndSta_RHD "¿îÀü¼® ½ÃÆ® ¿­¼± ½ºÀ§Ä¡ Mid Indicator Á¤º¸(RHD)";
BA_ "Version" SG_ 1174 Drv_SHVU_HtSwLowIndSta_RHD "21.07.06";
BA_ "NetworkRequestHoldingTime" SG_ 1174 Drv_SHVU_HtSwLowIndSta_RHD 5000;
BA_ "NetworkRequest" SG_ 1174 Drv_SHVU_HtSwLowIndSta_RHD 0;
BA_ "UserSigValidity" SG_ 1174 Drv_SHVU_HtSwLowIndSta_RHD 3;
BA_ "GenSigSendType" SG_ 1174 Drv_SHVU_HtSwLowIndSta_RHD 4;
BA_ "Description" SG_ 1174 Drv_SHVU_HtSwLowIndSta_RHD "¿îÀü¼® ½ÃÆ® ¿­¼± ½ºÀ§Ä¡ Low Indicator Á¤º¸(RHD)";
BA_ "Version" SG_ 1174 Drv_SHVU_VntSwHiIndSta_RHD "21.07.06";
BA_ "NetworkRequestHoldingTime" SG_ 1174 Drv_SHVU_VntSwHiIndSta_RHD 5000;
BA_ "NetworkRequest" SG_ 1174 Drv_SHVU_VntSwHiIndSta_RHD 0;
BA_ "UserSigValidity" SG_ 1174 Drv_SHVU_VntSwHiIndSta_RHD 3;
BA_ "GenSigSendType" SG_ 1174 Drv_SHVU_VntSwHiIndSta_RHD 4;
BA_ "Description" SG_ 1174 Drv_SHVU_VntSwHiIndSta_RHD "¿îÀü¼® ½ÃÆ® ÅëÇ³ ½ºÀ§Ä¡ High Indicator Á¤º¸(RHD)";
BA_ "Version" SG_ 1174 Drv_SHVU_VntSwMidIndSta_RHD "21.07.06";
BA_ "NetworkRequestHoldingTime" SG_ 1174 Drv_SHVU_VntSwMidIndSta_RHD 5000;
BA_ "NetworkRequest" SG_ 1174 Drv_SHVU_VntSwMidIndSta_RHD 0;
BA_ "UserSigValidity" SG_ 1174 Drv_SHVU_VntSwMidIndSta_RHD 3;
BA_ "GenSigSendType" SG_ 1174 Drv_SHVU_VntSwMidIndSta_RHD 4;
BA_ "Description" SG_ 1174 Drv_SHVU_VntSwMidIndSta_RHD "¿îÀü¼® ½ÃÆ® ÅëÇ³ ½ºÀ§Ä¡ Mid Indicator Á¤º¸(RHD)";
BA_ "Version" SG_ 1174 Drv_SHVU_VntSwLowIndSta_RHD "21.07.06";
BA_ "NetworkRequestHoldingTime" SG_ 1174 Drv_SHVU_VntSwLowIndSta_RHD 5000;
BA_ "NetworkRequest" SG_ 1174 Drv_SHVU_VntSwLowIndSta_RHD 0;
BA_ "UserSigValidity" SG_ 1174 Drv_SHVU_VntSwLowIndSta_RHD 3;
BA_ "GenSigSendType" SG_ 1174 Drv_SHVU_VntSwLowIndSta_RHD 4;
BA_ "Description" SG_ 1174 Drv_SHVU_VntSwLowIndSta_RHD "¿îÀü¼® ½ÃÆ® ÅëÇ³ ½ºÀ§Ä¡ Low Indicator Á¤º¸(RHD)";
BA_ "Version" SG_ 1174 Drv_SHVU_HtBlcUSMSta_RHD "19.01.04";
BA_ "UserSigValidity" SG_ 1174 Drv_SHVU_HtBlcUSMSta_RHD 0;
BA_ "GenSigSendType" SG_ 1174 Drv_SHVU_HtBlcUSMSta_RHD 4;
BA_ "Description" SG_ 1174 Drv_SHVU_HtBlcUSMSta_RHD "Hetaer Balance Driver USM R vaule(RHD)";
BA_ "Version" SG_ 1179 Drv_SHVU_SeatEcoSta "21.07.06";
BA_ "NetworkRequestHoldingTime" SG_ 1179 Drv_SHVU_SeatEcoSta 5000;
BA_ "NetworkRequest" SG_ 1179 Drv_SHVU_SeatEcoSta 0;
BA_ "UserSigValidity" SG_ 1179 Drv_SHVU_SeatEcoSta 3;
BA_ "GenSigSendType" SG_ 1179 Drv_SHVU_SeatEcoSta 4;
BA_ "Description" SG_ 1179 Drv_SHVU_SeatEcoSta "Drv ½ÃÆ® ¿¡ÄÚÇÃ·¯½º ¸ðµå ÁøÀÔ Á¤º¸";
BA_ "Version" SG_ 1179 SHVU_Drv_Beep1Sound "21.07.06";
BA_ "UserSigValidity" SG_ 1179 SHVU_Drv_Beep1Sound 3;
BA_ "GenSigSendType" SG_ 1179 SHVU_Drv_Beep1Sound 4;
BA_ "Description" SG_ 1179 SHVU_Drv_Beep1Sound "Play touch beep sound one time

Beep sound on/off

Default : Off

Goes On when play beep sound";
BA_ "Version" SG_ 1179 SHVU_CtrlScreenDis "21.07.06";
BA_ "UserSigValidity" SG_ 1179 SHVU_CtrlScreenDis 3;
BA_ "GenSigSendType" SG_ 1179 SHVU_CtrlScreenDis 4;
BA_ "Description" SG_ 1179 SHVU_CtrlScreenDis "Change AVN Screen to control Seat Heater or Ventilation

Screen Display On : Pop up the menu of controlling Seat Heater & Ventilation

Default : Off";
BA_ "Version" SG_ 1180 SHVU_Ast_Beep1Sound "20.01.02";
BA_ "UserSigValidity" SG_ 1180 SHVU_Ast_Beep1Sound 3;
BA_ "GenSigSendType" SG_ 1180 SHVU_Ast_Beep1Sound 4;
BA_ "Description" SG_ 1180 SHVU_Ast_Beep1Sound "Play touch beep sound one time

Beep sound on/off

Default : Off

Goes On when play beep sound";
BA_ "Version" SG_ 1180 Ast_SHVU_SeatEcoSta "20.01.01";
BA_ "NetworkRequestHoldingTime" SG_ 1180 Ast_SHVU_SeatEcoSta 5000;
BA_ "NetworkRequest" SG_ 1180 Ast_SHVU_SeatEcoSta 0;
BA_ "UserSigValidity" SG_ 1180 Ast_SHVU_SeatEcoSta 3;
BA_ "GenSigSendType" SG_ 1180 Ast_SHVU_SeatEcoSta 4;
BA_ "Description" SG_ 1180 Ast_SHVU_SeatEcoSta "Ast ½ÃÆ® ¿¡ÄÚÇÃ·¯½º ¸ðµå ÁøÀÔ Á¤º¸";
BA_ "Version" SG_ 208 RR_SHVU_DTCdisplay "19.11.06";
BA_ "NetworkRequestHoldingTime" SG_ 208 RR_SHVU_DTCdisplay 5000;
BA_ "NetworkRequest" SG_ 208 RR_SHVU_DTCdisplay 0;
BA_ "UserSigValidity" SG_ 208 RR_SHVU_DTCdisplay 3;
BA_ "GenSigSendType" SG_ 208 RR_SHVU_DTCdisplay 4;
BA_ "Description" SG_ 208 RR_SHVU_DTCdisplay "0x00: DTC is not exist(Fail is not exist)/0x01:IGN2 Fuse Open Detection/0x02:Switch Input Detection at Same Time/0x03:NTC/Heating wire Open Detection/0x04:NTC+/NTC- Terminal Short Detection/0x05:NTC+/Heater+ Terminal Short Detection/0x06:NTC+/Heater-, He";
BA_ "Version" SG_ 208 RR_SHVU_DiagMode "19.11.06";
BA_ "NetworkRequestHoldingTime" SG_ 208 RR_SHVU_DiagMode 5000;
BA_ "NetworkRequest" SG_ 208 RR_SHVU_DiagMode 0;
BA_ "UserSigValidity" SG_ 208 RR_SHVU_DiagMode 3;
BA_ "GenSigSendType" SG_ 208 RR_SHVU_DiagMode 4;
BA_ "Description" SG_ 208 RR_SHVU_DiagMode "0x0:Default/0x1:DTC Mode/0x2:Normal Mode/0x3:Invalid";
BA_ "Version" SG_ 1181 RL_SHVU_SeatEcoSta "21.07.06";
BA_ "NetworkRequestHoldingTime" SG_ 1181 RL_SHVU_SeatEcoSta 5000;
BA_ "NetworkRequest" SG_ 1181 RL_SHVU_SeatEcoSta 0;
BA_ "UserSigValidity" SG_ 1181 RL_SHVU_SeatEcoSta 3;
BA_ "GenSigSendType" SG_ 1181 RL_SHVU_SeatEcoSta 4;
BA_ "Description" SG_ 1181 RL_SHVU_SeatEcoSta "ÈÄ¼® LH ½ÃÆ® ¿¡ÄÚÇÃ·¯½º ¸ðµå ÁøÀÔ Á¤º¸";
BA_ "Version" SG_ 1182 RR_SHVU_SeatEcoSta "21.07.06";
BA_ "NetworkRequestHoldingTime" SG_ 1182 RR_SHVU_SeatEcoSta 5000;
BA_ "NetworkRequest" SG_ 1182 RR_SHVU_SeatEcoSta 0;
BA_ "UserSigValidity" SG_ 1182 RR_SHVU_SeatEcoSta 3;
BA_ "GenSigSendType" SG_ 1182 RR_SHVU_SeatEcoSta 4;
BA_ "Description" SG_ 1182 RR_SHVU_SeatEcoSta "ÈÄ¼® RH ½ÃÆ® ¿¡ÄÚÇÃ·¯½º ¸ðµå ÁøÀÔ Á¤º¸";
BA_ "Version" SG_ 1186 C_RemoteWdwCMDHU "18.10.05";
BA_ "UserSigValidity" SG_ 1186 C_RemoteWdwCMDHU 0;
BA_ "GenSigStartValue" SG_ 1186 C_RemoteWdwCMDHU 3;
BA_ "GenSigSendType" SG_ 1186 C_RemoteWdwCMDHU 4;
BA_ "Description" SG_ 1186 C_RemoteWdwCMDHU "18.09.06_";
BA_ "Version" SG_ 1186 HU_CDMOpenCmd "20.01.02";
BA_ "UserSigValidity" SG_ 1186 HU_CDMOpenCmd 7;
BA_ "GenSigSendType" SG_ 1186 HU_CDMOpenCmd 4;
BA_ "Description" SG_ 1186 HU_CDMOpenCmd "Command for CDM open/close";
BA_ "Version" SG_ 1186 C_PreCrankReq "18.09.04";
BA_ "NetworkRequest" SG_ 1186 C_PreCrankReq 0;
BA_ "UserSigValidity" SG_ 1186 C_PreCrankReq 0;
BA_ "GenSigSendType" SG_ 1186 C_PreCrankReq 4;
BA_ "Description" SG_ 1186 C_PreCrankReq "18.08.09_Remote Control message";
BA_ "Version" SG_ 1186 C_TeleAstSeatOpCmdIBOX "18.09.04";
BA_ "UserSigValidity" SG_ 1186 C_TeleAstSeatOpCmdIBOX 3;
BA_ "GenSigSendType" SG_ 1186 C_TeleAstSeatOpCmdIBOX 4;
BA_ "Description" SG_ 1186 C_TeleAstSeatOpCmdIBOX "18.08.09_Remote Control message";
BA_ "Version" SG_ 1186 C_TeleDrvSeatOpCmdIBOX "18.09.04";
BA_ "UserSigValidity" SG_ 1186 C_TeleDrvSeatOpCmdIBOX 3;
BA_ "GenSigSendType" SG_ 1186 C_TeleDrvSeatOpCmdIBOX 4;
BA_ "Description" SG_ 1186 C_TeleDrvSeatOpCmdIBOX "18.08.09_Remote Control message";
BA_ "Version" SG_ 1186 C_TeleRRSeatOpCmdIBOX "18.09.04";
BA_ "UserSigValidity" SG_ 1186 C_TeleRRSeatOpCmdIBOX 3;
BA_ "GenSigSendType" SG_ 1186 C_TeleRRSeatOpCmdIBOX 4;
BA_ "Description" SG_ 1186 C_TeleRRSeatOpCmdIBOX "18.08.09_Remote Control message";
BA_ "Version" SG_ 1186 C_TeleRLSeatOpCmdIBOX "18.09.04";
BA_ "UserSigValidity" SG_ 1186 C_TeleRLSeatOpCmdIBOX 3;
BA_ "GenSigSendType" SG_ 1186 C_TeleRLSeatOpCmdIBOX 4;
BA_ "Description" SG_ 1186 C_TeleRLSeatOpCmdIBOX "18.08.09_Remote Control message";
BA_ "Version" SG_ 1185 C_AstWindowCmdAVN "19.11.05";
BA_ "UserSigValidity" SG_ 1185 C_AstWindowCmdAVN 0;
BA_ "GenSigStartValue" SG_ 1185 C_AstWindowCmdAVN 15;
BA_ "GenSigSendType" SG_ 1185 C_AstWindowCmdAVN 4;
BA_ "Version" SG_ 1185 C_RrDefoggerCmdAVN "18.09.02";
BA_ "UserSigValidity" SG_ 1185 C_RrDefoggerCmdAVN 3;
BA_ "GenSigStartValue" SG_ 1185 C_RrDefoggerCmdAVN 3;
BA_ "GenSigSendType" SG_ 1185 C_RrDefoggerCmdAVN 4;
BA_ "Description" SG_ 1185 C_RrDefoggerCmdAVN "18.08.09_";
BA_ "Version" SG_ 1185 C_RrBlindCmdAVN "22.02.04";
BA_ "UserSigValidity" SG_ 1185 C_RrBlindCmdAVN 3;
BA_ "GenSigStartValue" SG_ 1185 C_RrBlindCmdAVN 3;
BA_ "GenSigSendType" SG_ 1185 C_RrBlindCmdAVN 4;
BA_ "Description" SG_ 1185 C_RrBlindCmdAVN "Rear sunroof control signal(blind)";
BA_ "Version" SG_ 1185 C_RrGlassCmdAVN "22.02.04";
BA_ "UserSigValidity" SG_ 1185 C_RrGlassCmdAVN 3;
BA_ "GenSigStartValue" SG_ 1185 C_RrGlassCmdAVN 3;
BA_ "GenSigSendType" SG_ 1185 C_RrGlassCmdAVN 4;
BA_ "Description" SG_ 1185 C_RrGlassCmdAVN "Rear sunroof control signal(glass)";
BA_ "Version" SG_ 1185 C_RRWindowCmdAVN "19.11.05";
BA_ "UserSigValidity" SG_ 1185 C_RRWindowCmdAVN 0;
BA_ "GenSigStartValue" SG_ 1185 C_RRWindowCmdAVN 15;
BA_ "GenSigSendType" SG_ 1185 C_RRWindowCmdAVN 4;
BA_ "Version" SG_ 1185 C_RLWindowCmdAVN "19.11.05";
BA_ "UserSigValidity" SG_ 1185 C_RLWindowCmdAVN 0;
BA_ "GenSigStartValue" SG_ 1185 C_RLWindowCmdAVN 15;
BA_ "GenSigSendType" SG_ 1185 C_RLWindowCmdAVN 4;
BA_ "Version" SG_ 1185 C_BlindCmdAVN "18.09.02";
BA_ "UserSigValidity" SG_ 1185 C_BlindCmdAVN 1;
BA_ "GenSigStartValue" SG_ 1185 C_BlindCmdAVN 7;
BA_ "GenSigSendType" SG_ 1185 C_BlindCmdAVN 4;
BA_ "Description" SG_ 1185 C_BlindCmdAVN "18.08.09_";
BA_ "Version" SG_ 1185 C_GlassCmdAVN "18.09.02";
BA_ "UserSigValidity" SG_ 1185 C_GlassCmdAVN 1;
BA_ "GenSigStartValue" SG_ 1185 C_GlassCmdAVN 7;
BA_ "GenSigSendType" SG_ 1185 C_GlassCmdAVN 4;
BA_ "Description" SG_ 1185 C_GlassCmdAVN "18.08.09_";
BA_ "Version" SG_ 1185 C_DrvWindowCmdAVN "19.11.05";
BA_ "UserSigValidity" SG_ 1185 C_DrvWindowCmdAVN 0;
BA_ "GenSigStartValue" SG_ 1185 C_DrvWindowCmdAVN 15;
BA_ "GenSigSendType" SG_ 1185 C_DrvWindowCmdAVN 4;
BA_ "Version" SG_ 1185 C_PTGCNTLCmdAVN "18.09.02";
BA_ "UserSigValidity" SG_ 1185 C_PTGCNTLCmdAVN 3;
BA_ "GenSigStartValue" SG_ 1185 C_PTGCNTLCmdAVN 3;
BA_ "GenSigSendType" SG_ 1185 C_PTGCNTLCmdAVN 4;
BA_ "Description" SG_ 1185 C_PTGCNTLCmdAVN "18.08.09_";
BA_ "Version" SG_ 1189 C_RLTiltUpSw_HU "18.10.03";
BA_ "UserSigValidity" SG_ 1189 C_RLTiltUpSw_HU 0;
BA_ "GenSigSendType" SG_ 1189 C_RLTiltUpSw_HU 4;
BA_ "Description" SG_ 1189 C_RLTiltUpSw_HU "18.10.03_2nd Left side seat Moving control : Tilt Up";
BA_ "Version" SG_ 1189 C_RRTiltDownSw_HU "18.10.03";
BA_ "UserSigValidity" SG_ 1189 C_RRTiltDownSw_HU 0;
BA_ "GenSigSendType" SG_ 1189 C_RRTiltDownSw_HU 4;
BA_ "Description" SG_ 1189 C_RRTiltDownSw_HU "18.10.03_2nd Right side seat Moving control : Tilt Down";
BA_ "Version" SG_ 1189 C_RRTiltUpSw_HU "18.10.03";
BA_ "UserSigValidity" SG_ 1189 C_RRTiltUpSw_HU 0;
BA_ "GenSigSendType" SG_ 1189 C_RRTiltUpSw_HU 4;
BA_ "Description" SG_ 1189 C_RRTiltUpSw_HU "18.10.03_2nd Right side seat Moving control : Tilt Up";
BA_ "Version" SG_ 1189 C_RLRclBwdSw_HU "18.10.03";
BA_ "UserSigValidity" SG_ 1189 C_RLRclBwdSw_HU 0;
BA_ "GenSigSendType" SG_ 1189 C_RLRclBwdSw_HU 4;
BA_ "Description" SG_ 1189 C_RLRclBwdSw_HU "18.10.03_2nd Left side seat Moving control :Recline Backward";
BA_ "Version" SG_ 1189 C_RLRclFwdSw_HU "18.10.03";
BA_ "UserSigValidity" SG_ 1189 C_RLRclFwdSw_HU 0;
BA_ "GenSigSendType" SG_ 1189 C_RLRclFwdSw_HU 4;
BA_ "Description" SG_ 1189 C_RLRclFwdSw_HU "18.10.03_2nd Left side seat Moving control : Recline Forward";
BA_ "Version" SG_ 1189 C_RLFldSw_HU "18.10.03";
BA_ "UserSigValidity" SG_ 1189 C_RLFldSw_HU 0;
BA_ "GenSigSendType" SG_ 1189 C_RLFldSw_HU 4;
BA_ "Description" SG_ 1189 C_RLFldSw_HU "18.10.03_2nd Left side seat folding control : Folding";
BA_ "Version" SG_ 1189 C_RRRclBwdSw_HU "18.10.03";
BA_ "UserSigValidity" SG_ 1189 C_RRRclBwdSw_HU 0;
BA_ "GenSigSendType" SG_ 1189 C_RRRclBwdSw_HU 4;
BA_ "Description" SG_ 1189 C_RRRclBwdSw_HU "18.10.03_2nd Right side seat Moving control :Recline Backward";
BA_ "Version" SG_ 1189 C_RRRclFwdSw_HU "18.10.03";
BA_ "UserSigValidity" SG_ 1189 C_RRRclFwdSw_HU 0;
BA_ "GenSigSendType" SG_ 1189 C_RRRclFwdSw_HU 4;
BA_ "Description" SG_ 1189 C_RRRclFwdSw_HU "18.10.03_2nd Right side seat Moving control :Recline Forward";
BA_ "Version" SG_ 1189 C_TLHrestFldSw_HU "18.10.03";
BA_ "UserSigValidity" SG_ 1189 C_TLHrestFldSw_HU 0;
BA_ "GenSigSendType" SG_ 1189 C_TLHrestFldSw_HU 4;
BA_ "Description" SG_ 1189 C_TLHrestFldSw_HU "18.10.03_3rdLeft side seat Headrest folding control : Folding";
BA_ "Version" SG_ 1189 C_TRHrestFldSw_HU "18.10.03";
BA_ "UserSigValidity" SG_ 1189 C_TRHrestFldSw_HU 0;
BA_ "GenSigSendType" SG_ 1189 C_TRHrestFldSw_HU 4;
BA_ "Description" SG_ 1189 C_TRHrestFldSw_HU "18.10.03_3rd Right side seat Headrest folding control : Folding";
BA_ "Version" SG_ 1189 C_RLRlxSW_HU "18.10.03";
BA_ "UserSigValidity" SG_ 1189 C_RLRlxSW_HU 0;
BA_ "GenSigSendType" SG_ 1189 C_RLRlxSW_HU 4;
BA_ "Description" SG_ 1189 C_RLRlxSW_HU "18.10.03_2nd Left side seat Moving control : Relax mode";
BA_ "Version" SG_ 1189 C_RRRlxSW_HU "18.10.03";
BA_ "UserSigValidity" SG_ 1189 C_RRRlxSW_HU 0;
BA_ "GenSigSendType" SG_ 1189 C_RRRlxSW_HU 4;
BA_ "Description" SG_ 1189 C_RRRlxSW_HU "18.10.03_2nd Right side seat Moving control : Relax mode";
BA_ "Version" SG_ 1189 C_TLFldSw_HU "18.10.03";
BA_ "UserSigValidity" SG_ 1189 C_TLFldSw_HU 0;
BA_ "GenSigSendType" SG_ 1189 C_TLFldSw_HU 4;
BA_ "Description" SG_ 1189 C_TLFldSw_HU "18.10.03_3rd Left side seat folding control : Folding";
BA_ "Version" SG_ 1189 C_TRFldSw_HU "18.10.03";
BA_ "UserSigValidity" SG_ 1189 C_TRFldSw_HU 0;
BA_ "GenSigSendType" SG_ 1189 C_TRFldSw_HU 4;
BA_ "Description" SG_ 1189 C_TRFldSw_HU "18.10.03_3rd Right side seat folding control : Folding";
BA_ "Version" SG_ 1189 C_RRFldSw_HU "18.10.03";
BA_ "UserSigValidity" SG_ 1189 C_RRFldSw_HU 0;
BA_ "GenSigSendType" SG_ 1189 C_RRFldSw_HU 4;
BA_ "Description" SG_ 1189 C_RRFldSw_HU "18.10.03_2nd Right side seat folding control : Folding";
BA_ "Version" SG_ 1189 C_RLTiltDownSw_HU "18.10.03";
BA_ "UserSigValidity" SG_ 1189 C_RLTiltDownSw_HU 0;
BA_ "GenSigSendType" SG_ 1189 C_RLTiltDownSw_HU 4;
BA_ "Description" SG_ 1189 C_RLTiltDownSw_HU "18.10.03_2ndLeft side seat Moving control : Tilt Down";
BA_ "Version" SG_ 1195 CF_AVN_CluWelcomeSnd "18.04.02";
BA_ "UserSigValidity" SG_ 1195 CF_AVN_CluWelcomeSnd 3;
BA_ "GenSigSendType" SG_ 1195 CF_AVN_CluWelcomeSnd 4;
BA_ "Description" SG_ 1195 CF_AVN_CluWelcomeSnd "16.06.04_";
BA_ "Version" SG_ 1195 CF_AVN_CluTransmissionDisp "18.04.02";
BA_ "UserSigValidity" SG_ 1195 CF_AVN_CluTransmissionDisp 3;
BA_ "GenSigSendType" SG_ 1195 CF_AVN_CluTransmissionDisp 4;
BA_ "Description" SG_ 1195 CF_AVN_CluTransmissionDisp "16.06.04_";
BA_ "Version" SG_ 1195 CF_AVN_CluWiperLight "18.04.02";
BA_ "UserSigValidity" SG_ 1195 CF_AVN_CluWiperLight 3;
BA_ "GenSigSendType" SG_ 1195 CF_AVN_CluWiperLight 4;
BA_ "Description" SG_ 1195 CF_AVN_CluWiperLight "16.06.04_";
BA_ "Version" SG_ 1195 CF_AVN_CluRoadInfoGuide "18.04.02";
BA_ "UserSigValidity" SG_ 1195 CF_AVN_CluRoadInfoGuide 3;
BA_ "GenSigSendType" SG_ 1195 CF_AVN_CluRoadInfoGuide 4;
BA_ "Description" SG_ 1195 CF_AVN_CluRoadInfoGuide "16.06.04_";
BA_ "Version" SG_ 1195 CF_AVN_CluUserSettingPeriod "19.01.10";
BA_ "UserSigValidity" SG_ 1195 CF_AVN_CluUserSettingPeriod 3;
BA_ "GenSigStartValue" SG_ 1195 CF_AVN_CluUserSettingPeriod 127;
BA_ "GenSigSendType" SG_ 1195 CF_AVN_CluUserSettingPeriod 4;
BA_ "Description" SG_ 1195 CF_AVN_CluUserSettingPeriod "16.06.04_";
BA_ "Version" SG_ 1195 CF_AVN_CluFuelEconUnit_mi "18.09.04";
BA_ "UserSigValidity" SG_ 1195 CF_AVN_CluFuelEconUnit_mi 3;
BA_ "GenSigSendType" SG_ 1195 CF_AVN_CluFuelEconUnit_mi 4;
BA_ "Description" SG_ 1195 CF_AVN_CluFuelEconUnit_mi "18.08.08_";
BA_ "Version" SG_ 1195 CF_AVN_CluFuelEconUnit_km "20.08.02";
BA_ "UserSigValidity" SG_ 1195 CF_AVN_CluFuelEconUnit_km 3;
BA_ "GenSigSendType" SG_ 1195 CF_AVN_CluFuelEconUnit_km 4;
BA_ "Version" SG_ 1195 CF_AVN_CluUserSettingDistance "19.01.10";
BA_ "UserSigValidity" SG_ 1195 CF_AVN_CluUserSettingDistance 3;
BA_ "GenSigStartValue" SG_ 1195 CF_AVN_CluUserSettingDistance 131071;
BA_ "GenSigSendType" SG_ 1195 CF_AVN_CluUserSettingDistance 4;
BA_ "Description" SG_ 1195 CF_AVN_CluUserSettingDistance "16.06.04_";
BA_ "Version" SG_ 1195 CF_AVN_CluRheostatLvl "18.06.04";
BA_ "UserSigValidity" SG_ 1195 CF_AVN_CluRheostatLvl 3;
BA_ "GenSigStartValue" SG_ 1195 CF_AVN_CluRheostatLvl 31;
BA_ "GenSigSendType" SG_ 1195 CF_AVN_CluRheostatLvl 4;
BA_ "Description" SG_ 1195 CF_AVN_CluRheostatLvl "18.06.00_";
BA_ "Version" SG_ 1195 CF_AVN_EVReset "18.09.04";
BA_ "UserSigValidity" SG_ 1195 CF_AVN_EVReset 7;
BA_ "GenSigSendType" SG_ 1195 CF_AVN_EVReset 4;
BA_ "Description" SG_ 1195 CF_AVN_EVReset "18.08.08_Request to reset EV Service (0x1 : EV USM Reset)";
BA_ "Version" SG_ 1195 CF_AVN_UnitReset "18.09.04";
BA_ "UserSigValidity" SG_ 1195 CF_AVN_UnitReset 3;
BA_ "GenSigSendType" SG_ 1195 CF_AVN_UnitReset 4;
BA_ "Description" SG_ 1195 CF_AVN_UnitReset "18.08.08_";
BA_ "Version" SG_ 1195 CF_AVN_CluServiceReminderReset "18.04.02";
BA_ "UserSigValidity" SG_ 1195 CF_AVN_CluServiceReminderReset 3;
BA_ "GenSigSendType" SG_ 1195 CF_AVN_CluServiceReminderReset 4;
BA_ "Description" SG_ 1195 CF_AVN_CluServiceReminderReset "16.11.03_";
BA_ "Version" SG_ 1195 CF_AVN_CluUSMReset "21.01.08";
BA_ "UserSigValidity" SG_ 1195 CF_AVN_CluUSMReset 3;
BA_ "GenSigSendType" SG_ 1195 CF_AVN_CluUSMReset 4;
BA_ "Version" SG_ 1195 CF_AVN_CluServiceReminderSet "18.04.02";
BA_ "UserSigValidity" SG_ 1195 CF_AVN_CluServiceReminderSet 3;
BA_ "GenSigSendType" SG_ 1195 CF_AVN_CluServiceReminderSet 4;
BA_ "Description" SG_ 1195 CF_AVN_CluServiceReminderSet "16.06.04_";
BA_ "Version" SG_ 1193 C_PTGMNValueSet "18.09.04";
BA_ "UserSigValidity" SG_ 1193 C_PTGMNValueSet 3;
BA_ "GenSigSendType" SG_ 1193 C_PTGMNValueSet 4;
BA_ "Description" SG_ 1193 C_PTGMNValueSet "18.08.09_";
BA_ "Version" SG_ 1193 CF_AVN_PSMNValueSet "18.09.04";
BA_ "UserSigValidity" SG_ 1193 CF_AVN_PSMNValueSet 3;
BA_ "GenSigSendType" SG_ 1193 CF_AVN_PSMNValueSet 4;
BA_ "Description" SG_ 1193 CF_AVN_PSMNValueSet "18.08.09_";
BA_ "Version" SG_ 1193 C_HfreeTrunkTgNValueSet "18.09.04";
BA_ "UserSigValidity" SG_ 1193 C_HfreeTrunkTgNValueSet 3;
BA_ "GenSigSendType" SG_ 1193 C_HfreeTrunkTgNValueSet 4;
BA_ "Description" SG_ 1193 C_HfreeTrunkTgNValueSet "18.08.09_";
BA_ "Version" SG_ 1193 CF_AVN_TrfChgSet "18.09.04";
BA_ "UserSigValidity" SG_ 1193 CF_AVN_TrfChgSet 3;
BA_ "GenSigSendType" SG_ 1193 CF_AVN_TrfChgSet 4;
BA_ "Description" SG_ 1193 CF_AVN_TrfChgSet "18.08.09_";
BA_ "Version" SG_ 1193 CF_AVN_SCMNValueSet "18.09.04";
BA_ "UserSigValidity" SG_ 1193 CF_AVN_SCMNValueSet 3;
BA_ "GenSigSendType" SG_ 1193 CF_AVN_SCMNValueSet 4;
BA_ "Description" SG_ 1193 CF_AVN_SCMNValueSet "18.08.09_";
BA_ "Version" SG_ 1193 CF_AVN_ADrUNValueSet "18.09.04";
BA_ "UserSigValidity" SG_ 1193 CF_AVN_ADrUNValueSet 3;
BA_ "GenSigSendType" SG_ 1193 CF_AVN_ADrUNValueSet 4;
BA_ "Description" SG_ 1193 CF_AVN_ADrUNValueSet "18.08.09_";
BA_ "Version" SG_ 1193 CF_AVN_OTTurnNValueSet "18.09.04";
BA_ "UserSigValidity" SG_ 1193 CF_AVN_OTTurnNValueSet 3;
BA_ "GenSigSendType" SG_ 1193 CF_AVN_OTTurnNValueSet 4;
BA_ "Description" SG_ 1193 CF_AVN_OTTurnNValueSet "18.08.09_";
BA_ "Version" SG_ 1193 CF_Gway_WPCNValueSet "18.09.04";
BA_ "UserSigValidity" SG_ 1193 CF_Gway_WPCNValueSet 3;
BA_ "GenSigSendType" SG_ 1193 CF_Gway_WPCNValueSet 4;
BA_ "Description" SG_ 1193 CF_Gway_WPCNValueSet "18.08.09_";
BA_ "Version" SG_ 1193 C_AVN_RearWiperNValueSet "18.09.04";
BA_ "UserSigValidity" SG_ 1193 C_AVN_RearWiperNValueSet 3;
BA_ "GenSigSendType" SG_ 1193 C_AVN_RearWiperNValueSet 4;
BA_ "Description" SG_ 1193 C_AVN_RearWiperNValueSet "18.08.09_";
BA_ "Version" SG_ 1193 C_UnlockWelocomeNValueSet "18.09.04";
BA_ "UserSigValidity" SG_ 1193 C_UnlockWelocomeNValueSet 3;
BA_ "GenSigSendType" SG_ 1193 C_UnlockWelocomeNValueSet 4;
BA_ "Description" SG_ 1193 C_UnlockWelocomeNValueSet "18.08.09_";
BA_ "Version" SG_ 1193 C_SmartWelocomeNValueSet "18.09.04";
BA_ "UserSigValidity" SG_ 1193 C_SmartWelocomeNValueSet 3;
BA_ "GenSigSendType" SG_ 1193 C_SmartWelocomeNValueSet 4;
BA_ "Description" SG_ 1193 C_SmartWelocomeNValueSet "18.08.09_";
BA_ "Version" SG_ 1193 CF_AVN_PTGSpeedNValueSet "18.09.04";
BA_ "UserSigValidity" SG_ 1193 CF_AVN_PTGSpeedNValueSet 3;
BA_ "GenSigSendType" SG_ 1193 CF_AVN_PTGSpeedNValueSet 4;
BA_ "Description" SG_ 1193 CF_AVN_PTGSpeedNValueSet "18.08.09_";
BA_ "Version" SG_ 1193 CR_Datc_DRSeatWheel_USM_Set "18.09.04";
BA_ "UserSigValidity" SG_ 1193 CR_Datc_DRSeatWheel_USM_Set 3;
BA_ "GenSigSendType" SG_ 1193 CR_Datc_DRSeatWheel_USM_Set 4;
BA_ "Description" SG_ 1193 CR_Datc_DRSeatWheel_USM_Set "18.08.09_";
BA_ "Version" SG_ 1193 CF_AVN_TTUnlockNValueSet "18.09.04";
BA_ "UserSigValidity" SG_ 1193 CF_AVN_TTUnlockNValueSet 3;
BA_ "GenSigStartValue" SG_ 1193 CF_AVN_TTUnlockNValueSet 3;
BA_ "GenSigSendType" SG_ 1193 CF_AVN_TTUnlockNValueSet 4;
BA_ "Description" SG_ 1193 CF_AVN_TTUnlockNValueSet "18.08.09_";
BA_ "Version" SG_ 1193 CF_Gway_RWPCNValueSet "18.09.04";
BA_ "UserSigValidity" SG_ 1193 CF_Gway_RWPCNValueSet 3;
BA_ "GenSigSendType" SG_ 1193 CF_Gway_RWPCNValueSet 4;
BA_ "Description" SG_ 1193 CF_Gway_RWPCNValueSet "18.08.09_";
BA_ "Version" SG_ 1193 CF_Avn_HAPTICWARNINGNValueSet "18.12.01";
BA_ "UserSigValidity" SG_ 1193 CF_Avn_HAPTICWARNINGNValueSet 3;
BA_ "GenSigSendType" SG_ 1193 CF_Avn_HAPTICWARNINGNValueSet 4;
BA_ "Description" SG_ 1193 CF_Avn_HAPTICWARNINGNValueSet "18.11.09_";
BA_ "Version" SG_ 1193 CR_Datc_DRSeatHeat_USM_Set "18.09.04";
BA_ "UserSigValidity" SG_ 1193 CR_Datc_DRSeatHeat_USM_Set 3;
BA_ "GenSigSendType" SG_ 1193 CR_Datc_DRSeatHeat_USM_Set 4;
BA_ "Description" SG_ 1193 CR_Datc_DRSeatHeat_USM_Set "18.08.09_";
BA_ "Version" SG_ 1193 C_WALNValueSet "18.09.04";
BA_ "UserSigValidity" SG_ 1193 C_WALNValueSet 3;
BA_ "GenSigSendType" SG_ 1193 C_WALNValueSet 4;
BA_ "Description" SG_ 1193 C_WALNValueSet "18.08.09_";
BA_ "Version" SG_ 1193 C_ApprUnlockNValue "18.09.04";
BA_ "UserSigValidity" SG_ 1193 C_ApprUnlockNValue 3;
BA_ "GenSigSendType" SG_ 1193 C_ApprUnlockNValue 4;
BA_ "Description" SG_ 1193 C_ApprUnlockNValue "18.08.09_";
BA_ "Version" SG_ 1193 CF_AVN_EscortHLNValueSet "18.09.04";
BA_ "UserSigValidity" SG_ 1193 CF_AVN_EscortHLNValueSet 3;
BA_ "GenSigSendType" SG_ 1193 CF_AVN_EscortHLNValueSet 4;
BA_ "Description" SG_ 1193 CF_AVN_EscortHLNValueSet "18.08.09_";
BA_ "Version" SG_ 2365803012 DATC_Opt_Sys "22.05.02";
BA_ "UserSigValidity" SG_ 2365803012 DATC_Opt_Sys 7;
BA_ "Description" SG_ 2365803012 DATC_Opt_Sys "Bit0 (ADS)  : 0 - Non ADS / 1 - ADS

Bit1 (Fine Dust Sensor) : 0 - Fine Dust Sensor Not Applied / 1 - Fine Dust Sensor Applied.

Bit2 : (INDIRECT VENT) :   0- NON INDIRECT VENT /  1- INDIRECT VENT

Bit3 : (Multi-Air Mode) : 0 ? Not Apply / 1 ? Apply

Bit";
BA_ "Version" SG_ 2365803012 DATC_Opt_Func "22.05.02";
BA_ "UserSigValidity" SG_ 2365803012 DATC_Opt_Func 7;
BA_ "Description" SG_ 2365803012 DATC_Opt_Func "Bit0 (AirPurify) : 0 - Non AIR PURIFIER /  1 - AIR PURIFIER 

Bit1 (Smart_Vent) : 0 - Non SMART VENT / 1 ? SMART VENT

Bit2 (Defaog USM) : 0 - Not Apply / 1 - Apply 

Bit3 (Auto Fresh USM) : 0 - Not Apply / 1 ? Apply

Bit4 (Auto AirClean USM - China) : 0";
BA_ "Version" SG_ 2365803011 DATC_Typ_All_3 "22.06.05";
BA_ "UserSigValidity" SG_ 2365803011 DATC_Typ_All_3 7;
BA_ "Description" SG_ 2365803011 DATC_Typ_All_3 "This signal have to be used together with DATC_Typ_All_1~6 signals.



Bit0~1 (Front Mode Control): 0 ? None / 1 ? Single / 2 - Dual / 3 ? (Reserved) 

Bit2~3 (2nd Rear Mode Control): 0 ? None / 1 ? Single / 2 - Dual / 3 ? (Reserved) 

Bit4~5 (3rd Rear M";
BA_ "Version" SG_ 2365803011 DATC_Typ_All_4 "22.07.02";
BA_ "UserSigValidity" SG_ 2365803011 DATC_Typ_All_4 7;
BA_ "Description" SG_ 2365803011 DATC_Typ_All_4 "This signal have to be used together with DATC_Typ_All_1~6 signals.



Bit0~1 (Front Temp Control): 0 ? None / 1 ? Single / 2 - Dual / 3 ? (Reserved)

Bit2~3 (2nd Rear Temp Control): 0 ? None / 1 ? Single / 2 - Dual / 3 ? (Reserved) 

Bit4~5 (3rd Rear Te";
BA_ "Version" SG_ 2365803011 DATC_Typ_All_5 "22.06.05";
BA_ "UserSigValidity" SG_ 2365803011 DATC_Typ_All_5 7;
BA_ "Description" SG_ 2365803011 DATC_Typ_All_5 "This signal have to be used together with DATC_Typ_All_1~n signals.



Bit0~1 (FR DR Auto Step): 0 ? None / 1 ? Single(On/Off) / 2 ? 2 Step (High/Low/Off) / 3 ? 3 Step (High/Medium/Low/Off)

Bit2~3 (FR PS Auto Step): 0 ? None / 1 ? Single(On/Off) / 2 ? 2";
BA_ "Version" SG_ 2365803011 DATC_Typ_All_6 "22.06.05";
BA_ "UserSigValidity" SG_ 2365803011 DATC_Typ_All_6 7;
BA_ "Description" SG_ 2365803011 DATC_Typ_All_6 "This signal have to be used together with DATC_Typ_All_1~n signals.



Bit0~15 : Reserved";
BA_ "Version" SG_ 2365803010 DATC_SwVer4 "21.10.05";
BA_ "UserSigValidity" SG_ 2365803010 DATC_SwVer4 7;
BA_ "GenSigStartValue" SG_ 2365803010 DATC_SwVer4 127;
BA_ "Description" SG_ 2365803010 DATC_SwVer4 "This signal idnicates DATC Detail Software Version



Change it to an ASCII code value.";
BA_ "Version" SG_ 2365803010 DATC_Typ_All_1 "22.06.05";
BA_ "UserSigValidity" SG_ 2365803010 DATC_Typ_All_1 7;
BA_ "Description" SG_ 2365803010 DATC_Typ_All_1 "This signal have to be used together with DATC_Typ_All_1~n signals.



Bit0~1 (Front Control Type) : 0 ? None / 1 ? MTC / 2 ? ATC / 3 ? (Reserved)

Bit2~3 (2nd Rear Control Type) : 0 ? None /  1 ? MTC / 2 ? ATC / 3 ? (Reserved)

Bit4~5 (3rd Rear Control ";
BA_ "Version" SG_ 2365803010 DATC_Typ_All_2 "22.07.05";
BA_ "UserSigValidity" SG_ 2365803010 DATC_Typ_All_2 7;
BA_ "Description" SG_ 2365803010 DATC_Typ_All_2 "This signal have to be used together with DATC_Typ_All_1~n signals.



Bit0~1 (Front Mode Button Type) : 0 - 1button / 1 - 2button / 2 - 3button / 3 ? Reserved

Bit2 (Blower Button Type) : 0 - Blower down type / 1 - blower down off type

Bit3 (Front SYNC";
BA_ "Version" SG_ 2365803010 DATC_SwVer5 "21.10.05";
BA_ "UserSigValidity" SG_ 2365803010 DATC_SwVer5 7;
BA_ "GenSigStartValue" SG_ 2365803010 DATC_SwVer5 127;
BA_ "Description" SG_ 2365803010 DATC_SwVer5 "This signal idnicates DATC Detail Software Version



Change it to an ASCII code value.";
BA_ "Version" SG_ 2365803009 DATC_Crc16Val "21.09.03";
BA_ "UserSigValidity" SG_ 2365803009 DATC_Crc16Val 7;
BA_ "GenSigStartValue" SG_ 2365803009 DATC_Crc16Val 65535;
BA_ "Description" SG_ 2365803009 DATC_Crc16Val "The data area for CRC calculation is based on the data length (DLC) of the message DB.

The CRC shall be calculated over the entire data block (excluding the CRC bytes) including the user data, alive counter and Data ID



- CRC Polynomial (0x1021) , Ini";
BA_ "Version" SG_ 2365803009 DATC_AlvCnt16Val "21.09.03";
BA_ "UserSigValidity" SG_ 2365803009 DATC_AlvCnt16Val 7;
BA_ "Description" SG_ 2365803009 DATC_AlvCnt16Val "For the first transmission request for a data element the counter shall be initialized with 0 and shall be incremented by 1 for every subsequent send request. 

When the counter reaches the maximum value(0xFF), then it shall restart with 0 for the next s";
BA_ "Version" SG_ 2365803009 DATC_SwVer1 "19.09.02";
BA_ "UserSigValidity" SG_ 2365803009 DATC_SwVer1 7;
BA_ "GenSigStartValue" SG_ 2365803009 DATC_SwVer1 127;
BA_ "Description" SG_ 2365803009 DATC_SwVer1 "This signal idnicates DATC Software Version to display on H_U



Change it to an ASCII code value.";
BA_ "Version" SG_ 2365803009 DATC_SwVer2 "19.09.02";
BA_ "UserSigValidity" SG_ 2365803009 DATC_SwVer2 7;
BA_ "GenSigStartValue" SG_ 2365803009 DATC_SwVer2 127;
BA_ "Description" SG_ 2365803009 DATC_SwVer2 "This signal indicates DATC Software Version to display on H_U



Change it to an ASCII code value.";
BA_ "Version" SG_ 2365803009 DATC_SwVer3 "19.09.02";
BA_ "UserSigValidity" SG_ 2365803009 DATC_SwVer3 7;
BA_ "GenSigStartValue" SG_ 2365803009 DATC_SwVer3 127;
BA_ "Description" SG_ 2365803009 DATC_SwVer3 "This signal indicates DATC Software Version to display on H_U



Change it to an ASCII code value.";
BA_ "Version" SG_ 2365803009 DATC_Typ2 "22.02.02";
BA_ "UserSigValidity" SG_ 2365803009 DATC_Typ2 7;
BA_ "Description" SG_ 2365803009 DATC_Typ2 "Bit0: (AVN Controllable) :  0 ? NOT Apply / 1 ? Apply

Bit1~2 (Multi Auto Indicator) : 0 ? Front & Rear Not Applied (F/R 1step) / 1 ? Front 3 Step & Rear Not Applied (F 3step & R 1step) / 2 ? Front 3 Step & Rear 3 Step (F/R 3step)  / 3 ? Reserved

Bit3~5";
BA_ "Version" SG_ 1196 C_HCIMSWeightNValueSet "18.09.04";
BA_ "UserSigValidity" SG_ 1196 C_HCIMSWeightNValueSet 3;
BA_ "GenSigSendType" SG_ 1196 C_HCIMSWeightNValueSet 4;
BA_ "Description" SG_ 1196 C_HCIMSWeightNValueSet "18.08.09_";
BA_ "Version" SG_ 1196 C_HCIMSSitHeightNValueSet "18.09.04";
BA_ "UserSigValidity" SG_ 1196 C_HCIMSSitHeightNValueSet 3;
BA_ "GenSigSendType" SG_ 1196 C_HCIMSSitHeightNValueSet 4;
BA_ "Description" SG_ 1196 C_HCIMSSitHeightNValueSet "18.08.09_";
BA_ "Version" SG_ 1196 CF_AVN_BodySpprtSet "18.11.01";
BA_ "UserSigValidity" SG_ 1196 CF_AVN_BodySpprtSet 3;
BA_ "GenSigStartValue" SG_ 1196 CF_AVN_BodySpprtSet 3;
BA_ "GenSigSendType" SG_ 1196 CF_AVN_BodySpprtSet 4;
BA_ "Description" SG_ 1196 CF_AVN_BodySpprtSet "18.11.00_This signal is for the seat body support USM";
BA_ "Version" SG_ 1196 CF_AVN_AirSptTimeNValueSet "18.09.04";
BA_ "UserSigValidity" SG_ 1196 CF_AVN_AirSptTimeNValueSet 3;
BA_ "GenSigStartValue" SG_ 1196 CF_AVN_AirSptTimeNValueSet 7;
BA_ "GenSigSendType" SG_ 1196 CF_AVN_AirSptTimeNValueSet 4;
BA_ "Description" SG_ 1196 CF_AVN_AirSptTimeNValueSet "18.08.09_This signal is for the seat massage function time setting";
BA_ "Version" SG_ 1196 CF_AVN_AirSptStrNValue "18.09.04";
BA_ "UserSigValidity" SG_ 1196 CF_AVN_AirSptStrNValue 3;
BA_ "GenSigStartValue" SG_ 1196 CF_AVN_AirSptStrNValue 3;
BA_ "GenSigSendType" SG_ 1196 CF_AVN_AirSptStrNValue 4;
BA_ "Description" SG_ 1196 CF_AVN_AirSptStrNValue "18.08.09_This signal is for the seat massage intensity USM";
BA_ "Version" SG_ 1196 CF_AVN_SeatDrvModNValueSet "18.09.04";
BA_ "UserSigValidity" SG_ 1196 CF_AVN_SeatDrvModNValueSet 3;
BA_ "GenSigStartValue" SG_ 1196 CF_AVN_SeatDrvModNValueSet 3;
BA_ "GenSigSendType" SG_ 1196 CF_AVN_SeatDrvModNValueSet 4;
BA_ "Description" SG_ 1196 CF_AVN_SeatDrvModNValueSet "18.08.09_This signal is for the auto seat-drivemode user setting menu";
BA_ "Version" SG_ 1196 C_HCIMSHeightNvalueSet "18.09.04";
BA_ "UserSigValidity" SG_ 1196 C_HCIMSHeightNvalueSet 3;
BA_ "GenSigSendType" SG_ 1196 C_HCIMSHeightNvalueSet 4;
BA_ "Description" SG_ 1196 C_HCIMSHeightNvalueSet "18.08.09_";
BA_ "Version" SG_ 1196 CF_AVN_CushSoftNValueSet "18.10.05";
BA_ "UserSigValidity" SG_ 1196 CF_AVN_CushSoftNValueSet 3;
BA_ "GenSigStartValue" SG_ 1196 CF_AVN_CushSoftNValueSet 7;
BA_ "GenSigSendType" SG_ 1196 CF_AVN_CushSoftNValueSet 4;
BA_ "Description" SG_ 1196 CF_AVN_CushSoftNValueSet "18.10.03_This signal is for the cushsoftness setting";
BA_ "Version" SG_ 1196 C_SmrtSldngDrNValueSet "19.01.10";
BA_ "UserSigValidity" SG_ 1196 C_SmrtSldngDrNValueSet 3;
BA_ "GenSigSendType" SG_ 1196 C_SmrtSldngDrNValueSet 4;
BA_ "Description" SG_ 1196 C_SmrtSldngDrNValueSet "USM request for Smart Sliding Door";
BA_ "Version" SG_ 1196 CF_AVN_TurboPressureUnit "19.06.02";
BA_ "UserSigValidity" SG_ 1196 CF_AVN_TurboPressureUnit 3;
BA_ "GenSigSendType" SG_ 1196 CF_AVN_TurboPressureUnit 4;
BA_ "Description" SG_ 1196 CF_AVN_TurboPressureUnit "USM Request for Turbo Boost Pressure Unit";
BA_ "Version" SG_ 1196 CF_AVN_CluTorqueUnit "19.06.02";
BA_ "UserSigValidity" SG_ 1196 CF_AVN_CluTorqueUnit 3;
BA_ "GenSigSendType" SG_ 1196 CF_AVN_CluTorqueUnit 4;
BA_ "Description" SG_ 1196 CF_AVN_CluTorqueUnit "USM Request for Torque Unit Setting";
BA_ "Version" SG_ 1196 CF_AVN_HCIMSButtonCommand "18.09.04";
BA_ "UserSigValidity" SG_ 1196 CF_AVN_HCIMSButtonCommand 3;
BA_ "GenSigSendType" SG_ 1196 CF_AVN_HCIMSButtonCommand 4;
BA_ "Description" SG_ 1196 CF_AVN_HCIMSButtonCommand "18.08.09_";
BA_ "Version" SG_ 255 BCM_Crc20Val "21.09.03";
BA_ "UserSigValidity" SG_ 255 BCM_Crc20Val 0;
BA_ "GenSigSendType" SG_ 255 BCM_Crc20Val 4;
BA_ "Description" SG_ 255 BCM_Crc20Val "The data area for CRC calculation is based on the data length (DLC) of the message DB.

The CRC shall be calculated over the entire data block (excluding the CRC bytes) including the user data, alive counter and Data ID 

 

- CRC Polynomial (0x1D) , Ini";
BA_ "Version" SG_ 255 BCM_AlvCnt20Val "21.09.03";
BA_ "UserSigValidity" SG_ 255 BCM_AlvCnt20Val 0;
BA_ "GenSigSendType" SG_ 255 BCM_AlvCnt20Val 4;
BA_ "Description" SG_ 255 BCM_AlvCnt20Val "For the first transmission request for a data element the counter shall be initialized with 0 and shall be incremented by 1

for every subsequent send request. When the counter reaches the maximum value(0xE), then it shall restart with 0 for the next sen";
BA_ "Version" SG_ 255 BckGls_RrGlsHtdOnCmd "21.09.05";
BA_ "NetworkRequestHoldingTime" SG_ 255 BckGls_RrGlsHtdOnCmd 5000;
BA_ "NetworkRequest" SG_ 255 BckGls_RrGlsHtdOnCmd 0;
BA_ "UserSigValidity" SG_ 255 BckGls_RrGlsHtdOnCmd 0;
BA_ "GenSigSendType" SG_ 255 BckGls_RrGlsHtdOnCmd 4;
BA_ "Description" SG_ 255 BckGls_RrGlsHtdOnCmd "Rear Glass Heated Command";
BA_ "Version" SG_ 255 Wndshld_FrtGlsHtdOnCmd "20.08.02";
BA_ "NetworkRequestHoldingTime" SG_ 255 Wndshld_FrtGlsHtdOnCmd 5000;
BA_ "NetworkRequest" SG_ 255 Wndshld_FrtGlsHtdOnCmd 0;
BA_ "UserSigValidity" SG_ 255 Wndshld_FrtGlsHtdOnCmd 0;
BA_ "GenSigSendType" SG_ 255 Wndshld_FrtGlsHtdOnCmd 4;
BA_ "Description" SG_ 255 Wndshld_FrtGlsHtdOnCmd "Front Heated Glass Command";
BA_ "Version" SG_ 255 Mirror_MirFldOpt "21.04.00";
BA_ "NetworkRequestHoldingTime" SG_ 255 Mirror_MirFldOpt 5000;
BA_ "NetworkRequest" SG_ 255 Mirror_MirFldOpt 0;
BA_ "UserSigValidity" SG_ 255 Mirror_MirFldOpt 0;
BA_ "GenSigSendType" SG_ 255 Mirror_MirFldOpt 4;
BA_ "Description" SG_ 255 Mirror_MirFldOpt "Outside Mirror Electric Fold Option Signal";
BA_ "Version" SG_ 255 Window_AsstPwrWdwSunroofEnblSta "20.08.02";
BA_ "NetworkRequestHoldingTime" SG_ 255 Window_AsstPwrWdwSunroofEnblSta 5000;
BA_ "NetworkRequest" SG_ 255 Window_AsstPwrWdwSunroofEnblSta 0;
BA_ "UserSigValidity" SG_ 255 Window_AsstPwrWdwSunroofEnblSta 0;
BA_ "GenSigSendType" SG_ 255 Window_AsstPwrWdwSunroofEnblSta 4;
BA_ "Description" SG_ 255 Window_AsstPwrWdwSunroofEnblSta "Assist Power Window And Sunroof Enable";
BA_ "Version" SG_ 255 Window_RrPwrWdwEnblSta "20.08.02";
BA_ "NetworkRequestHoldingTime" SG_ 255 Window_RrPwrWdwEnblSta 5000;
BA_ "NetworkRequest" SG_ 255 Window_RrPwrWdwEnblSta 0;
BA_ "UserSigValidity" SG_ 255 Window_RrPwrWdwEnblSta 0;
BA_ "GenSigSendType" SG_ 255 Window_RrPwrWdwEnblSta 4;
BA_ "Description" SG_ 255 Window_RrPwrWdwEnblSta "Rear Power Window Enable";
BA_ "Version" SG_ 255 Window_RrPwrWdwLkInd "20.08.02";
BA_ "NetworkRequestHoldingTime" SG_ 255 Window_RrPwrWdwLkInd 5000;
BA_ "NetworkRequest" SG_ 255 Window_RrPwrWdwLkInd 0;
BA_ "UserSigValidity" SG_ 255 Window_RrPwrWdwLkInd 0;
BA_ "GenSigSendType" SG_ 255 Window_RrPwrWdwLkInd 4;
BA_ "Description" SG_ 255 Window_RrPwrWdwLkInd "RearPpower Window Lock Indicator Command";
BA_ "Version" SG_ 255 Window_DrvPwrWdwCmd "21.01.06";
BA_ "NetworkRequestHoldingTime" SG_ 255 Window_DrvPwrWdwCmd 5000;
BA_ "NetworkRequest" SG_ 255 Window_DrvPwrWdwCmd 0;
BA_ "UserSigValidity" SG_ 255 Window_DrvPwrWdwCmd 0;
BA_ "GenSigSendType" SG_ 255 Window_DrvPwrWdwCmd 4;
BA_ "Description" SG_ 255 Window_DrvPwrWdwCmd "Driver Power Window Command";
BA_ "Version" SG_ 255 Window_AsstPwrWdwCmd "21.03.00";
BA_ "NetworkRequestHoldingTime" SG_ 255 Window_AsstPwrWdwCmd 5000;
BA_ "NetworkRequest" SG_ 255 Window_AsstPwrWdwCmd 0;
BA_ "UserSigValidity" SG_ 255 Window_AsstPwrWdwCmd 0;
BA_ "GenSigSendType" SG_ 255 Window_AsstPwrWdwCmd 4;
BA_ "Description" SG_ 255 Window_AsstPwrWdwCmd "Assist Power Window Command";
BA_ "Version" SG_ 255 Window_RrLftPwrWdwCmd "21.03.00";
BA_ "NetworkRequestHoldingTime" SG_ 255 Window_RrLftPwrWdwCmd 5000;
BA_ "NetworkRequest" SG_ 255 Window_RrLftPwrWdwCmd 0;
BA_ "UserSigValidity" SG_ 255 Window_RrLftPwrWdwCmd 0;
BA_ "GenSigSendType" SG_ 255 Window_RrLftPwrWdwCmd 4;
BA_ "Description" SG_ 255 Window_RrLftPwrWdwCmd "Rear Left Power Window Command";
BA_ "Version" SG_ 255 Window_RrRtPwrWdwCmd "21.03.00";
BA_ "NetworkRequestHoldingTime" SG_ 255 Window_RrRtPwrWdwCmd 5000;
BA_ "NetworkRequest" SG_ 255 Window_RrRtPwrWdwCmd 0;
BA_ "UserSigValidity" SG_ 255 Window_RrRtPwrWdwCmd 0;
BA_ "GenSigSendType" SG_ 255 Window_RrRtPwrWdwCmd 4;
BA_ "Description" SG_ 255 Window_RrRtPwrWdwCmd "Rear Right Power Window Command";
BA_ "Version" SG_ 255 Mirror_FldUnfldCmd "21.03.00";
BA_ "NetworkRequestHoldingTime" SG_ 255 Mirror_FldUnfldCmd 5000;
BA_ "NetworkRequest" SG_ 255 Mirror_FldUnfldCmd 0;
BA_ "UserSigValidity" SG_ 255 Mirror_FldUnfldCmd 0;
BA_ "GenSigSendType" SG_ 255 Mirror_FldUnfldCmd 4;
BA_ "Description" SG_ 255 Mirror_FldUnfldCmd "Mirror Folding Unfolding Command";
BA_ "Version" SG_ 255 Mirror_FldCtrlSta "21.03.00";
BA_ "NetworkRequestHoldingTime" SG_ 255 Mirror_FldCtrlSta 5000;
BA_ "NetworkRequest" SG_ 255 Mirror_FldCtrlSta 0;
BA_ "UserSigValidity" SG_ 255 Mirror_FldCtrlSta 0;
BA_ "GenSigSendType" SG_ 255 Mirror_FldCtrlSta 4;
BA_ "Description" SG_ 255 Mirror_FldCtrlSta "Mirror Fold and Folding Control State";
BA_ "Version" SG_ 255 Mirror_UnFldCtrlSta "21.03.00";
BA_ "NetworkRequestHoldingTime" SG_ 255 Mirror_UnFldCtrlSta 5000;
BA_ "NetworkRequest" SG_ 255 Mirror_UnFldCtrlSta 0;
BA_ "UserSigValidity" SG_ 255 Mirror_UnFldCtrlSta 0;
BA_ "GenSigSendType" SG_ 255 Mirror_UnFldCtrlSta 4;
BA_ "Description" SG_ 255 Mirror_UnFldCtrlSta "Mirror Unfold and Unfolding Control State";
BA_ "Version" SG_ 255 Mirror_PosMnlCmd "21.03.00";
BA_ "NetworkRequestHoldingTime" SG_ 255 Mirror_PosMnlCmd 5000;
BA_ "NetworkRequest" SG_ 255 Mirror_PosMnlCmd 0;
BA_ "UserSigValidity" SG_ 255 Mirror_PosMnlCmd 0;
BA_ "GenSigSendType" SG_ 255 Mirror_PosMnlCmd 4;
BA_ "Description" SG_ 255 Mirror_PosMnlCmd "Mirror Positioning Request";
BA_ "Version" SG_ 255 Mirror_SelSwIndCmd "21.03.00";
BA_ "NetworkRequestHoldingTime" SG_ 255 Mirror_SelSwIndCmd 5000;
BA_ "NetworkRequest" SG_ 255 Mirror_SelSwIndCmd 0;
BA_ "UserSigValidity" SG_ 255 Mirror_SelSwIndCmd 0;
BA_ "GenSigSendType" SG_ 255 Mirror_SelSwIndCmd 4;
BA_ "Description" SG_ 255 Mirror_SelSwIndCmd "Mirror Select Switch Indicator Command";
BA_ "Version" SG_ 255 BCM_SafetyWdwOptTyp2 "20.08.05";
BA_ "NetworkRequestHoldingTime" SG_ 255 BCM_SafetyWdwOptTyp2 5000;
BA_ "NetworkRequest" SG_ 255 BCM_SafetyWdwOptTyp2 0;
BA_ "UserSigValidity" SG_ 255 BCM_SafetyWdwOptTyp2 0;
BA_ "GenSigSendType" SG_ 255 BCM_SafetyWdwOptTyp2 4;
BA_ "Description" SG_ 255 BCM_SafetyWdwOptTyp2 "Option Signal for Safety Window System";
BA_ "Version" SG_ 255 Mirror_LHOSMirPlyBckSta "21.03.00";
BA_ "NetworkRequestHoldingTime" SG_ 255 Mirror_LHOSMirPlyBckSta 5000;
BA_ "NetworkRequest" SG_ 255 Mirror_LHOSMirPlyBckSta 0;
BA_ "UserSigValidity" SG_ 255 Mirror_LHOSMirPlyBckSta 0;
BA_ "GenSigSendType" SG_ 255 Mirror_LHOSMirPlyBckSta 4;
BA_ "Description" SG_ 255 Mirror_LHOSMirPlyBckSta "This siganl indicates Left O/S Mirror moving state for IMS From BDC";
BA_ "Version" SG_ 255 Mirror_RHOSMirPlyBckSta "21.03.00";
BA_ "NetworkRequestHoldingTime" SG_ 255 Mirror_RHOSMirPlyBckSta 5000;
BA_ "NetworkRequest" SG_ 255 Mirror_RHOSMirPlyBckSta 0;
BA_ "UserSigValidity" SG_ 255 Mirror_RHOSMirPlyBckSta 0;
BA_ "GenSigSendType" SG_ 255 Mirror_RHOSMirPlyBckSta 4;
BA_ "Description" SG_ 255 Mirror_RHOSMirPlyBckSta "This siganl indicates Right O/S Mirror moving state for IMS From BDC";
BA_ "Version" SG_ 255 Mirror_SelSwSta "20.12.00";
BA_ "NetworkRequestHoldingTime" SG_ 255 Mirror_SelSwSta 5000;
BA_ "NetworkRequest" SG_ 255 Mirror_SelSwSta 0;
BA_ "UserSigValidity" SG_ 255 Mirror_SelSwSta 0;
BA_ "GenSigSendType" SG_ 255 Mirror_SelSwSta 4;
BA_ "Description" SG_ 255 Mirror_SelSwSta "Outside Mirror Select Button Status";
BA_ "Version" SG_ 255 BckGls_RrGlsHtdOpt "21.06.08";
BA_ "UserSigValidity" SG_ 255 BckGls_RrGlsHtdOpt 0;
BA_ "GenSigSendType" SG_ 255 BckGls_RrGlsHtdOpt 4;
BA_ "Description" SG_ 255 BckGls_RrGlsHtdOpt "Back Glass_Rear Glass Heated Option Signal";
BA_ "Version" SG_ 2328015105 ADAS_CMD_Crc34Val "21.09.03";
BA_ "RoutingFactor" SG_ 2328015105 ADAS_CMD_Crc34Val 2;
BA_ "UserSigValidity" SG_ 2328015105 ADAS_CMD_Crc34Val 3;
BA_ "GenSigStartValue" SG_ 2328015105 ADAS_CMD_Crc34Val 65535;
BA_ "Description" SG_ 2328015105 ADAS_CMD_Crc34Val "The data area for CRC calculation is based on the data length (DLC) of the message DB.

The CRC shall be calculated over the entire data block (excluding the CRC bytes) including the user data, alive counter and Data ID



- CRC Polynomial (0x1021) , Ini";
BA_ "Version" SG_ 2328015105 ADAS_CMD_AlvCnt34Val "21.09.03";
BA_ "RoutingFactor" SG_ 2328015105 ADAS_CMD_AlvCnt34Val 2;
BA_ "UserSigValidity" SG_ 2328015105 ADAS_CMD_AlvCnt34Val 3;
BA_ "Description" SG_ 2328015105 ADAS_CMD_AlvCnt34Val "For the first transmission request for a data element the counter shall be initialized with 0 and shall be incremented by 1 for every subsequent send request. 

When the counter reaches the maximum value(0xFF), then it shall restart with 0 for the next s";
BA_ "Version" SG_ 2328015105 HDP_RDD_WarnSta "22.05.00";
BA_ "RoutingFactor" SG_ 2328015105 HDP_RDD_WarnSta 2;
BA_ "UserSigValidity" SG_ 2328015105 HDP_RDD_WarnSta 0;
BA_ "Description" SG_ 2328015105 HDP_RDD_WarnSta "Request CLU to activate the corresponding warning device(s) according to the HDP redundancy MRM warning level.";
BA_ "Version" SG_ 2328015105 HDP_RDD_LongAsstCtrlSta "21.04.00";
BA_ "RoutingFactor" SG_ 2328015105 HDP_RDD_LongAsstCtrlSta 2;
BA_ "UserSigValidity" SG_ 2328015105 HDP_RDD_LongAsstCtrlSta 3;
BA_ "Description" SG_ 2328015105 HDP_RDD_LongAsstCtrlSta "This signal indicates that the HDP redundancy MRM longitudinal control is operating.";
BA_ "Version" SG_ 2328015105 HDP_RDD_HzrdLmpReqSta "21.04.02";
BA_ "RoutingFactor" SG_ 2328015105 HDP_RDD_HzrdLmpReqSta 2;
BA_ "UserSigValidity" SG_ 2328015105 HDP_RDD_HzrdLmpReqSta 3;
BA_ "Description" SG_ 2328015105 HDP_RDD_HzrdLmpReqSta "This signal indicates the requestion of the hazard lamp lightning from FR_CMR.";
BA_ "Version" SG_ 2328015105 HDP_RDD_ACIActvDispSta "21.04.00";
BA_ "RoutingFactor" SG_ 2328015105 HDP_RDD_ACIActvDispSta 2;
BA_ "UserSigValidity" SG_ 2328015105 HDP_RDD_ACIActvDispSta 3;
BA_ "Description" SG_ 2328015105 HDP_RDD_ACIActvDispSta "State for angle control";
BA_ "Version" SG_ 2328015106 HDP_RDD_EMStbltActvReqSta "21.04.00";
BA_ "RoutingFactor" SG_ 2328015106 HDP_RDD_EMStbltActvReqSta 2;
BA_ "UserSigValidity" SG_ 2328015106 HDP_RDD_EMStbltActvReqSta 3;
BA_ "Description" SG_ 2328015106 HDP_RDD_EMStbltActvReqSta "Depending on the driving situation, EM tells PSB to release(no alert), retract or pull the seat belt for occupant protection or warning.";
BA_REL_ "GenSigTimeoutTime" BU_SG_REL_ DPSU SG_ 1279 AVN_SeatPosPlyBck_Btn 0;
BA_REL_ "GenSigTimeoutTime" BU_SG_REL_ SWRC SG_ 2328016129 VCU_EvDrvRdyCluDispSta 1500;
BA_REL_ "GenSigTimeoutTime" BU_SG_REL_ ALBCU SG_ 200 CF_AVN_BodySpprtSet_AST 0;
BA_REL_ "GenSigTimeoutTime" BU_SG_REL_ ALBCU SG_ 200 CF_AVN_AirSptTimeNValueSet_AST 0;
BA_REL_ "GenSigTimeoutTime" BU_SG_REL_ ALBCU SG_ 200 CF_AVN_AirSptStrNValue_AST 0;
BA_REL_ "GenSigTimeoutTime" BU_SG_REL_ ALBCU SG_ 200 CF_AVN_SeatDrvModNvalueSet_AST 0;
BA_REL_ "GenSigTimeoutTime" BU_SG_REL_ WPC2 SG_ 200 CF_Gway_WPC2_NValueSet 0;
BA_REL_ "GenSigTimeoutTime" BU_SG_REL_ APSU SG_ 1159 C_AstRclBwdSw_HU 1500;
BA_REL_ "GenSigTimeoutTime" BU_SG_REL_ APSU SG_ 1159 C_AstHeightUpSw_HU 1500;
BA_REL_ "GenSigTimeoutTime" BU_SG_REL_ APSU SG_ 1159 C_AstTiltDnSw_HU 1500;
BA_REL_ "GenSigTimeoutTime" BU_SG_REL_ APSU SG_ 1159 C_AstTiltUpSw_HU 1500;
BA_REL_ "GenSigTimeoutTime" BU_SG_REL_ ASAU SG_ 1159 C_AstLumbarDefSw_HU 1500;
BA_REL_ "GenSigTimeoutTime" BU_SG_REL_ ALBCU SG_ 1159 C_AstLumbarDefSw_HU 1500;
BA_REL_ "GenSigTimeoutTime" BU_SG_REL_ ASAU SG_ 1159 C_AstLumbarLowSw_HU 1500;
BA_REL_ "GenSigTimeoutTime" BU_SG_REL_ ALBCU SG_ 1159 C_AstLumbarLowSw_HU 1500;
BA_REL_ "GenSigTimeoutTime" BU_SG_REL_ APSU SG_ 1159 C_AstRclFwdSw_HU 1500;
BA_REL_ "GenSigTimeoutTime" BU_SG_REL_ ASAU SG_ 1159 C_AstLumbarMidSw_HU 1500;
BA_REL_ "GenSigTimeoutTime" BU_SG_REL_ ALBCU SG_ 1159 C_AstLumbarMidSw_HU 1500;
BA_REL_ "GenSigTimeoutTime" BU_SG_REL_ ASAU SG_ 1159 C_AstLumbarUpSw_HU 1500;
BA_REL_ "GenSigTimeoutTime" BU_SG_REL_ ALBCU SG_ 1159 C_AstLumbarUpSw_HU 1500;
BA_REL_ "GenSigTimeoutTime" BU_SG_REL_ APSU SG_ 1159 C_RRSlideFwdSw_HU 1500;
BA_REL_ "GenSigTimeoutTime" BU_SG_REL_ RRPSU SG_ 1159 C_RRSlideFwdSw_HU 1500;
BA_REL_ "GenSigTimeoutTime" BU_SG_REL_ APSU SG_ 1159 C_RRSlideBwdSw_HU 1500;
BA_REL_ "GenSigTimeoutTime" BU_SG_REL_ RRPSU SG_ 1159 C_RRSlideBwdSw_HU 1500;
BA_REL_ "GenSigTimeoutTime" BU_SG_REL_ APSU SG_ 1159 C_RLSlideFwdSw_HU 1500;
BA_REL_ "GenSigTimeoutTime" BU_SG_REL_ RRPSU SG_ 1159 C_RLSlideFwdSw_HU 1500;
BA_REL_ "GenSigTimeoutTime" BU_SG_REL_ RLPSU SG_ 1159 C_RLSlideFwdSw_HU 1500;
BA_REL_ "GenSigTimeoutTime" BU_SG_REL_ APSU SG_ 1159 C_RLSlideBwdSw_HU 1500;
BA_REL_ "GenSigTimeoutTime" BU_SG_REL_ RRPSU SG_ 1159 C_RLSlideBwdSw_HU 1500;
BA_REL_ "GenSigTimeoutTime" BU_SG_REL_ RLPSU SG_ 1159 C_RLSlideBwdSw_HU 1500;
BA_REL_ "GenSigTimeoutTime" BU_SG_REL_ APSU SG_ 1159 C_AstSlideBwdSw_HU 1500;
BA_REL_ "GenSigTimeoutTime" BU_SG_REL_ APSU SG_ 1159 C_AstSlideFwdSw_HU 1500;
BA_REL_ "GenSigTimeoutTime" BU_SG_REL_ APSU SG_ 1159 C_AstHeightDnSw_HU 1500;
BA_REL_ "GenSigTimeoutTime" BU_SG_REL_ DPSU SG_ 197 C_DrvRclBwdSw_HU 1500;
BA_REL_ "GenSigTimeoutTime" BU_SG_REL_ DPSU SG_ 197 C_DrvSlideFwdSw_HU 1500;
BA_REL_ "GenSigTimeoutTime" BU_SG_REL_ APSU SG_ 197 C_RLLegSupFwdSw_HU 1500;
BA_REL_ "GenSigTimeoutTime" BU_SG_REL_ RLPSU SG_ 197 C_RLLegSupFwdSw_HU 1500;
BA_REL_ "GenSigTimeoutTime" BU_SG_REL_ APSU SG_ 197 C_RLLegSupBwdSw_HU 1500;
BA_REL_ "GenSigTimeoutTime" BU_SG_REL_ RLPSU SG_ 197 C_RLLegSupBwdSw_HU 1500;
BA_REL_ "GenSigTimeoutTime" BU_SG_REL_ DPSU SG_ 197 C_DrvSlideBwdSw_HU 1500;
BA_REL_ "GenSigTimeoutTime" BU_SG_REL_ APSU SG_ 197 C_RLLegSupUpSw_HU 1500;
BA_REL_ "GenSigTimeoutTime" BU_SG_REL_ RLPSU SG_ 197 C_RLLegSupUpSw_HU 1500;
BA_REL_ "GenSigTimeoutTime" BU_SG_REL_ APSU SG_ 197 C_RLLegSupDnSw_HU 1500;
BA_REL_ "GenSigTimeoutTime" BU_SG_REL_ RLPSU SG_ 197 C_RLLegSupDnSw_HU 1500;
BA_REL_ "GenSigTimeoutTime" BU_SG_REL_ DPSU SG_ 197 C_DrvRclFwdSw_HU 1500;
BA_REL_ "GenSigTimeoutTime" BU_SG_REL_ ATS SG_ 2382595073 DATC_FrDrvBlwDis 1500;
BA_REL_ "GenSigTimeoutTime" BU_SG_REL_ ATS SG_ 2382595073 DATC_FrPsBlwDis 1500;
BA_REL_ "GenSigTimeoutTime" BU_SG_REL_ ATS SG_ 2382595073 DATC_HeatDis 1500;
BA_REL_ "GenSigTimeoutTime" BU_SG_REL_ ATS SG_ 2382595073 DATC_DrvOnlyDis 1500;
BA_REL_ "GenSigTimeoutTime" BU_SG_REL_ ATS SG_ 2382595073 DATC_RrClmtScrnDis 1500;
BA_REL_ "GenSigTimeoutTime" BU_SG_REL_ ATS SG_ 2382595073 DATC_AUTOStep 1500;
BA_REL_ "GenSigTimeoutTime" BU_SG_REL_ ATS SG_ 2382595073 DATC_IntakeDis 1500;
BA_REL_ "GenSigTimeoutTime" BU_SG_REL_ BLTN_CAM SG_ 1167 ICU_BattAutoCutPreWrng 5000;
BA_REL_ "GenSigTimeoutTime" BU_SG_REL_ CGW_CCU SG_ 223 ALBCU_SmartCtrl_1h 0;
BA_REL_ "GenSigTimeoutTime" BU_SG_REL_ CGW_CCU SG_ 223 ALBCU_SmartCtrl_2h 0;
BA_REL_ "GenSigTimeoutTime" BU_SG_REL_ CGW_CCU SG_ 223 ALBCU_SmartCtrl_Status 0;
BA_REL_ "GenSigTimeoutTime" BU_SG_REL_ FCS SG_ 1174 Drv_SHVU_SeatOptSta 1500;
BA_REL_ "GenSigTimeoutTime" BU_SG_REL_ CGW_CCU SG_ 1174 Drv_SHVU_SeatOptSta 1500;
BA_REL_ "GenSigTimeoutTime" BU_SG_REL_ CGW_CCU SG_ 1174 Drv_SHVU_SeatOptSta 1500;
BA_REL_ "GenSigTimeoutTime" BU_SG_REL_ FCS SG_ 1174 Drv_SHVU_HtSwHiIndSta 1500;
BA_REL_ "GenSigTimeoutTime" BU_SG_REL_ CGW_CCU SG_ 1174 Drv_SHVU_HtSwHiIndSta 1500;
BA_REL_ "GenSigTimeoutTime" BU_SG_REL_ FCS SG_ 1174 Drv_SHVU_HtSwMidIndSta 1500;
BA_REL_ "GenSigTimeoutTime" BU_SG_REL_ CGW_CCU SG_ 1174 Drv_SHVU_HtSwMidIndSta 1500;
BA_REL_ "GenSigTimeoutTime" BU_SG_REL_ FCS SG_ 1174 Drv_SHVU_HtSwLowIndSta 1500;
BA_REL_ "GenSigTimeoutTime" BU_SG_REL_ CGW_CCU SG_ 1174 Drv_SHVU_HtSwLowIndSta 1500;
BA_REL_ "GenSigTimeoutTime" BU_SG_REL_ FCS SG_ 1174 Drv_SHVU_VntSwHiIndSta 1500;
BA_REL_ "GenSigTimeoutTime" BU_SG_REL_ CGW_CCU SG_ 1174 Drv_SHVU_VntSwHiIndSta 1500;
BA_REL_ "GenSigTimeoutTime" BU_SG_REL_ FCS SG_ 1174 Drv_SHVU_VntSwMidIndSta 1500;
BA_REL_ "GenSigTimeoutTime" BU_SG_REL_ CGW_CCU SG_ 1174 Drv_SHVU_VntSwMidIndSta 1500;
BA_REL_ "GenSigTimeoutTime" BU_SG_REL_ FCS SG_ 1174 Drv_SHVU_VntSwLowIndSta 1500;
BA_REL_ "GenSigTimeoutTime" BU_SG_REL_ CGW_CCU SG_ 1174 Drv_SHVU_VntSwLowIndSta 1500;
BA_REL_ "GenSigTimeoutTime" BU_SG_REL_ CGW_CCU SG_ 1174 Drv_SHVU_HtBlcUSMSta 1500;
BA_REL_ "GenSigTimeoutTime" BU_SG_REL_ FCS SG_ 1174 Drv_SHVU_SeatHtOperSta 1500;
BA_REL_ "GenSigTimeoutTime" BU_SG_REL_ CGW_CCU SG_ 1174 Drv_SHVU_SeatHtOperSta 1500;
BA_REL_ "GenSigTimeoutTime" BU_SG_REL_ FCS SG_ 1174 Drv_SHVU_HtSwHiIndSta_RHD 1500;
BA_REL_ "GenSigTimeoutTime" BU_SG_REL_ CGW_CCU SG_ 1174 Drv_SHVU_HtSwHiIndSta_RHD 1500;
BA_REL_ "GenSigTimeoutTime" BU_SG_REL_ FCS SG_ 1174 Drv_SHVU_HtSwMidIndSta_RHD 1500;
BA_REL_ "GenSigTimeoutTime" BU_SG_REL_ CGW_CCU SG_ 1174 Drv_SHVU_HtSwMidIndSta_RHD 1500;
BA_REL_ "GenSigTimeoutTime" BU_SG_REL_ FCS SG_ 1174 Drv_SHVU_HtSwLowIndSta_RHD 1500;
BA_REL_ "GenSigTimeoutTime" BU_SG_REL_ CGW_CCU SG_ 1174 Drv_SHVU_HtSwLowIndSta_RHD 1500;
BA_REL_ "GenSigTimeoutTime" BU_SG_REL_ FCS SG_ 1174 Drv_SHVU_VntSwHiIndSta_RHD 1500;
BA_REL_ "GenSigTimeoutTime" BU_SG_REL_ CGW_CCU SG_ 1174 Drv_SHVU_VntSwHiIndSta_RHD 1500;
BA_REL_ "GenSigTimeoutTime" BU_SG_REL_ FCS SG_ 1174 Drv_SHVU_VntSwMidIndSta_RHD 1500;
BA_REL_ "GenSigTimeoutTime" BU_SG_REL_ CGW_CCU SG_ 1174 Drv_SHVU_VntSwMidIndSta_RHD 1500;
BA_REL_ "GenSigTimeoutTime" BU_SG_REL_ FCS SG_ 1174 Drv_SHVU_VntSwLowIndSta_RHD 1500;
BA_REL_ "GenSigTimeoutTime" BU_SG_REL_ CGW_CCU SG_ 1174 Drv_SHVU_VntSwLowIndSta_RHD 1500;
BA_REL_ "GenSigTimeoutTime" BU_SG_REL_ CGW_CCU SG_ 1179 Drv_SHVU_SeatEcoSta 0;
BA_REL_ "GenSigTimeoutTime" BU_SG_REL_ CGW_CCU SG_ 1179 SHVU_Drv_Beep1Sound 0;
BA_REL_ "GenSigTimeoutTime" BU_SG_REL_ CGW_CCU SG_ 1179 SHVU_CtrlScreenDis 0;
BA_REL_ "GenSigTimeoutTime" BU_SG_REL_ CGW_CCU SG_ 1180 SHVU_Ast_Beep1Sound 0;
BA_REL_ "GenSigTimeoutTime" BU_SG_REL_ CGW_CCU SG_ 1180 Ast_SHVU_SeatEcoSta 0;
BA_REL_ "GenSigTimeoutTime" BU_SG_REL_ ATS SG_ 208 RR_SHVU_DTCdisplay 1500;
BA_REL_ "GenSigTimeoutTime" BU_SG_REL_ ATS SG_ 208 RR_SHVU_DiagMode 1500;
BA_REL_ "GenSigTimeoutTime" BU_SG_REL_ ATS SG_ 1181 RL_SHVU_SeatEcoSta 0;
BA_REL_ "GenSigTimeoutTime" BU_SG_REL_ CGW_CCU SG_ 1181 RL_SHVU_SeatEcoSta 0;
BA_REL_ "GenSigTimeoutTime" BU_SG_REL_ ATS SG_ 1182 RR_SHVU_SeatEcoSta 0;
BA_REL_ "GenSigTimeoutTime" BU_SG_REL_ CGW_CCU SG_ 1182 RR_SHVU_SeatEcoSta 0;
BA_REL_ "GenSigTimeoutTime" BU_SG_REL_ BLTN_CAM SG_ 1186 C_PreCrankReq 0;
BA_REL_ "GenSigTimeoutTime" BU_SG_REL_ APSU SG_ 1186 C_TeleAstSeatOpCmdIBOX 0;
BA_REL_ "GenSigTimeoutTime" BU_SG_REL_ SHVU_FR SG_ 1186 C_TeleAstSeatOpCmdIBOX 0;
BA_REL_ "GenSigTimeoutTime" BU_SG_REL_ SHVU_FR SG_ 1186 C_TeleDrvSeatOpCmdIBOX 0;
BA_REL_ "GenSigTimeoutTime" BU_SG_REL_ DPSU SG_ 1186 C_TeleDrvSeatOpCmdIBOX 0;
BA_REL_ "GenSigTimeoutTime" BU_SG_REL_ RRHV SG_ 1186 C_TeleRRSeatOpCmdIBOX 0;
BA_REL_ "GenSigTimeoutTime" BU_SG_REL_ SHVU_FR SG_ 1186 C_TeleRRSeatOpCmdIBOX 0;
BA_REL_ "GenSigTimeoutTime" BU_SG_REL_ SHVU_RR SG_ 1186 C_TeleRRSeatOpCmdIBOX 0;
BA_REL_ "GenSigTimeoutTime" BU_SG_REL_ RRPSU SG_ 1186 C_TeleRRSeatOpCmdIBOX 0;
BA_REL_ "GenSigTimeoutTime" BU_SG_REL_ ATS SG_ 1186 C_TeleRRSeatOpCmdIBOX 0;
BA_REL_ "GenSigTimeoutTime" BU_SG_REL_ RLHV SG_ 1186 C_TeleRLSeatOpCmdIBOX 0;
BA_REL_ "GenSigTimeoutTime" BU_SG_REL_ SHVU_FR SG_ 1186 C_TeleRLSeatOpCmdIBOX 0;
BA_REL_ "GenSigTimeoutTime" BU_SG_REL_ SHVU_RR SG_ 1186 C_TeleRLSeatOpCmdIBOX 0;
BA_REL_ "GenSigTimeoutTime" BU_SG_REL_ RLPSU SG_ 1186 C_TeleRLSeatOpCmdIBOX 0;
BA_REL_ "GenSigTimeoutTime" BU_SG_REL_ ATS SG_ 1186 C_TeleRLSeatOpCmdIBOX 0;
BA_REL_ "GenSigTimeoutTime" BU_SG_REL_ RCM SG_ 1185 C_RrBlindCmdAVN 0;
BA_REL_ "GenSigTimeoutTime" BU_SG_REL_ RCM SG_ 1185 C_RrGlassCmdAVN 0;
BA_REL_ "GenSigTimeoutTime" BU_SG_REL_ RCM SG_ 1185 C_BlindCmdAVN 0;
BA_REL_ "GenSigTimeoutTime" BU_SG_REL_ RCM SG_ 1185 C_GlassCmdAVN 0;
BA_REL_ "GenSigTimeoutTime" BU_SG_REL_ APSU SG_ 1189 C_RLTiltUpSw_HU 1500;
BA_REL_ "GenSigTimeoutTime" BU_SG_REL_ RRPSU SG_ 1189 C_RLTiltUpSw_HU 1500;
BA_REL_ "GenSigTimeoutTime" BU_SG_REL_ RLPSU SG_ 1189 C_RLTiltUpSw_HU 1500;
BA_REL_ "GenSigTimeoutTime" BU_SG_REL_ APSU SG_ 1189 C_RRTiltDownSw_HU 1500;
BA_REL_ "GenSigTimeoutTime" BU_SG_REL_ RRPSU SG_ 1189 C_RRTiltDownSw_HU 1500;
BA_REL_ "GenSigTimeoutTime" BU_SG_REL_ APSU SG_ 1189 C_RRTiltUpSw_HU 1500;
BA_REL_ "GenSigTimeoutTime" BU_SG_REL_ RRPSU SG_ 1189 C_RRTiltUpSw_HU 1500;
BA_REL_ "GenSigTimeoutTime" BU_SG_REL_ APSU SG_ 1189 C_RLRclBwdSw_HU 1500;
BA_REL_ "GenSigTimeoutTime" BU_SG_REL_ RRPSU SG_ 1189 C_RLRclBwdSw_HU 1500;
BA_REL_ "GenSigTimeoutTime" BU_SG_REL_ RLPSU SG_ 1189 C_RLRclBwdSw_HU 1500;
BA_REL_ "GenSigTimeoutTime" BU_SG_REL_ APSU SG_ 1189 C_RLRclFwdSw_HU 1500;
BA_REL_ "GenSigTimeoutTime" BU_SG_REL_ RRPSU SG_ 1189 C_RLRclFwdSw_HU 1500;
BA_REL_ "GenSigTimeoutTime" BU_SG_REL_ RLPSU SG_ 1189 C_RLRclFwdSw_HU 1500;
BA_REL_ "GenSigTimeoutTime" BU_SG_REL_ RLPSU SG_ 1189 C_RLFldSw_HU 1500;
BA_REL_ "GenSigTimeoutTime" BU_SG_REL_ APSU SG_ 1189 C_RRRclBwdSw_HU 1500;
BA_REL_ "GenSigTimeoutTime" BU_SG_REL_ RRPSU SG_ 1189 C_RRRclBwdSw_HU 1500;
BA_REL_ "GenSigTimeoutTime" BU_SG_REL_ APSU SG_ 1189 C_RRRclFwdSw_HU 1500;
BA_REL_ "GenSigTimeoutTime" BU_SG_REL_ RRPSU SG_ 1189 C_RRRclFwdSw_HU 1500;
BA_REL_ "GenSigTimeoutTime" BU_SG_REL_ PFSU SG_ 1189 C_TLHrestFldSw_HU 1500;
BA_REL_ "GenSigTimeoutTime" BU_SG_REL_ PFSU SG_ 1189 C_TRHrestFldSw_HU 1500;
BA_REL_ "GenSigTimeoutTime" BU_SG_REL_ RRPSU SG_ 1189 C_RLRlxSW_HU 1500;
BA_REL_ "GenSigTimeoutTime" BU_SG_REL_ RLPSU SG_ 1189 C_RLRlxSW_HU 1500;
BA_REL_ "GenSigTimeoutTime" BU_SG_REL_ RRPSU SG_ 1189 C_RRRlxSW_HU 1500;
BA_REL_ "GenSigTimeoutTime" BU_SG_REL_ PFSU SG_ 1189 C_TLFldSw_HU 1500;
BA_REL_ "GenSigTimeoutTime" BU_SG_REL_ PFSU SG_ 1189 C_TRFldSw_HU 1500;
BA_REL_ "GenSigTimeoutTime" BU_SG_REL_ RRPSU SG_ 1189 C_RRFldSw_HU 1500;
BA_REL_ "GenSigTimeoutTime" BU_SG_REL_ APSU SG_ 1189 C_RLTiltDownSw_HU 1500;
BA_REL_ "GenSigTimeoutTime" BU_SG_REL_ RRPSU SG_ 1189 C_RLTiltDownSw_HU 1500;
BA_REL_ "GenSigTimeoutTime" BU_SG_REL_ RLPSU SG_ 1189 C_RLTiltDownSw_HU 1500;
BA_REL_ "GenSigTimeoutTime" BU_SG_REL_ WPC SG_ 1195 CF_AVN_CluUSMReset 0;
BA_REL_ "GenSigTimeoutTime" BU_SG_REL_ RWPC SG_ 1195 CF_AVN_CluUSMReset 0;
BA_REL_ "GenSigTimeoutTime" BU_SG_REL_ SLB SG_ 1195 CF_AVN_CluUSMReset 0;
BA_REL_ "GenSigTimeoutTime" BU_SG_REL_ ARS SG_ 1195 CF_AVN_CluUSMReset 0;
BA_REL_ "GenSigTimeoutTime" BU_SG_REL_ APSU SG_ 1195 CF_AVN_CluUSMReset 0;
BA_REL_ "GenSigTimeoutTime" BU_SG_REL_ RLHV SG_ 1195 CF_AVN_CluUSMReset 0;
BA_REL_ "GenSigTimeoutTime" BU_SG_REL_ RRHV SG_ 1195 CF_AVN_CluUSMReset 0;
BA_REL_ "GenSigTimeoutTime" BU_SG_REL_ SHVU_FR SG_ 1195 CF_AVN_CluUSMReset 0;
BA_REL_ "GenSigTimeoutTime" BU_SG_REL_ SHVU_RR SG_ 1195 CF_AVN_CluUSMReset 0;
BA_REL_ "GenSigTimeoutTime" BU_SG_REL_ DPSU SG_ 1195 CF_AVN_CluUSMReset 0;
BA_REL_ "GenSigTimeoutTime" BU_SG_REL_ DLBCU SG_ 1195 CF_AVN_CluUSMReset 0;
BA_REL_ "GenSigTimeoutTime" BU_SG_REL_ PFSU SG_ 1195 CF_AVN_CluUSMReset 0;
BA_REL_ "GenSigTimeoutTime" BU_SG_REL_ RRPSU SG_ 1195 CF_AVN_CluUSMReset 0;
BA_REL_ "GenSigTimeoutTime" BU_SG_REL_ RLPSU SG_ 1195 CF_AVN_CluUSMReset 0;
BA_REL_ "GenSigTimeoutTime" BU_SG_REL_ ATS SG_ 1195 CF_AVN_CluUSMReset 0;
BA_REL_ "GenSigTimeoutTime" BU_SG_REL_ DSAU SG_ 1195 CF_AVN_CluUSMReset 0;
BA_REL_ "GenSigTimeoutTime" BU_SG_REL_ ASAU SG_ 1195 CF_AVN_CluUSMReset 0;
BA_REL_ "GenSigTimeoutTime" BU_SG_REL_ RCM SG_ 1195 CF_AVN_CluUSMReset 0;
BA_REL_ "GenSigTimeoutTime" BU_SG_REL_ BLTN_CAM SG_ 1195 CF_AVN_CluUSMReset 0;
BA_REL_ "GenSigTimeoutTime" BU_SG_REL_ SGU SG_ 1195 CF_AVN_CluUSMReset 0;
BA_REL_ "GenSigTimeoutTime" BU_SG_REL_ ALBCU SG_ 1195 CF_AVN_CluUSMReset 0;
BA_REL_ "GenSigTimeoutTime" BU_SG_REL_ WPC2 SG_ 1195 CF_AVN_CluUSMReset 0;
BA_REL_ "GenSigTimeoutTime" BU_SG_REL_ DPSU SG_ 1193 CF_AVN_PSMNValueSet 0;
BA_REL_ "GenSigTimeoutTime" BU_SG_REL_ WPC SG_ 1193 CF_Gway_WPCNValueSet 0;
BA_REL_ "GenSigTimeoutTime" BU_SG_REL_ WPC2 SG_ 1193 CF_Gway_WPCNValueSet 0;
BA_REL_ "GenSigTimeoutTime" BU_SG_REL_ RWPC SG_ 1193 CF_Gway_RWPCNValueSet 0;
BA_REL_ "GenSigTimeoutTime" BU_SG_REL_ ATS SG_ 2365803009 DATC_Typ2 5000;
BA_REL_ "GenSigTimeoutTime" BU_SG_REL_ DPSU SG_ 1196 C_HCIMSWeightNValueSet 0;
BA_REL_ "GenSigTimeoutTime" BU_SG_REL_ DPSU SG_ 1196 C_HCIMSSitHeightNValueSet 0;
BA_REL_ "GenSigTimeoutTime" BU_SG_REL_ DLBCU SG_ 1196 CF_AVN_BodySpprtSet 0;
BA_REL_ "GenSigTimeoutTime" BU_SG_REL_ DSAU SG_ 1196 CF_AVN_BodySpprtSet 0;
BA_REL_ "GenSigTimeoutTime" BU_SG_REL_ DLBCU SG_ 1196 CF_AVN_AirSptTimeNValueSet 0;
BA_REL_ "GenSigTimeoutTime" BU_SG_REL_ DLBCU SG_ 1196 CF_AVN_AirSptStrNValue 0;
BA_REL_ "GenSigTimeoutTime" BU_SG_REL_ DLBCU SG_ 1196 CF_AVN_SeatDrvModNValueSet 0;
BA_REL_ "GenSigTimeoutTime" BU_SG_REL_ DSAU SG_ 1196 CF_AVN_SeatDrvModNValueSet 0;
BA_REL_ "GenSigTimeoutTime" BU_SG_REL_ DPSU SG_ 1196 C_HCIMSHeightNvalueSet 0;
BA_REL_ "GenSigTimeoutTime" BU_SG_REL_ DLBCU SG_ 1196 CF_AVN_CushSoftNValueSet 0;
BA_REL_ "GenSigTimeoutTime" BU_SG_REL_ DPSU SG_ 1196 CF_AVN_HCIMSButtonCommand 0;
BA_REL_ "GenSigTimeoutTime" BU_SG_REL_ RCM SG_ 255 Window_AsstPwrWdwSunroofEnblSta 1500;
BA_REL_ "GenSigTimeoutTime" BU_SG_REL_ DPSU SG_ 255 Mirror_LHOSMirPlyBckSta 1500;
BA_REL_ "GenSigTimeoutTime" BU_SG_REL_ DPSU SG_ 255 Mirror_RHOSMirPlyBckSta 1500;
BA_REL_ "GenSigTimeoutTime" BU_SG_REL_ PSB SG_ 2328015105 HDP_RDD_WarnSta 1500;
BA_REL_ "GenSigTimeoutTime" BU_SG_REL_ HOD SG_ 2328015105 HDP_RDD_WarnSta 1500;
BA_REL_ "GenSigTimeoutTime" BU_SG_REL_ PSB SG_ 2328015106 HDP_RDD_EMStbltActvReqSta 1500;
VAL_ 1279 USM_SmartRegen_Map_Set 0 "Default" 1 "Off(Disbaled)" 2 "On(Enabled)" 3 "Invalid" ;
VAL_ 1279 USM_SmartRegen_Sens_Set 0 "Default" 1 "Slow" 2 "Normal" 3 "Fast" 4 "Reserved" 5 "Reserved" 6 "Reserved" 7 "Invalid" ;
VAL_ 1279 AVN_SeatPosMemory_Btn 0 "Default" 1 "Memory 1" 2 "Memory 2" 3 "Memory 3" 4 "Reserved" 5 "Reserved" 6 "Reserved" 7 "Invalid" ;
VAL_ 1279 AVN_SeatPosPlyBck_Btn 0 "Default" 1 "Memory 1" 2 "Memory 2" 3 "Memory 3" 4 "Reserved" 5 "Reserved" 6 "Stop" 7 "Invalid" ;
VAL_ 1279 USM_RhstaLvlEnaSetReq 0 "Default" 1 "Off" 2 "On" 3 "Invalid" ;
VAL_ 1279 USM_CMSDayBrgtnsLvlLHSetReq 0 "-5 Level" 1 "-4 Level" 2 "-3 Level" 3 "-2 Level" 4 "-1 Level" 5 "0 Level" 6 "1 Level" 7 "2 Level" 8 "3 Level" 9 "4 Level" 10 "5 Level" 11 "Not Used" 12 "Not Used" 13 "Not Used" 14 "Error Indicator" 15 "Invalid" ;
VAL_ 1279 USM_CMSNgtBrgtnsLvlLHSetReq 0 "-5 Level" 1 "-4 Level" 2 "-3 Level" 3 "-2 Level" 4 "-1 Level" 5 "0 Level" 6 "1 Level" 7 "2 Level" 8 "3 Level" 9 "4 Level" 10 "5 Level" 11 "Not Used" 12 "Not Used" 13 "Not Used" 14 "Error Indicator" 15 "Invalid" ;
VAL_ 1279 USM_CMSDayBrgtnsLvlRHSetReq 0 "-5 Level" 1 "-4 Level" 2 "-3 Level" 3 "-2 Level" 4 "-1 Level" 5 "0 Level" 6 "1 Level" 7 "2 Level" 8 "3 Level" 9 "4 Level" 10 "5 Level" 11 "Not Used" 12 "Not Used" 13 "Not Used" 14 "Error Indicator" 15 "Invalid" ;
VAL_ 1279 USM_CMSNgtBrgtnsLvlRHSetReq 0 "-5 Level" 1 "-4 Level" 2 "-3 Level" 3 "-2 Level" 4 "-1 Level" 5 "0 Level" 6 "1 Level" 7 "2 Level" 8 "3 Level" 9 "4 Level" 10 "5 Level" 11 "Not Used" 12 "Not Used" 13 "Not Used" 14 "Error Indicator" 15 "Invalid" ;
VAL_ 1279 USM_CMSBrgtnsReset 0 "Default" 1 "Reset" 2 "Reserved" 3 "Invalid" ;
VAL_ 1279 USM_TurnDistLnDispSetReq 0 "Default" 1 "Off" 2 "On" 3 "Invalid" ;
VAL_ 1279 PCA_FrSd_NValueSet 0 "Default" 1 "Off" 2 "On" 3 "Invalid" ;
VAL_ 1279 CF_AVN_1stRrStRmndNValueSet 0 "Default" 1 "Off" 2 "On" 3 "Invalid" ;
VAL_ 1279 C_AllDrOpnNValueSet 0 "Default" 1 "Off" 2 "PSD Open" 3 "PSD PTG Open" 4 "Reserved" 5 "Reserved" 6 "Reserved" 7 "Invalid" ;
VAL_ 1279 USM_RpmECOSet 0 "Default" 1 "Off" 2 "On(RPM Gauge Display)" 3 "Invalid" ;
VAL_ 1279 VESS_ChgGuideMdLvl 0 "Default" 1 "Level 1(¾àÇÏ°Ô)" 2 "Level 2(Áß°£)" 3 "Level 3(°­ÇÏ°Ô)" 4 "Reserved" 5 "Reserved" 6 "Off" 7 "Invalid" ;
VAL_ 1279 Usm_RpmSPORTSet 0 "Default" 1 "Off" 2 "On(RPM Gauge Display)" 3 "Invalid" ;
VAL_ 2328016129 VCU_Crc5Val 0 "0x0x0~0xFFFF:CRCValue" 65535 "0x0x0~0xFFFF:CRCValue" ;
VAL_ 2328016129 VCU_AlvCnt5Val 0 "0x0x0~0xFF:AlvCntValue" 255 "0x0x0~0xFF:AlvCntValue" ;
VAL_ 2328016129 VCU_EvDrvRdyCluDispSta 0 "Ready Lamp Off" 1 "Ready Lamp On" 2 "Error Indicator" 3 "Blinking" ;
VAL_ 2328016129 VCU_PwrDnModeSta 0 "None" 1 "Set" 2 "Not used" 3 "Error Indicator" ;
VAL_ 2328016129 VCU_CluWarnMsgSta 0 "None(Default)" 1 "Regenerative Braking System Operating Stop" 2 "AC,PTC Controllable when EV_Ready is OFF" 3 "-" 4 "Gear P Change Impossible(VB 10.5V)" 5 "Gear P Change Impossible(VB 9.5V)" 6 "-" 7 "-" 8 "Reserved" 9 "Reserved" 10 "Reserved" 11 "Reserved" 12 "Reserved" 13 "Reserved" 14 "Reserved" 15 "Reserved" ;
VAL_ 2328016129 VCU_DteOffDispSta 0 "None" 1 "DTE Off('---' Display)" 2 "Not used" 3 "Error Indicator" ;
VAL_ 2328016129 VCU_LowSocAlertSta 0 "No Alert" 1 "Low SOC Alert 1" 2 "Low SOC Alert 2" 3 "Low SOC Alert 3" 4 "Reserved" 5 "Reserved" 6 "Reserved" 7 "SOC Unavailable Alert" ;
VAL_ 2328016129 VCU_VcrmReq 0 "Wait(Not Request Logging)" 1 "Service/MIL Lamp On(Request Logging)" 2 "Warning, Abnormal IG Off(Request Logging)" 3 "Reserved" ;
VAL_ 2328016129 VCU_PdlWarnMsgSta 0 "None" 1 "Pop-up Request" 2 "Not used" 3 "Error Indicator" ;
VAL_ 2328016129 VCU_AwdDiagDispSta 0 "Off" 1 "On" 2 "NotUsed" 3 "ErrorIndicator" ;
VAL_ 2328016129 VCU_AwdLockDispSta 0 "Off" 1 "On" 2 "NotUsed" 3 "ErrorIndicator" ;
VAL_ 2328016129 VCU_VirtualApsActSta 0 "Real APS" 1 "Virtual APS for Crz" 2 "Not used" 3 "Error Indicator" ;
VAL_ 2328016129 VCU_ServiceLampReq 0 "None" 1 "Service Lamp On" 2 "Not used" 3 "Error Indicator" ;
VAL_ 2328016129 VCU_ServiceModeSta 0 "Normal" 1 "Certification Mode (F)" 2 "Certification Mode (R)" 3 "Error Indicator" ;
VAL_ 2328016129 VCU_NPosWshModSta 0 "Normal" 1 "Standby" 2 "N Wash Mode" 3 "Reserved" ;
VAL_ 2328016129 VCU_PowerTrainType 0 "One Moter" 1 "Dual Motor(Base)" 2 "Dual Motor(Performance)" 3 "Reserved" ;
VAL_ 2328016130 VCU_AvnDteOnCalcSta 0 "Display DTE Value" 1 "Display 'Recalculating'" 2 "Not used" 3 "Error Indicator" ;
VAL_ 2328016130 VCU_SbwWarnMsgSta 0 "Off" 1 "Warning 1 - SCU/Parking System Failure" 2 "Warning 2 - Unavailable to Shift Gear" 3 "Warning 3 - Brake On for Gear Shift" 4 "Warning 4 - Unavailable to Park" 5 "Warning 5 - Auto Parked" 6 "Warning 6 - Unavailable to Release Park" 7 "Warning 7 - Same Button Re-Entered" ;
VAL_ 2328016130 VCU_EnergyFlowSta 0 "None" 1 "No Flow" 2 "Front Motor Motoring" 3 "Rear Motor Motoring" 4 "Dual Motor Motoring" 5 "Not Used" 6 "Front Motor Generating" 7 "Rear Motor Generating" 8 "Dual Motor Generating" 9 "Not Used" 10 "Reserved" 11 "Reserved" 12 "Reserved" 13 "Reserved" 14 "Reserved" 15 "Reserved" ;
VAL_ 2328016130 VCU_SbwWarnSndSta 0 "Warning Sound Off" 1 "Warning Sound On" 2 "Not used" 3 "Error Indicator" ;
VAL_ 2328016130 VCU_EcoGuide_DispReq 0 "Smart ECO Guide Off" 1 "Smart ECO Guide On" 2 "Not used" 3 "Error Indicator" ;
VAL_ 2328016130 VCU_EcoGuide_ApsGaugeVal 0 "Not Display" 1 "1~100" 2 "1~100" 3 "1~100" 4 "1~100" 5 "1~100" 6 "1~100" 7 "1~100" 8 "1~100" 9 "1~100" 10 "1~100" 11 "1~100" 12 "1~100" 13 "1~100" 14 "1~100" 15 "1~100" 16 "1~100" 17 "1~100" 18 "1~100" 19 "1~100" 20 "1~100" 21 "1~100" 22 "1~100" 23 "1~100" 24 "1~100" 25 "1~100" 26 "1~100" 27 "1~100" 28 "1~100" 29 "1~100" 30 "1~100" 31 "1~100" 32 "1~100" 33 "1~100" 34 "1~100" 35 "1~100" 36 "1~100" 37 "1~100" 38 "1~100" 39 "1~100" 40 "1~100" 41 "1~100" 42 "1~100" 43 "1~100" 44 "1~100" 45 "1~100" 46 "1~100" 47 "1~100" 48 "1~100" 49 "1~100" 50 "1~100" 51 "1~100" 52 "1~100" 53 "1~100" 54 "1~100" 55 "1~100" 56 "1~100" 57 "1~100" 58 "1~100" 59 "1~100" 60 "1~100" 61 "1~100" 62 "1~100" 63 "1~100" 64 "1~100" 65 "1~100" 66 "1~100" 67 "1~100" 68 "1~100" 69 "1~100" 70 "1~100" 71 "1~100" 72 "1~100" 73 "1~100" 74 "1~100" 75 "1~100" 76 "1~100" 77 "1~100" 78 "1~100" 79 "1~100" 80 "1~100" 81 "1~100" 82 "1~100" 83 "1~100" 84 "1~100" 85 "1~100" 86 "1~100" 87 "1~100" 88 "1~100" 89 "1~100" 90 "1~100" 91 "1~100" 92 "1~100" 93 "1~100" 94 "1~100" 95 "1~100" 96 "1~100" 97 "1~100" 98 "1~100" 99 "1~100" 100 "1~100" 101 "Reserved" 102 "Reserved" 103 "Reserved" 104 "Reserved" 105 "Reserved" 106 "Reserved" 107 "Reserved" 108 "Reserved" 109 "Reserved" 110 "Reserved" 111 "Reserved" 112 "Reserved" 113 "Reserved" 114 "Reserved" 115 "Reserved" 116 "Reserved" 117 "Reserved" 118 "Reserved" 119 "Reserved" 120 "Reserved" 121 "Reserved" 122 "Reserved" 123 "Reserved" 124 "Reserved" 125 "Reserved" 126 "Reserved" 127 "Reserved" ;
VAL_ 2328016130 VCU_EcoGuide_EcoGaugeVal 0 "Not Display" 1 "1~100" 2 "1~100" 3 "1~100" 4 "1~100" 5 "1~100" 6 "1~100" 7 "1~100" 8 "1~100" 9 "1~100" 10 "1~100" 11 "1~100" 12 "1~100" 13 "1~100" 14 "1~100" 15 "1~100" 16 "1~100" 17 "1~100" 18 "1~100" 19 "1~100" 20 "1~100" 21 "1~100" 22 "1~100" 23 "1~100" 24 "1~100" 25 "1~100" 26 "1~100" 27 "1~100" 28 "1~100" 29 "1~100" 30 "1~100" 31 "1~100" 32 "1~100" 33 "1~100" 34 "1~100" 35 "1~100" 36 "1~100" 37 "1~100" 38 "1~100" 39 "1~100" 40 "1~100" 41 "1~100" 42 "1~100" 43 "1~100" 44 "1~100" 45 "1~100" 46 "1~100" 47 "1~100" 48 "1~100" 49 "1~100" 50 "1~100" 51 "1~100" 52 "1~100" 53 "1~100" 54 "1~100" 55 "1~100" 56 "1~100" 57 "1~100" 58 "1~100" 59 "1~100" 60 "1~100" 61 "1~100" 62 "1~100" 63 "1~100" 64 "1~100" 65 "1~100" 66 "1~100" 67 "1~100" 68 "1~100" 69 "1~100" 70 "1~100" 71 "1~100" 72 "1~100" 73 "1~100" 74 "1~100" 75 "1~100" 76 "1~100" 77 "1~100" 78 "1~100" 79 "1~100" 80 "1~100" 81 "1~100" 82 "1~100" 83 "1~100" 84 "1~100" 85 "1~100" 86 "1~100" 87 "1~100" 88 "1~100" 89 "1~100" 90 "1~100" 91 "1~100" 92 "1~100" 93 "1~100" 94 "1~100" 95 "1~100" 96 "1~100" 97 "1~100" 98 "1~100" 99 "1~100" 100 "1~100" 101 "Reserved" 102 "Reserved" 103 "Reserved" 104 "Reserved" 105 "Reserved" 106 "Reserved" 107 "Reserved" 108 "Reserved" 109 "Reserved" 110 "Reserved" 111 "Reserved" 112 "Reserved" 113 "Reserved" 114 "Reserved" 115 "Reserved" 116 "Reserved" 117 "Reserved" 118 "Reserved" 119 "Reserved" 120 "Reserved" 121 "Reserved" 122 "Reserved" 123 "Reserved" 124 "Reserved" 125 "Reserved" 126 "Reserved" 127 "Reserved" ;
VAL_ 2328016131 VCU_DistFromRegenDispReq 0 "Default" 1 "Displayed ---" 2 "Positive Value" 3 "Negative Value" ;
VAL_ 2328016131 VCU_DrvStyle_DispReq 0 "Invalid" 1 "Valid" 2 "Not used" 3 "Error Indicator" ;
VAL_ 2328016131 VCU_DrvStyle_HighLightSta 0 "None" 1 "High Fuel Efficiency" 2 "Normal Fuel Efficiency" 3 "Low Fuel Efficiency" ;
VAL_ 2328016131 VCU_DrvStyle_EcoVal 0 "0x0x0~0x64:0~100" 100 "0x0x0~0x64:0~100" 101 "Reserved" 102 "Reserved" 103 "Reserved" 104 "Reserved" 105 "Reserved" 106 "Reserved" 107 "Reserved" 108 "Reserved" 109 "Reserved" 110 "Reserved" 111 "Reserved" 112 "Reserved" 113 "Reserved" 114 "Reserved" 115 "Reserved" 116 "Reserved" 117 "Reserved" 118 "Reserved" 119 "Reserved" 120 "Reserved" 121 "Reserved" 122 "Reserved" 123 "Reserved" 124 "Reserved" 125 "Reserved" 126 "Reserved" 127 "Reserved" ;
VAL_ 2328016131 VCU_DrvStyle_NonEcoVal 0 "0x0x0~0x64:0~100" 100 "0x0x0~0x64:0~100" 101 "Reserved" 102 "Reserved" 103 "Reserved" 104 "Reserved" 105 "Reserved" 106 "Reserved" 107 "Reserved" 108 "Reserved" 109 "Reserved" 110 "Reserved" 111 "Reserved" 112 "Reserved" 113 "Reserved" 114 "Reserved" 115 "Reserved" 116 "Reserved" 117 "Reserved" 118 "Reserved" 119 "Reserved" 120 "Reserved" 121 "Reserved" 122 "Reserved" 123 "Reserved" 124 "Reserved" 125 "Reserved" 126 "Reserved" 127 "Reserved" ;
VAL_ 2328016131 VCU_DrvStyle_NorVal 0 "0x0x0~0x64:0~100" 100 "0x0x0~0x64:0~100" 101 "Reserved" 102 "Reserved" 103 "Reserved" 104 "Reserved" 105 "Reserved" 106 "Reserved" 107 "Reserved" 108 "Reserved" 109 "Reserved" 110 "Reserved" 111 "Reserved" 112 "Reserved" 113 "Reserved" 114 "Reserved" 115 "Reserved" 116 "Reserved" 117 "Reserved" 118 "Reserved" 119 "Reserved" 120 "Reserved" 121 "Reserved" 122 "Reserved" 123 "Reserved" 124 "Reserved" 125 "Reserved" 126 "Reserved" 127 "Reserved" ;
VAL_ 200 CF_AVN_ADrLNValueSet_2 0 "Default" 1 "Off" 2 "Vehicle Speed On (15km/h)" 3 "Vehicle Speed On and Shift Lever On" 4 "Invalid" 5 "Reserved" 6 "Reserved" 7 "Reserved" ;
VAL_ 200 CF_AVN_FCA_JC_OnOffEquipNvalueSe 0 "Default" 1 "Off" 2 "On" 3 "Invalid" ;
VAL_ 200 CF_AVN_FCA_FrSdOnOffEquipNvalueS 0 "Default" 1 "Off" 2 "On" 3 "Invalid" ;
VAL_ 200 CF_AVN_LKA_OnOffEquip2NvalueSet 0 "Default" 1 "Off" 2 "On" 3 "Invalid" ;
VAL_ 200 CF_AVN_BCA_OnOffEquip2NvalueSet 0 "Default" 1 "Off" 2 "On" 3 "Invalid" ;
VAL_ 200 CF_AVN_BVM_OnOffEquipNvalueSet 0 "Default" 1 "Off" 2 "On" 3 "Invalid" ;
VAL_ 200 CF_AVN_SEA_OnOffEquip3NvalueSet 0 "Default" 1 "Off" 2 "On" 3 "Invalid" ;
VAL_ 200 CF_AVN_BodySpprtSet_AST 0 "Default" 1 "Off" 2 "On" 3 "Invalid" ;
VAL_ 200 CF_AVN_SEW_OnOffEquip3NvalueSet 0 "Default" 1 "Off" 2 "On" 3 "Invalid" ;
VAL_ 200 CF_AVN_HudImsAutoSave 0 "Default" 1 "Off" 2 "On" 3 "Invalid" ;
VAL_ 200 USM_PwrDrBuzzerNValueSet 0 "Default" 1 "Off" 2 "On" 3 "Invalid" ;
VAL_ 200 CF_AVN_DWLNValueSet 0 "Default" 1 "Comfort" 2 "Natural" 3 "Dynamic" 4 "Reserved" 5 "Reserved" 6 "Reserved" 7 "Invalid" ;
VAL_ 200 CF_AVN_AirSptTimeNValueSet_AST 0 "Default" 1 "Short" 2 "Normal" 3 "Long" 4 "Reserved" 5 "Reserved" 6 "Reserved" 7 "Invalid" ;
VAL_ 200 CF_AVN_AirSptStrNValue_AST 0 "Default" 1 "Normal" 2 "Intense" 3 "Invalid" ;
VAL_ 200 CF_AVN_SeatDrvModNvalueSet_AST 0 "Default" 1 "Off" 2 "On" 3 "Invalid" ;
VAL_ 200 CF_AVN_TPMS_TireReplaceNValueSet 0 "Default" 1 "Off(Standard)" 2 "ON(SnowChain)" 3 "Reserved" 4 "Reserved" 5 "Reserved" 6 "Not Used(Gray)" 7 "Error Indicator" ;
VAL_ 200 CF_AVN_TowModeSet 0 "Default" 1 "Off" 2 "Small Weight" 3 "Medium Weight" 4 "Maximum Weight" 5 "Reserved" 6 "Reserved" 7 "Invalid" ;
VAL_ 200 USM_PwrDrCloseByBraekNValueSet 0 "Default" 1 "Off" 2 "On" 3 "Invalid" ;
VAL_ 200 CF_AVN_ISLANAOffstNvalueSet 0 "Default" 1 "-10kph -10mph" 2 "-5kph -5mph" 3 "0kph 0mph" 4 "5kph 5mph" 5 "10kph 10mph" 6 "Reserved" 7 "Invalid" ;
VAL_ 200 CF_Gway_WPC2_NValueSet 0 "Default" 1 "Off (Disable)" 2 "On (Enable)" 3 "Invalid" ;
VAL_ 200 USM_DrvGhostDoorReq 0 "Default" 1 "Off" 2 "On" 3 "Invalid" ;
VAL_ 200 USM_AstGhostDoorReq 0 "Default" 1 "Off" 2 "On" 3 "Invalid" ;
VAL_ 200 USM_RLGhostDoorReq 0 "Default" 1 "Off" 2 "On" 3 "Invalid" ;
VAL_ 200 CF_AVN_FCA_FrOnOffEquipNvalueSet 0 "Default" 1 "Off" 2 "On" 3 "Invalid" ;
VAL_ 200 CF_AVN_FCA_WarnTimeNvalueSet 0 "Default" 1 "Late" 2 "Normal" 3 "Reserved" 4 "Reserved" 5 "Reserved" 6 "Reserved" 7 "Invalid" ;
VAL_ 1159 C_AstRclBwdSw_HU 0 "Default" 1 "Off" 2 "On" 3 "Invalid" ;
VAL_ 1159 C_AstHeightUpSw_HU 0 "Default" 1 "Off" 2 "On" 3 "Invalid" ;
VAL_ 1159 C_AstTiltDnSw_HU 0 "Default" 1 "Off" 2 "On" 3 "Invalid" ;
VAL_ 1159 C_AstTiltUpSw_HU 0 "Default" 1 "Off" 2 "On" 3 "Invalid" ;
VAL_ 1159 C_AstLumbarDefSw_HU 0 "Default" 1 "Off" 2 "On" 3 "Invalid" ;
VAL_ 1159 C_AstLumbarLowSw_HU 0 "Default" 1 "Off" 2 "On" 3 "Invalid" ;
VAL_ 1159 C_AstRclFwdSw_HU 0 "Default" 1 "Off" 2 "On" 3 "Invalid" ;
VAL_ 1159 C_AstLumbarMidSw_HU 0 "Default" 1 "Off" 2 "On" 3 "Invalid" ;
VAL_ 1159 C_AstLumbarUpSw_HU 0 "Default" 1 "Off" 2 "On" 3 "Invalid" ;
VAL_ 1159 C_RRSlideFwdSw_HU 0 "Default" 1 "Off" 2 "On" 3 "Invalid" ;
VAL_ 1159 C_RRSlideBwdSw_HU 0 "Default" 1 "Off" 2 "On" 3 "Invalid" ;
VAL_ 1159 C_RLSlideFwdSw_HU 0 "Default" 1 "Off" 2 "On" 3 "Invalid" ;
VAL_ 1159 C_RLSlideBwdSw_HU 0 "Default" 1 "Off" 2 "On" 3 "Invalid" ;
VAL_ 1159 C_AstSlideBwdSw_HU 0 "Default" 1 "Off" 2 "On" 3 "Invalid" ;
VAL_ 1159 C_AstSlideFwdSw_HU 0 "Default" 1 "Off" 2 "On" 3 "Invalid" ;
VAL_ 1159 C_AstHeightDnSw_HU 0 "Default" 1 "Off" 2 "On" 3 "Invalid" ;
VAL_ 197 C_DrvRclBwdSw_HU 0 "Default" 1 "Off" 2 "On" 3 "Invalid" ;
VAL_ 197 C_DrvSlideFwdSw_HU 0 "Default" 1 "Off" 2 "On" 3 "Invalid" ;
VAL_ 197 C_RLLegSupFwdSw_HU 0 "Default" 1 "Off" 2 "On" 3 "Invalid" ;
VAL_ 197 C_RLLegSupBwdSw_HU 0 "Default" 1 "Off" 2 "On" 3 "Invalid" ;
VAL_ 197 C_DrvSlideBwdSw_HU 0 "Default" 1 "Off" 2 "On" 3 "Invalid" ;
VAL_ 197 C_RLLegSupUpSw_HU 0 "Default" 1 "Off" 2 "On" 3 "Invalid" ;
VAL_ 197 C_RLLegSupDnSw_HU 0 "Default" 1 "Off" 2 "On" 3 "Invalid" ;
VAL_ 197 C_DrvRclFwdSw_HU 0 "Default" 1 "Off" 2 "On" 3 "Invalid" ;
VAL_ 2382595073 DATC_Crc7Val 0 "0x0x0~0xFFFF:CRCValue" 65535 "0x0x0~0xFFFF:CRCValue" ;
VAL_ 2382595073 DATC_AlvCnt7Val 0 "0x0x0~0xFF:AlvCntValue" 255 "0x0x0~0xFF:AlvCntValue" ;
VAL_ 2382595073 DATC_FrDrvBlwDis 0 "OFF" 1 "Blank Display" 2 "1 Step" 3 "2 Step" 4 "3 Step" 5 "4 Step" 6 "5 Step" 7 "6 Step" 8 "7 Step" 9 "8 Step" 10 "BLOWER AUTO" 11 "Reserved" 12 "Reserved" 13 "Reserved" 14 "Reserved" 15 "Error Indicator" ;
VAL_ 2382595073 DATC_FrPsBlwDis 0 "OFF" 1 "Blank Display(Blower ´Ü¼ö ¹ÌÇ¥½Ã, ¿¹)Auto ½Ã)" 2 "1 Step" 3 "2 Step" 4 "3 Step" 5 "4 Step" 6 "5 Step" 7 "6 Step" 8 "7 Step" 9 "8 Step" 10 "BLOWER AUTO" 11 "Reserved" 12 "Reserved" 13 "Reserved" 14 "Reserved" 15 "Error Indicator" ;
VAL_ 2382595073 DATC_HeatDis 0 "Heat OFF" 1 "Heat ON" 2 "Not used" 3 "Error Indicator" ;
VAL_ 2382595073 DATC_EVScrnDis 0 "Deactivated" 1 "Activated" 2 "Not used" 3 "Error Indicator" ;
VAL_ 2382595073 DATC_DrvOnlyDis 0 "Initial (Dual Temp Display)" 1 "Driver Only Status (Only Display Driver Temp)" 2 "Not used" 3 "Error Indicator" ;
VAL_ 2382595073 DATC_DiagCodeDis 0 "Blank Display(Default)" 1 "0x01~0x3FE:0~1023(PHY=(HEX*1.0-1.0))" 1022 "0x01~0x3FE:0~1023(PHY=(HEX*1.0-1.0))" 1023 "Error Indicator" ;
VAL_ 2382595073 DATC_RrChgReqDis 0 "Not requested" 1 "User Input" 2 "Not used" 3 "Error Indicator" ;
VAL_ 2382595073 DATC_RrClmtScrnDis 0 "Deactived" 1 "Actived" 2 "Not used" 3 "Error Indicator" ;
VAL_ 2382595073 DATC_AUTOStep 0 "Default" 1 "OFF" 2 "1st & 2nd & 3rd On (3 Step Type)" 3 "1st & 2nd On (3 Step Type)" 4 "1st On (3 Step Type)" 5 "1st & 2nd On (2 Step Type)" 6 "1st On (2 Step Type)" 7 "Reserved" 8 "Reserved" 9 "Reserved" 10 "Reserved" 11 "Reserved" 12 "Reserved" 13 "Reserved" 14 "Reserved" 15 "Error Indicator" ;
VAL_ 2382595073 DATC_IntakeDis 0 "Default" 1 "REC (Fresh off)" 2 "FRE (REC off)" 3 "Error indicator" ;
VAL_ 2382595073 DATC_MultiAirModSta 0 "Default" 1 "OFF" 2 "ON" 3 "Error Indicator" ;
VAL_ 1167 Bat_dischrg 0 "Flag OFF" 1 "Flag ON" 2 "Reserved" 3 "Reserved" ;
VAL_ 1167 Batt_SoCWarningValue 0 "0x0x0~0x64:0 ~ 100%" 100 "0x0x0~0x64:0 ~ 100%" 101 "0x65~0xFE:Reserved" 254 "0x65~0xFE:Reserved" 255 "Invalid" ;
VAL_ 1167 C_StrgWhlHeatingOpt 0 "Not Applied" 1 "Applied(steering wheel applied)" 2 "Reserved" 3 "Invalid" ;
VAL_ 1167 C_StrgWhlHeatingSWInf 0 "Default" 1 "1step opt(On/Off)" 2 "2step opt(step1,step2,Off)" 3 "Invalid" ;
VAL_ 1167 ICU_BattAutoCutPreWrng 0 "No Warning" 1 "Warning" 2 "Not Used" 3 "Invalid" ;
VAL_ 1167 IGN_AutoOff_WarnSta_CLU 0 "No Warning" 1 "Power Off Warning" 2 "Reserved" 3 "Error Indicator" ;
VAL_ 1167 PDC_BatPwrStateClassA 0 "Not used" 1 "Low power condition for ClassA-load operation during park mode" 2 "High power condition for ClassA-load operation during park mode" 3 "Invaild" ;
VAL_ 1167 PDC_BatPwrStateClassB 0 "Not used" 1 "Low power condition for ClassB-load operation during park mode" 2 "High power condition for ClassB-load operation during park mode" 3 "Invaild" ;
VAL_ 1167 PDC_BatPwrStateClassC 0 "Not used" 1 "Low power condition for ClassC-load operation during park mode" 2 "High power condition for ClassC-load operation during park mode" 3 "Invaild" ;
VAL_ 1167 PLBMAvailableState 0 "Invaild" 1 "PLBM Power is available" ;
VAL_ 1167 IGN_AutoOff_WarnSta 0 "No Warning" 1 "Power Off Warning" 2 "Reserved" 3 "Error Indicator" ;
VAL_ 223 ALBCU_SmartCtrl_1h 0 "Default" 1 "Group1" 2 "Group2" 3 "Group3" 4 "Group4" 5 "Group5" 6 "Group6" 7 "Group7" 8 "Group8" 9 "Group9" 10 "General Group" 11 "Unused" 12 "Unused" 13 "Unused" 14 "Unused" 15 "Invalid" ;
VAL_ 223 ALBCU_SmartCtrl_2h 0 "Default" 1 "Group1" 2 "Group2" 3 "Group3" 4 "Group4" 5 "Group5" 6 "Group6" 7 "Group7" 8 "Group8" 9 "Group9" 10 "General Group" 11 "Unused" 12 "Unused" 13 "Unused" 14 "Unused" 15 "Invalid" ;
VAL_ 223 ALBCU_SmartCtrl_Status 0 "Default" 1 "Start" 2 "Finished" 3 "Stop" 4 "Unused" 5 "Unused" 6 "Unused" 7 "Invalid" ;
VAL_ 1171 RLPSM_SWVerMajor1 0 "0x0x0~0x7F:ASCII Code Value (HEX)" 127 "0x0x0~0x7F:ASCII Code Value (HEX)" ;
VAL_ 1171 RLPSM_SWVerMinor2 0 "0x0x0~0x7F:ASCII Code Value (HEX)" 127 "0x0x0~0x7F:ASCII Code Value (HEX)" ;
VAL_ 1171 RLPSM_SWVerMinor1 0 "0x0x0~0x7F:ASCII Code Value (HEX)" 127 "0x0x0~0x7F:ASCII Code Value (HEX)" ;
VAL_ 1172 RRPSM_SWVerMajor1 0 "0x0x0~0x7F:ASCII Code Value (HEX)" 127 "0x0x0~0x7F:ASCII Code Value (HEX)" ;
VAL_ 1172 RRPSM_SWVerMinor2 0 "0x0x0~0x7F:ASCII Code Value (HEX)" 127 "0x0x0~0x7F:ASCII Code Value (HEX)" ;
VAL_ 1172 RRPSM_SWVerMinor1 0 "0x0x0~0x7F:ASCII Code Value (HEX)" 127 "0x0x0~0x7F:ASCII Code Value (HEX)" ;
VAL_ 1174 Drv_SHVU_SeatOptSta 0 "Init" 1 "Heater only 2step" 2 "Heater only 3step" 3 "Vent only 2step" 4 "Vent only 3step" 5 "Heater and Vent 2step" 6 "Heater and Vent 3step" 7 "Invalid" ;
VAL_ 1174 Drv_SHVU_HtSwHiIndSta 0 "Off(Initial Value)" 1 "On" 2 "RESERVED" 3 "Error Indicator" ;
VAL_ 1174 Drv_SHVU_HtSwMidIndSta 0 "Off(Initial Value)" 1 "On" 2 "RESERVED" 3 "Error Indicator" ;
VAL_ 1174 Drv_SHVU_HtSwLowIndSta 0 "Off(Initial Value)" 1 "On" 2 "RESERVED" 3 "Error Indicator" ;
VAL_ 1174 Drv_SHVU_VntSwHiIndSta 0 "Off(Initial Value)" 1 "On" 2 "RESERVED" 3 "Error Indicator" ;
VAL_ 1174 Drv_SHVU_VntSwMidIndSta 0 "Off(Initial Value)" 1 "On" 2 "RESERVED" 3 "Error Indicator" ;
VAL_ 1174 Drv_SHVU_VntSwLowIndSta 0 "Off(Initial Value)" 1 "On" 2 "RESERVED" 3 "Error Indicator" ;
VAL_ 1174 Drv_SHVU_HtBlcUSMSta 0 "Default" 1 "Normal" 2 "Back 1" 3 "Back 2" 4 "Back 3" 5 "Cush 1" 6 "Cush 2" 7 "Cush 3" 8 "Reserved" 9 "Reserved" 10 "Reserved" 11 "Reserved" 12 "Reserved" 13 "Reserved" 14 "Reserved" 15 "Invalid" ;
VAL_ 1174 Drv_SHVU_SeatHtOperSta 0 "Init" 1 "RESERVED" 2 "Heater & Vent OFF" 3 "Vent Low" 4 "Vent Mid" 5 "Vent High" 6 "Heater Low" 7 "Heater Mid" 8 "Heater High" 9 "RESERVED" 10 "RESERVED" 11 "RESERVED" 12 "RESERVED" 13 "RESERVED" 14 "RESERVED" 15 "Invalid" ;
VAL_ 1174 Drv_SHVU_HtSwHiIndSta_RHD 0 "Off(Initial Value)" 1 "On" 2 "RESERVED" 3 "Error Indicator" ;
VAL_ 1174 Drv_SHVU_HtSwMidIndSta_RHD 0 "Off(Initial Value)" 1 "On" 2 "RESERVED" 3 "Error Indicator" ;
VAL_ 1174 Drv_SHVU_HtSwLowIndSta_RHD 0 "Off(Initial Value)" 1 "On" 2 "RESERVED" 3 "Error Indicator" ;
VAL_ 1174 Drv_SHVU_VntSwHiIndSta_RHD 0 "Off(Initial Value)" 1 "On" 2 "RESERVED" 3 "Error Indicator" ;
VAL_ 1174 Drv_SHVU_VntSwMidIndSta_RHD 0 "Off(Initial Value)" 1 "On" 2 "RESERVED" 3 "Error Indicator" ;
VAL_ 1174 Drv_SHVU_VntSwLowIndSta_RHD 0 "Off(Initial Value)" 1 "On" 2 "RESERVED" 3 "Error Indicator" ;
VAL_ 1174 Drv_SHVU_HtBlcUSMSta_RHD 0 "Default" 1 "Normal" 2 "Back 1" 3 "Back 2" 4 "Back 3" 5 "Cush 1" 6 "Cush 2" 7 "Cush 3" 8 "Reserved" 9 "Reserved" 10 "Reserved" 11 "Reserved" 12 "Reserved" 13 "Reserved" 14 "Reserved" 15 "Invalid" ;
VAL_ 1179 Drv_SHVU_SeatEcoSta 0 "Off(Initial Value)" 1 "On" 2 "RESERVED" 3 "Error Indicator" ;
VAL_ 1179 SHVU_Drv_Beep1Sound 0 "Beep1 mode Off" 1 "Beep1 mode On" 2 "RESERVED" 3 "Invalid" ;
VAL_ 1179 SHVU_CtrlScreenDis 0 "Default" 1 "Screen Display On" 2 "RESERVED" 3 "Invalid" ;
VAL_ 1180 SHVU_Ast_Beep1Sound 0 "Beep1 mode Off" 1 "Beep1 mode On" 2 "Unused" 3 "Invalid" ;
VAL_ 1180 Ast_SHVU_SeatEcoSta 0 "Off(Initial Value)" 1 "On" 2 "Not Used" 3 "Error Indicator" ;
VAL_ 208 RR_SHVU_DTCdisplay 0 "DTC is not exist(Fail is not exist)" 1 "IGN2 Fuse Open Detection" 2 "Switch Input Detection at Same Time" 3 "NTC/Heating wire Open Detection" 4 "NTC+/NTC- Terminal Short Detection" 5 "NTC+/Heater+ Terminal Short Detection" 6 "NTC+/Heater-, Heater+/Heater-, Heater+/NTC- Terminal Short Detection" 7 "NTC+/Heater- Wiring Short Detection" 8 "NTC+/Heater-, Heater+/Heater-, Heater+/NTC- Wiring Short Detection" 9 "Target Temperature Dissatisfied" 10 "Blower+/Blower- Short, Blower+/Blower Speed, Blower-/Blower Speed Wiring Short Detection" 11 "Blower+/Blower RPM, Blower-/Blower RPM, Blower Speed/Blower RPM Short Detection" 12 "Blower+, Blower-, Blower Speed Signal open Detection" 13 "Blower RPM signal Open Detection" 14 "0xE~0xFD:Unused" 253 "0xE~0xFD:Unused" 254 "No Display" 255 "Invalid" ;
VAL_ 208 RR_SHVU_DiagMode 0 "Default" 1 "DTC Mode" 2 "Normal Mode" 3 "Invalid" ;
VAL_ 1181 RL_SHVU_SeatEcoSta 0 "Off(Initial Value)" 1 "On" 2 "RESERVED" 3 "Error Indicator" ;
VAL_ 1182 RR_SHVU_SeatEcoSta 0 "Off(Initial Value)" 1 "On" 2 "RESERVED" 3 "Error Indicator" ;
VAL_ 1186 C_RemoteWdwCMDHU 0 "None" 1 "Auto Up" 2 "Auto Down" 3 "invalid" ;
VAL_ 1186 HU_CDMOpenCmd 0 "Default" 1 "CDM Open" 2 "CDM Close" 3 "Invalid" ;
VAL_ 1186 C_PreCrankReq 0 "Default" 1 "Req On" 2 "Not Support" 3 "Invalid" ;
VAL_ 1186 C_TeleAstSeatOpCmdIBOX 0 "Init" 1 "Unused" 2 "Seat Heat&Vent OFF" 3 "Seat_Vent_Low" 4 "Seat_Vent_Mid" 5 "Seat_Vent_High" 6 "Seat_Heat_Low" 7 "Seat_Heat_Mid" 8 "Seat_Heat_High" 9 "Unused" 10 "Unused" 11 "Unused" 12 "Unused" 13 "Unused" 14 "Unused" 15 "Invalid" ;
VAL_ 1186 C_TeleDrvSeatOpCmdIBOX 0 "Init" 1 "Unused" 2 "Seat Heat&Vent OFF" 3 "Seat_Vent_Low" 4 "Seat_Vent_Mid" 5 "Seat_Vent_High" 6 "Seat_Heat_Low" 7 "Seat_Heat_Mid" 8 "Seat_Heat_High" 9 "Unused" 10 "Unused" 11 "Unused" 12 "Unused" 13 "Unused" 14 "Unused" 15 "Invalid" ;
VAL_ 1186 C_TeleRRSeatOpCmdIBOX 0 "Init" 1 "Unused" 2 "Seat Heat&Vent OFF" 3 "Seat_Vent_Low" 4 "Seat_Vent_Mid" 5 "Seat_Vent_High" 6 "Seat_Heat_Low" 7 "Seat_Heat_Mid" 8 "Seat_Heat_High" 9 "Unused" 10 "Unused" 11 "Unused" 12 "Unused" 13 "Unused" 14 "Unused" 15 "Invalid" ;
VAL_ 1186 C_TeleRLSeatOpCmdIBOX 0 "Init" 1 "Unused" 2 "Seat Heat&Vent OFF" 3 "Seat_Vent_Low" 4 "Seat_Vent_Mid" 5 "Seat_Vent_High" 6 "Seat_Heat_Low" 7 "Seat_Heat_Mid" 8 "Seat_Heat_High" 9 "Unused" 10 "Unused" 11 "Unused" 12 "Unused" 13 "Unused" 14 "Unused" 15 "Invalid" ;
VAL_ 1185 C_AstWindowCmdAVN 0 "No action" 1 "Manual Down" 2 "Manual Up" 3 "25% Open" 4 "50%Open" 5 "Auto Down" 6 "Auto Up" 7 "15% Open" 8 "Unused" 9 "Unused" 10 "Unused" 11 "Unused" 12 "Unused" 13 "Unused" 14 "Unused" 15 "Invalid" ;
VAL_ 1185 C_RrDefoggerCmdAVN 0 "Off" 1 "On" 2 "Reserved" 3 "Invalid" ;
VAL_ 1185 C_RrBlindCmdAVN 0 "No Action" 1 "Blind Auto Open" 2 "Blind Auto Close" 3 "Invalid" ;
VAL_ 1185 C_RrGlassCmdAVN 0 "No Action" 1 "Glass Auto Open" 2 "Glass Auto Close" 3 "Invalid" ;
VAL_ 1185 C_RRWindowCmdAVN 0 "No action" 1 "Manual Down" 2 "Manual Up" 3 "25% Open" 4 "50% Open" 5 "Auto Down" 6 "Auto Up" 7 "15% Open" 8 "Unused" 9 "Unused" 10 "Unused" 11 "Unused" 12 "Unused" 13 "Unused" 14 "Unused" 15 "Invalid" ;
VAL_ 1185 C_RLWindowCmdAVN 0 "No action" 1 "Manual Down" 2 "Manual Up" 3 "25% Open" 4 "50% Open" 5 "Auto Down" 6 "Auto UP" 7 "15% Open" 8 "Unused" 9 "Unused" 10 "Unused" 11 "Unused" 12 "Unused" 13 "Unused" 14 "Unused" 15 "Invalid" ;
VAL_ 1185 C_BlindCmdAVN 0 "No Action" 1 "R_Blind Auto Open" 2 "R_Blind Auto Close" 3 "Stop" 4 "reserved" 5 "reserved" 6 "reserved" 7 "Invalid" ;
VAL_ 1185 C_GlassCmdAVN 0 "No Action" 1 "Glass Auto Open" 2 "Glass Auto Close" 3 "Glass Auto Tilt Up" 4 "Stop" 5 "reserved" 6 "reserved" 7 "Invalid" ;
VAL_ 1185 C_DrvWindowCmdAVN 0 "No action" 1 "Manual Down" 2 "Manual Up" 3 "25% Open" 4 "50% Open" 5 "Auto Down" 6 "Auto Up" 7 "15% Open" 8 "Unused" 9 "Unused" 10 "Unused" 11 "Unused" 12 "Unused" 13 "Unused" 14 "Unused" 15 "Invalid" ;
VAL_ 1185 C_PTGCNTLCmdAVN 0 "Close" 1 "Open" 2 "Reserved" 3 "Invalid" ;
VAL_ 1189 C_RLTiltUpSw_HU 0 "Default" 1 "Off" 2 "On" 3 "Invalid" ;
VAL_ 1189 C_RRTiltDownSw_HU 0 "Default" 1 "Off" 2 "On" 3 "Invalid" ;
VAL_ 1189 C_RRTiltUpSw_HU 0 "Default" 1 "Off" 2 "On" 3 "Invalid" ;
VAL_ 1189 C_RLRclBwdSw_HU 0 "Default" 1 "Off" 2 "On" 3 "Invalid" ;
VAL_ 1189 C_RLRclFwdSw_HU 0 "Default" 1 "Off" 2 "On" 3 "Invalid" ;
VAL_ 1189 C_RLFldSw_HU 0 "Default" 1 "Off" 2 "On" 3 "Invalid" ;
VAL_ 1189 C_RRRclBwdSw_HU 0 "Default" 1 "Off" 2 "On" 3 "Invalid" ;
VAL_ 1189 C_RRRclFwdSw_HU 0 "Default" 1 "Off" 2 "On" 3 "Invalid" ;
VAL_ 1189 C_TLHrestFldSw_HU 0 "Default" 1 "Off" 2 "On" 3 "Invalid" ;
VAL_ 1189 C_TRHrestFldSw_HU 0 "default" 1 "OFF" 2 "ON" 3 "Invalid" ;
VAL_ 1189 C_RLRlxSW_HU 0 "Default" 1 "Off" 2 "On" 3 "Invalid" ;
VAL_ 1189 C_RRRlxSW_HU 0 "Default" 1 "Off" 2 "On" 3 "Invalid" ;
VAL_ 1189 C_TLFldSw_HU 0 "Default" 1 "Off" 2 "On" 3 "Invalid" ;
VAL_ 1189 C_TRFldSw_HU 0 "Default" 1 "Off" 2 "On" 3 "Invalid" ;
VAL_ 1189 C_RRFldSw_HU 0 "Default" 1 "Off" 2 "On" 3 "Invalid" ;
VAL_ 1189 C_RLTiltDownSw_HU 0 "Default" 1 "Off" 2 "On" 3 "Invalid" ;
VAL_ 1195 CF_AVN_CluWelcomeSnd 0 "Default" 1 "Off" 2 "On" 3 "Invalid" ;
VAL_ 1195 CF_AVN_CluTransmissionDisp 0 "Default" 1 "Off" 2 "On" 3 "Invalid" ;
VAL_ 1195 CF_AVN_CluWiperLight 0 "Default" 1 "Off" 2 "On" 3 "Invalid" ;
VAL_ 1195 CF_AVN_CluRoadInfoGuide 0 "Default" 1 "Off" 2 "On" 3 "Invalid" ;
VAL_ 1195 CF_AVN_CluUserSettingPeriod 0 "0~99month" 1 "0~99month" 2 "0~99month" 3 "0~99month" 4 "0~99month" 5 "0~99month" 6 "0~99month" 7 "0~99month" 8 "0~99month" 9 "0~99month" 10 "0~99month" 11 "0~99month" 12 "0~99month" 13 "0~99month" 14 "0~99month" 15 "0~99month" 16 "0~99month" 17 "0~99month" 18 "0~99month" 19 "0~99month" 20 "0~99month" 21 "0~99month" 22 "0~99month" 23 "0~99month" 24 "0~99month" 25 "0~99month" 26 "0~99month" 27 "0~99month" 28 "0~99month" 29 "0~99month" 30 "0~99month" 31 "0~99month" 32 "0~99month" 33 "0~99month" 34 "0~99month" 35 "0~99month" 36 "0~99month" 37 "0~99month" 38 "0~99month" 39 "0~99month" 40 "0~99month" 41 "0~99month" 42 "0~99month" 43 "0~99month" 44 "0~99month" 45 "0~99month" 46 "0~99month" 47 "0~99month" 48 "0~99month" 49 "0~99month" 50 "0~99month" 51 "0~99month" 52 "0~99month" 53 "0~99month" 54 "0~99month" 55 "0~99month" 56 "0~99month" 57 "0~99month" 58 "0~99month" 59 "0~99month" 60 "0~99month" 61 "0~99month" 62 "0~99month" 63 "0~99month" 64 "0~99month" 65 "0~99month" 66 "0~99month" 67 "0~99month" 68 "0~99month" 69 "0~99month" 70 "0~99month" 71 "0~99month" 72 "0~99month" 73 "0~99month" 74 "0~99month" 75 "0~99month" 76 "0~99month" 77 "0~99month" 78 "0~99month" 79 "0~99month" 80 "0~99month" 81 "0~99month" 82 "0~99month" 83 "0~99month" 84 "0~99month" 85 "0~99month" 86 "0~99month" 87 "0~99month" 88 "0~99month" 89 "0~99month" 90 "0~99month" 91 "0~99month" 92 "0~99month" 93 "0~99month" 94 "0~99month" 95 "0~99month" 96 "0~99month" 97 "0~99month" 98 "0~99month" 99 "0~99month" 100 "Reserved" 101 "Reserved" 102 "Reserved" 103 "Reserved" 104 "Reserved" 105 "Reserved" 106 "Reserved" 107 "Reserved" 108 "Reserved" 109 "Reserved" 110 "Reserved" 111 "Reserved" 112 "Reserved" 113 "Reserved" 114 "Reserved" 115 "Reserved" 116 "Reserved" 117 "Reserved" 118 "Reserved" 119 "Reserved" 120 "Reserved" 121 "Reserved" 122 "Reserved" 123 "Reserved" 124 "Reserved" 125 "Reserved" 126 "Reserved" 127 "Invalid" ;
VAL_ 1195 CF_AVN_CluFuelEconUnit_mi 0 "Default" 1 "US gallon" 2 "UK gallon" 3 "Reserved" ;
VAL_ 1195 CF_AVN_CluFuelEconUnit_km 0 "Default" 1 "km/L, km/kg, km/kWh" 2 "L/100km, kg/100km, kWh/100km" 3 "Reserved" ;
VAL_ 1195 CF_AVN_CluUserSettingDistance 0 "0x0x0~0x1869F:0~9999km_mi" 99999 "0x0x0~0x1869F:0~9999km_mi" 131071 "Invalid" ;
VAL_ 1195 CF_AVN_CluRheostatLvl 0 "Reserved" 1 "Step 1" 2 "Step 2" 3 "Step 3" 4 "Step 4" 5 "Step 5" 6 "Step 6" 7 "Step 7" 8 "Step 8" 9 "Step 9" 10 "Step 10" 11 "Step 11" 12 "Step 12" 13 "Step 13" 14 "Step 14" 15 "Step 15" 16 "Step 16" 17 "Step 17" 18 "Step 18" 19 "Step 19" 20 "Step 20(Reset Value)" 21 "Step 21(Detent)" 22 "Reserved" 23 "Reserved" 24 "Reserved" 25 "Reserved" 26 "Reserved" 27 "Reserved" 28 "Reserved" 29 "Reserved" 30 "Reserved" 31 "Invalid" ;
VAL_ 1195 CF_AVN_EVReset 0 "Default" 1 "USM Reset" 2 "Reserved" 3 "Invalid" ;
VAL_ 1195 CF_AVN_UnitReset 0 "Default" 1 "Unit Reset" 2 "Reserved" 3 "Invalid" ;
VAL_ 1195 CF_AVN_CluServiceReminderReset 0 "Default" 1 "Service Reminder Reset" 2 "Reserved" 3 "Invalid" ;
VAL_ 1195 CF_AVN_CluUSMReset 0 "Default" 1 "USM Reset" 2 "Reserved" 3 "Invalid" ;
VAL_ 1195 CF_AVN_CluServiceReminderSet 0 "Default" 1 "Off" 2 "On" 3 "Invalid" ;
VAL_ 1193 C_PTGMNValueSet 0 "Default" 1 "Power Mode" 2 "Manual Mode" 3 "Invalid" ;
VAL_ 1193 CF_AVN_PSMNValueSet 0 "Default" 1 "Off(Disable)" 2 "50mm On(Enable)" 3 "75mm On(Enable)" 4 "Reserved" 5 "Reserved" 6 "Reserved" 7 "Invalid" ;
VAL_ 1193 C_HfreeTrunkTgNValueSet 0 "Default" 1 "HandsFree Off" 2 "HandsFree On" 3 "Reserved" 4 "Invalid" 5 "Reserved" 6 "Reserved" 7 "Reserved" ;
VAL_ 1193 CF_AVN_TrfChgSet 0 "Default" 1 "Disable(Off)" 2 "Enable(On)" 3 "Invalid" ;
VAL_ 1193 CF_AVN_SCMNValueSet 0 "Default" 1 "Steering Off" 2 "Steering On" 3 "Invalid" ;
VAL_ 1193 CF_AVN_ADrUNValueSet 0 "Default" 1 "Off" 2 "Key Out On(All Doors)" 3 "Shift Lever On(All Doors)" 4 "Override" 5 "Invalid" 6 "Key Out On(Driver Door)" 7 "Shift Lever On(Driver Door)" ;
VAL_ 1193 CF_AVN_OTTurnNValueSet 0 "Default" 1 "One Touch Turn Off" 2 "3 Flashing" 3 "5 Flashing" 4 "7 Flashing" 5 "Invalid" 6 "Reserved" 7 "Reserved" ;
VAL_ 1193 CF_Gway_WPCNValueSet 0 "Default" 1 "Off(Disable)" 2 "On(Enable)" 3 "Invalid" ;
VAL_ 1193 C_AVN_RearWiperNValueSet 0 "Default" 1 "Rear Wiper(Reverse) Off" 2 "Rear Wiper(Reverse) On" 3 "Invalid" ;
VAL_ 1193 C_UnlockWelocomeNValueSet 0 "Default" 1 "Off" 2 "On" 3 "Invalid" ;
VAL_ 1193 C_SmartWelocomeNValueSet 0 "Default" 1 "Off" 2 "On" 3 "Invalid" ;
VAL_ 1193 CF_AVN_PTGSpeedNValueSet 0 "Default" 1 "Fast" 2 "Slow" 3 "Invalid" ;
VAL_ 1193 CR_Datc_DRSeatWheel_USM_Set 0 "Default" 1 "Off" 2 "On" 3 "Invalid" ;
VAL_ 1193 CF_AVN_TTUnlockNValueSet 0 "Default" 1 "Off" 2 "On" 3 "Invalid" ;
VAL_ 1193 CF_Gway_RWPCNValueSet 0 "Default" 1 "Off" 2 "On" 3 "Invalid" ;
VAL_ 1193 CF_Avn_HAPTICWARNINGNValueSet 0 "Default" 1 "Weak" 2 "Medium" 3 "Strong" 4 "Reserved" 5 "Reserved" 6 "Off" 7 "Invalid" ;
VAL_ 1193 CR_Datc_DRSeatHeat_USM_Set 0 "Default" 1 "Off" 2 "On" 3 "Invalid" ;
VAL_ 1193 C_WALNValueSet 0 "Default" 1 "Off" 2 "On" 3 "Invalid" ;
VAL_ 1193 C_ApprUnlockNValue 0 "Defualt" 1 "Approach Unlock OFF" 2 "Approach Unlock ON" 3 "Invalid" ;
VAL_ 1193 CF_AVN_EscortHLNValueSet 0 "Default" 1 "Escort Off" 2 "Escort On" 3 "Invalid" ;
VAL_ 2365803012 DATC_Opt_Sys 0 "0x0x00000000~0xFFFFFFFF:See Description" 2147483647 "0x0x00000000~0xFFFFFFFF:See Description" ;
VAL_ 2365803012 DATC_Opt_Func 0 "0x0x00000000~0xFFFFFFFF:See Description" 2147483647 "0x0x00000000~0xFFFFFFFF:See Description" ;
VAL_ 2365803011 DATC_Typ_All_3 0 "0x0x0000~0xFFFF:See Description" 65535 "0x0x0000~0xFFFF:See Description" ;
VAL_ 2365803011 DATC_Typ_All_4 0 "0x0x0000~0xFFFF:See Description" 65535 "0x0x0000~0xFFFF:See Description" ;
VAL_ 2365803011 DATC_Typ_All_5 0 "0x0x0000~0xFFFF:See Description" 65535 "0x0x0000~0xFFFF:See Description" ;
VAL_ 2365803011 DATC_Typ_All_6 0 "0x0x0000~0xFFFF:See Description" 65535 "0x0x0000~0xFFFF:See Description" ;
VAL_ 2365803010 DATC_SwVer4 0 "0x0x00~0x7E:ASCII value" 126 "0x0x00~0x7E:ASCII value" 127 "Invalid" ;
VAL_ 2365803010 DATC_Typ_All_1 0 "0x0x0000~0xFFFF:See Description" 65535 "0x0x0000~0xFFFF:See Description" ;
VAL_ 2365803010 DATC_Typ_All_2 0 "0x0x0000~0xFFFF:See Description" 65535 "0x0x0000~0xFFFF:See Description" ;
VAL_ 2365803010 DATC_SwVer5 0 "0x0x00~0x7E:ASCII value" 126 "0x0x00~0x7E:ASCII value" 127 "Invalid" ;
VAL_ 2365803009 DATC_Crc16Val 0 "0x0x0~0xFFFF:CRCValue" 65535 "0x0x0~0xFFFF:CRCValue" ;
VAL_ 2365803009 DATC_AlvCnt16Val 0 "0x0x0~0xFF:AlvCntValue" 255 "0x0x0~0xFF:AlvCntValue" ;
VAL_ 2365803009 DATC_SwVer1 0 "0x0x00~0x7E:ASCII value" 126 "0x0x00~0x7E:ASCII value" 127 "Invalid" ;
VAL_ 2365803009 DATC_SwVer2 0 "0x0x00~0x7E:ASCII value" 126 "0x0x00~0x7E:ASCII value" 127 "Invalid" ;
VAL_ 2365803009 DATC_SwVer3 0 "0x0x00~0x7E:ASCII value" 126 "0x0x00~0x7E:ASCII value" 127 "Invalid" ;
VAL_ 2365803009 DATC_Typ2 0 "0x0x00~0xFF: applied options (See Description)" 255 "0x0x00~0xFF: applied options (See Description)" ;
VAL_ 1196 C_HCIMSWeightNValueSet 0 "Default" 1 "Under 49.4kg" 2 "49.5~59.4kg" 3 "59.5~69.4kg" 4 "69.5~79.4kg" 5 "79.5~89.4kg" 6 "89.5~99.4kg" 7 "99.5~109.4kg" 8 "109.5~119.4kg" 9 "More than 119.5kg" 10 "Reserved" 11 "Reserved" 12 "Reserved" 13 "Reserved" 14 "Reserved" 15 "Invalid" ;
VAL_ 1196 C_HCIMSSitHeightNValueSet 0 "Default" 1 "Tall" 2 "Middle" 3 "Short" 4 "Reserved" 5 "Reserved" 6 "Reserved" 7 "Reserved" 8 "Reserved" 9 "Reserved" 10 "Reserved" 11 "Reserved" 12 "Reserved" 13 "Reserved" 14 "Reserved" 15 "Invalid" ;
VAL_ 1196 CF_AVN_BodySpprtSet 0 "Default" 1 "Off" 2 "On" 3 "Invalid" ;
VAL_ 1196 CF_AVN_AirSptTimeNValueSet 0 "Default" 1 "Short" 2 "Normal" 3 "Long" 4 "Reserved" 5 "Reserved" 6 "Reserved" 7 "Invalid" ;
VAL_ 1196 CF_AVN_AirSptStrNValue 0 "Default" 1 "Normal" 2 "Intense" 3 "Invalid" ;
VAL_ 1196 CF_AVN_SeatDrvModNValueSet 0 "Default" 1 "Off" 2 "On" 3 "Invalid" ;
VAL_ 1196 C_HCIMSHeightNvalueSet 0 "Default" 1 "Less than 147.5cm" 2 "147.5~152.4cm" 3 "152.5~157.4cm" 4 "157.5~162.4cm" 5 "162.5~167.4cm" 6 "167.5~172.4cm" 7 "172.5~177.4cm" 8 "177.5~182.4cm" 9 "182.5~187.4cm" 10 "187.5~192.4cm" 11 "192.5~197.4cm" 12 "more than 197.5cm" 13 "Reserved" 14 "Reserved" 15 "Invalid" ;
VAL_ 1196 CF_AVN_CushSoftNValueSet 0 "Default" 1 "Soft" 2 "Mid" 3 "Hard" 4 "Reserved" 5 "Reserved" 6 "Off" 7 "Invalid" ;
VAL_ 1196 C_SmrtSldngDrNValueSet 0 "Default" 1 "Off" 2 "On" 3 "Reserved" 4 "Reserved" 5 "Reserved" 6 "Reserved" 7 "Invalid" ;
VAL_ 1196 CF_AVN_TurboPressureUnit 0 "Default" 1 "Psi" 2 "kPa" 3 "bar" 4 "Reserved" 5 "Reserved" 6 "Reserved" 7 "Invalid" ;
VAL_ 1196 CF_AVN_CluTorqueUnit 0 "Default" 1 "Nm" 2 "lb_ft" 3 "Invalid" ;
VAL_ 1196 CF_AVN_HCIMSButtonCommand 0 "Default" 1 "Health Care IMS Exit" 2 "Detail View" 3 "Move to recommend position" 4 "Current position Analysis" 5 "Move to setting page" 6 "Save view" 7 "IMS1 saved" 8 "IMS2 saved" 9 "Summary view" 10 "Smart IMS On" 11 "Reserved" 12 "Reserved" 13 "Reserved" 14 "Reserved" 15 "Invalid" ;
VAL_ 255 BCM_Crc20Val 0 "0x0x0~0xFF:CRCValue" 255 "0x0x0~0xFF:CRCValue" ;
VAL_ 255 BCM_AlvCnt20Val 0 "AlvCntValue" 1 "AlvCntValue" 2 "AlvCntValue" 3 "AlvCntValue" 4 "AlvCntValue" 5 "AlvCntValue" 6 "AlvCntValue" 7 "AlvCntValue" 8 "AlvCntValue" 9 "AlvCntValue" 10 "AlvCntValue" 11 "AlvCntValue" 12 "AlvCntValue" 13 "AlvCntValue" 14 "AlvCntValue" 15 "AlvCntValue" ;
VAL_ 255 BckGls_RrGlsHtdOnCmd 0 "Off" 1 "On" 2 "Not Used" 3 "Error Indicator" ;
VAL_ 255 Wndshld_FrtGlsHtdOnCmd 0 "Off" 1 "On" 2 "Not Used" 3 "Error Indicator" ;
VAL_ 255 Mirror_MirFldOpt 0 "Not Applied" 1 "Applied" 2 "Not Used" 3 "Error Indicator" ;
VAL_ 255 Window_AsstPwrWdwSunroofEnblSta 0 "Disable" 1 "Enable" 2 "Not Used" 3 "Error Indicator" ;
VAL_ 255 Window_RrPwrWdwEnblSta 0 "Off" 1 "On" 2 "Not Used" 3 "Error Indicator" ;
VAL_ 255 Window_RrPwrWdwLkInd 0 "Off" 1 "On" 2 "Not Used" 3 "Error Indicator" ;
VAL_ 255 Window_DrvPwrWdwCmd 0 "NoAction" 1 "ManualUp" 2 "ManualDown" 3 "Error Indicator" ;
VAL_ 255 Window_AsstPwrWdwCmd 0 "NoAction" 1 "ManualUp" 2 "ManualDown" 3 "Error Indicator" ;
VAL_ 255 Window_RrLftPwrWdwCmd 0 "NoAction" 1 "ManualUp" 2 "ManualDown" 3 "Error Indicator" ;
VAL_ 255 Window_RrRtPwrWdwCmd 0 "NoAction" 1 "ManualUp" 2 "ManualDown" 3 "Error Indicator" ;
VAL_ 255 Mirror_FldUnfldCmd 0 "Off" 1 "Fold" 2 "Unfold" 3 "Error Indicator" ;
VAL_ 255 Mirror_FldCtrlSta 0 "Off" 1 "Fldng" 2 "Fld" 3 "Error Indicator" ;
VAL_ 255 Mirror_UnFldCtrlSta 0 "Off" 1 "UnFldng" 2 "UnFld" 3 "Error Indicator" ;
VAL_ 255 Mirror_PosMnlCmd 0 "Off" 1 "Up" 2 "Down" 3 "Left" 4 "Right" 5 "Not Used" 6 "Not Used" 7 "Error Indicator" ;
VAL_ 255 Mirror_SelSwIndCmd 0 "Off" 1 "Left" 2 "Neutral" 3 "Right" 4 "Not Used" 5 "Not Used" 6 "Not Used" 7 "Error Indicator" ;
VAL_ 255 BCM_SafetyWdwOptTyp2 0 "None" 1 "Driver Safety Window" 2 "Front Safety Window" 3 "All Safety Window" 4 "Not Used" 5 "Not Used" 6 "Not Used" 7 "Error Indicator" ;
VAL_ 255 Mirror_LHOSMirPlyBckSta 0 "Stop" 1 "Play 1" 2 "Play 2" 3 "Play 3" 4 "Smart IMS" 5 "Profile 1" 6 "Profile 2" 7 "Guest" 8 "Not Used" 9 "Not Used" 10 "Not Used" 11 "Not Used" 12 "Not Used" 13 "Not Used" 14 "Not Used" 15 "Error Indicator" ;
VAL_ 255 Mirror_RHOSMirPlyBckSta 0 "Stop" 1 "Play 1" 2 "Play 2" 3 "Play 3" 4 "Smart IMS" 5 "Profile 1" 6 "Profile 2" 7 "Guest" 8 "Not Used" 9 "Not Used" 10 "Not Used" 11 "Not Used" 12 "Not Used" 13 "Not Used" 14 "Not Used" 15 "Error Indicator" ;
VAL_ 255 Mirror_SelSwSta 0 "Off" 1 "Left" 2 "Neutral" 3 "Right" 4 "Not Used" 5 "Not Used" 6 "Not Used" 7 "Error Indicator" ;
VAL_ 255 BckGls_RrGlsHtdOpt 0 "Not Applied" 1 "Applied" 2 "Not Used" 3 "Error Indicator" ;
VAL_ 2328015105 ADAS_CMD_Crc34Val 0 "0x0x0~0xFFFF:CRCValue" 65535 "0x0x0~0xFFFF:CRCValue" ;
VAL_ 2328015105 ADAS_CMD_AlvCnt34Val 0 "0x0x0~0xFF:AlvCntValue" 255 "0x0x0~0xFF:AlvCntValue" ;
VAL_ 2328015105 HDP_RDD_WarnSta 0 "No request" 1 "MRM Warning Request" 2 "MRM Stop" 3 "EM Warning Request" 4 "RESERVED" 5 "RESERVED" 6 "RESERVED" 7 "RESERVED" ;
VAL_ 2328015105 HDP_RDD_LongAsstCtrlSta 0 "Not Active" 1 "MRM Longitudinal Control Active" 2 "Reserved" 3 "Reserved" ;
VAL_ 2328015105 HDP_RDD_HzrdLmpReqSta 0 "Hazard Lamp Inactive Request" 1 "Hazard Lamp Active Request" 2 "Reserved" 3 "Reserved" ;
VAL_ 2328015105 HDP_RDD_ACIActvDispSta 0 "INIT" 1 "INACTIVE" 2 "ACTIVE30(ACTIVE)" 3 "ACTIVE33(Redundancy)" ;
VAL_ 2328015106 HDP_RDD_EMStbltActvReqSta 0 "Release No alert" 1 "Pre-crash full retraction" 2 "Haptic warning" 3 "Reserved" 4 "Reserved" 5 "Reserved" 6 "Reserved" 7 "Reserved" ;
